VERSION ""

NS_ :

BS_:

BU_: TelemetryNode Master SENSOR PDU CLU BRAKE MLU_1 MLU_2 MLU_3 MLU_4 MLU_5 MLU_6

BO_ 3 SENSOR_IMU_ACCEL_Y: 4 SENSOR
 SG_ SENSOR_IMU_ACCEL_Y_SIGNAL : 0|32@1- (1,0) [-2147483648|2147483647] "" Vector__XXX

BO_ 1 SENSOR_Ready: 0 Vector__XXX

BO_ 0 SENSOR_HELLO_WORLD: 1 Vector__XXX

BO_ 2 CANzero_NMT: 4 Master
 SG_ CANzero_NMT_Node : 16|16@1+ (1,0) [0|63] ""  SENSOR,PDU,CLU,BRAKE,MLU_1,MLU_2,MLU_3,MLU_4,MLU_5,MLU_6
 SG_ CANzero_NMT_State : 0|16@1+ (1,0) [0|0] ""  SENSOR,PDU,CLU,BRAKE,MLU_1,MLU_2,MLU_3,MLU_4,MLU_5,MLU_6

BO_ 122 CANzero_Sync: 0 Master

BO_ 123 CANzero_Timestamp: 0 Master

BO_ 129 SENSOR_EMCY: 4 SENSOR
 SG_ SENSOR_E11_ANY_MLU_Timeout : 23|1@1+ (1,0) [0|0] ""  Master,TelemetryNode
 SG_ SENSOR_E10_MLU6_Timeout : 22|1@1+ (1,0) [0|0] ""  Master,TelemetryNode
 SG_ SENSOR_E9_MLU5_Timeout : 21|1@1+ (1,0) [0|0] ""  Master,TelemetryNode
 SG_ SENSOR_E8_MLU4_Timeout : 20|1@1+ (1,0) [0|0] ""  Master,TelemetryNode
 SG_ SENSOR_E7_MLU3_Timeout : 19|1@1+ (1,0) [0|0] ""  Master,TelemetryNode
 SG_ SENSOR_E6_MLU2_Timeout : 18|1@1+ (1,0) [0|0] ""  Master,TelemetryNode
 SG_ SENSOR_E5_MLU1_Timeout : 17|1@1+ (1,0) [0|0] ""  Master,TelemetryNode
 SG_ SENSOR_E4_CLU_Timeout : 16|1@1+ (1,0) [0|0] ""  Master,TelemetryNode
 SG_ SENSOR_E3_PDU_Timeout : 15|1@1+ (1,0) [0|0] ""  Master,TelemetryNode
 SG_ SENSOR_E2_BRAKE_Timeout : 14|1@1+ (1,0) [0|0] ""  Master,TelemetryNode
 SG_ SENSOR_E1_StateTransitionError : 13|1@1+ (1,0) [0|0] ""  Master,TelemetryNode
 SG_ SENSOR_E0_OtherError : 12|1@1+ (1,0) [0|0] ""  Master,TelemetryNode
 SG_ SENSOR_W4_PressureSensorPlausibi : 4|1@1+ (1,0) [0|0] ""  Master,TelemetryNode
 SG_ SENSOR_W3_TemperaturSensorPlausi : 3|1@1+ (1,0) [0|0] ""  Master,TelemetryNode
 SG_ SENSOR_W2_OnBoardOvervoltage : 2|1@1+ (1,0) [0|0] ""  Master,TelemetryNode
 SG_ SENSOR_W1_OnBoardOverheat : 1|1@1+ (1,0) [0|0] ""  Master,TelemetryNode
 SG_ SENSOR_W0_OtherWarning : 0|1@1+ (1,0) [0|0] ""  Master,TelemetryNode

BO_ 385 SENSOR_TX_PDO1: 0 SENSOR

BO_ 449 SENSOR_RX_PDO1: 0 Vector__XXX

BO_ 513 SENSOR_TX_PDO2: 0 SENSOR

BO_ 577 SENSOR_RX_PDO2: 0 Vector__XXX

BO_ 641 SENSOR_TX_PDO3: 0 SENSOR

BO_ 705 SENSOR_RX_PDO3: 0 Vector__XXX

BO_ 769 SENSOR_TX_PDO4: 0 SENSOR

BO_ 833 SENSOR_RX_PDO4: 0 Vector__XXX

BO_ 897 SENSOR_TX_PDO5: 0 SENSOR

BO_ 961 SENSOR_TX_PDO6: 0 SENSOR

BO_ 1025 SENSOR_TX_PDO7: 0 SENSOR

BO_ 1089 SENSOR_TX_PDO8: 0 SENSOR

BO_ 1153 SENSOR_TX_PDO9: 0 SENSOR

BO_ 1217 SENSOR_TX_PDO10: 0 SENSOR

BO_ 1281 SENSOR_TX_PDO11: 0 SENSOR

BO_ 1345 SENSOR_TX_PDO12: 0 SENSOR

BO_ 1409 SENSOR_SDO_Resp: 8 SENSOR
 SG_ SENSOR_OD_IMU3_Temperature m2599 : 16|16@1+ (0.01,-100) [-100|555.35] ""  TelemetryNode
 SG_ SENSOR_OD_IMU2_Temperature m2598 : 16|16@1+ (0.01,-100) [-100|555.35] ""  TelemetryNode
 SG_ SENSOR_OD_IMU1_Temperature m2597 : 16|16@1+ (0.01,-100) [-100|555.35] ""  TelemetryNode
 SG_ SENSOR_OD_IMU_number m2592 : 16|8@1+ (1,0) [0|255] ""  TelemetryNode
 SG_ SENSOR_OD_CAN2_DelayedTxMessages m1129 : 16|24@1+ (1,0) [0|16777215] ""  TelemetryNode
 SG_ SENSOR_OD_CAN2_ErrorStatus m1128 : 16|8@1+ (1,0) [0|255] ""  TelemetryNode
 SG_ SENSOR_OD_CAN2_DiscardedTxMessag m1127 : 16|24@1+ (1,0) [0|16777215] ""  TelemetryNode
 SG_ SENSOR_OD_CAN2_Status m1126 : 16|8@1+ (1,0) [0|255] ""  TelemetryNode
 SG_ SENSOR_OD_CAN2_Baudrate m1124 : 16|16@1+ (1,0) [125|1000] "kbps"  TelemetryNode
 SG_ SENSOR_OD_CAN2_autoErrorReset m1123 : 16|8@1+ (1,0) [0|255] ""  TelemetryNode
 SG_ SENSOR_OD_CAN2_lastErrorCode m1122 : 16|32@1+ (1,0) [0|4294967295] ""  TelemetryNode
 SG_ SENSOR_OD_CAN2_RxErrCnt m1121 : 16|8@1+ (1,0) [0|255] ""  TelemetryNode
 SG_ SENSOR_OD_CAN2_TxErrCnt m1120 : 16|8@1+ (1,0) [0|255] ""  TelemetryNode
 SG_ SENSOR_OD_CAN1_DelayedTxMessages m1113 : 16|24@1+ (1,0) [0|16777215] ""  TelemetryNode
 SG_ SENSOR_OD_CAN1_ErrorStatus m1112 : 16|8@1+ (1,0) [0|255] ""  TelemetryNode
 SG_ SENSOR_OD_CAN1_DiscardedTxMessag m1111 : 16|24@1+ (1,0) [0|16777215] ""  TelemetryNode
 SG_ SENSOR_OD_CAN1_Status m1110 : 16|8@1+ (1,0) [0|255] ""  TelemetryNode
 SG_ SENSOR_OD_CAN1_Baudrate m1108 : 16|16@1+ (1,0) [125|1000] "kbps"  TelemetryNode
 SG_ SENSOR_OD_CAN1_autoErrorReset m1107 : 16|8@1+ (1,0) [0|255] ""  TelemetryNode
 SG_ SENSOR_OD_CAN1_lastErrorCode m1106 : 16|32@1+ (1,0) [0|4294967295] ""  TelemetryNode
 SG_ SENSOR_OD_CAN1_RxErrCnt m1105 : 16|8@1+ (1,0) [0|255] ""  TelemetryNode
 SG_ SENSOR_OD_CAN1_TxErrCnt m1104 : 16|8@1+ (1,0) [0|255] ""  TelemetryNode
 SG_ SENSOR_OD_BuildTime m1073 : 16|24@1+ (1,0) [0|16777215] ""  TelemetryNode
 SG_ SENSOR_OD_BuildDate m1072 : 16|32@1+ (1,0) [0|4294967295] ""  TelemetryNode
 SG_ SENSOR_OD_ChipUID2 m1057 : 16|48@1+ (1,0) [0|281474976710655] ""  TelemetryNode
 SG_ SENSOR_OD_ChipUID1 m1056 : 16|48@1+ (1,0) [0|281474976710655] ""  TelemetryNode
 SG_ SENSOR_OD_SdcOut m1046 : 16|8@1+ (1,0) [0|255] ""  TelemetryNode
 SG_ SENSOR_OD_SdcIn m1045 : 16|8@1+ (1,0) [0|255] ""  TelemetryNode
 SG_ SENSOR_OD_runtime m1044 : 16|24@1+ (1,0) [0|16777215] "ms"  TelemetryNode
 SG_ SENSOR_OD_InputVoltage m1043 : 16|16@1+ (0.001,0) [0|65.535] "V"  TelemetryNode
 SG_ SENSOR_OD_BoardTemp m1042 : 16|16@1+ (0.01,-30) [-30|625.35] "°C"  TelemetryNode
 SG_ SENSOR_OD_MemFree m1041 : 16|16@1+ (4,0) [0|262140] "bytes"  TelemetryNode
 SG_ SENSOR_OD_CpuUsage m1040 : 16|8@1+ (0.5,0) [0|100] "%"  TelemetryNode
 SG_ SENSOR_OD_OdEntrySendInterval m33 : 16|16@1+ (1,0) [0|65535] "ms"  TelemetryNode
 SG_ SENSOR_OD_SendOdOnBootup m32 : 16|8@1+ (1,0) [0|255] ""  TelemetryNode
 SG_ SENSOR_OD_HeartbeatInterval m16 : 16|16@1+ (1,0) [0|65535] "ms"  TelemetryNode
 SG_ SENSOR_OD_DbcVersion m5 : 16|16@1+ (1,0) [0|65535] ""  TelemetryNode
 SG_ SENSOR_OD_StackVersion m4 : 16|16@1+ (1,0) [0|65535] ""  TelemetryNode
 SG_ SENSOR_OD_ProtocolVersion m3 : 16|16@1+ (1,0) [0|65535] ""  TelemetryNode
 SG_ SENSOR_OD_NodeStatus m2 : 16|8@1+ (1,0) [0|255] ""  TelemetryNode
 SG_ SENSOR_OD_NodeID m1 : 16|8@1+ (1,0) [0|255] ""  TelemetryNode
 SG_ SENSOR_SDO_RespCode : 12|4@1+ (1,0) [0|0] ""  TelemetryNode
 SG_ SENSOR_SDO_ID M : 0|12@1+ (1,0) [0|4095] ""  TelemetryNode

BO_ 1473 SENSOR_SDO_Req_Up: 8 TelemetryNode
 SG_ SENSOR_OD_IMU3_Temperature m2599 : 16|16@1+ (0.01,-100) [-100|555.35] ""  SENSOR
 SG_ SENSOR_OD_IMU2_Temperature m2598 : 16|16@1+ (0.01,-100) [-100|555.35] ""  SENSOR
 SG_ SENSOR_OD_IMU1_Temperature m2597 : 16|16@1+ (0.01,-100) [-100|555.35] ""  SENSOR
 SG_ SENSOR_OD_IMU_number m2592 : 16|8@1+ (1,0) [0|255] ""  SENSOR
 SG_ SENSOR_OD_CAN2_DelayedTxMessages m1129 : 16|24@1+ (1,0) [0|16777215] ""  SENSOR
 SG_ SENSOR_OD_CAN2_ErrorStatus m1128 : 16|8@1+ (1,0) [0|255] ""  SENSOR
 SG_ SENSOR_OD_CAN2_DiscardedTxM_0000 m1127 : 16|24@1+ (1,0) [0|16777215] ""  SENSOR
 SG_ SENSOR_OD_CAN2_Status m1126 : 16|8@1+ (1,0) [0|255] ""  SENSOR
 SG_ SENSOR_OD_CAN2_Baudrate m1124 : 16|16@1+ (1,0) [125|1000] "kbps"  SENSOR
 SG_ SENSOR_OD_CAN2_autoErrorReset m1123 : 16|8@1+ (1,0) [0|255] ""  SENSOR
 SG_ SENSOR_OD_CAN2_lastErrorCode m1122 : 16|32@1+ (1,0) [0|4294967295] ""  SENSOR
 SG_ SENSOR_OD_CAN2_RxErrCnt m1121 : 16|8@1+ (1,0) [0|255] ""  SENSOR
 SG_ SENSOR_OD_CAN2_TxErrCnt m1120 : 16|8@1+ (1,0) [0|255] ""  SENSOR
 SG_ SENSOR_OD_CAN1_DelayedTxMessages m1113 : 16|24@1+ (1,0) [0|16777215] ""  SENSOR
 SG_ SENSOR_OD_CAN1_ErrorStatus m1112 : 16|8@1+ (1,0) [0|255] ""  SENSOR
 SG_ SENSOR_OD_CAN1_DiscardedTxM_0000 m1111 : 16|24@1+ (1,0) [0|16777215] ""  SENSOR
 SG_ SENSOR_OD_CAN1_Status m1110 : 16|8@1+ (1,0) [0|255] ""  SENSOR
 SG_ SENSOR_OD_CAN1_Baudrate m1108 : 16|16@1+ (1,0) [125|1000] "kbps"  SENSOR
 SG_ SENSOR_OD_CAN1_autoErrorReset m1107 : 16|8@1+ (1,0) [0|255] ""  SENSOR
 SG_ SENSOR_OD_CAN1_lastErrorCode m1106 : 16|32@1+ (1,0) [0|4294967295] ""  SENSOR
 SG_ SENSOR_OD_CAN1_RxErrCnt m1105 : 16|8@1+ (1,0) [0|255] ""  SENSOR
 SG_ SENSOR_OD_CAN1_TxErrCnt m1104 : 16|8@1+ (1,0) [0|255] ""  SENSOR
 SG_ SENSOR_OD_BuildTime m1073 : 16|24@1+ (1,0) [0|16777215] ""  SENSOR
 SG_ SENSOR_OD_BuildDate m1072 : 16|32@1+ (1,0) [0|4294967295] ""  SENSOR
 SG_ SENSOR_OD_ChipUID2 m1057 : 16|48@1+ (1,0) [0|281474976710655] ""  SENSOR
 SG_ SENSOR_OD_ChipUID1 m1056 : 16|48@1+ (1,0) [0|281474976710655] ""  SENSOR
 SG_ SENSOR_OD_SdcOut m1046 : 16|8@1+ (1,0) [0|255] ""  SENSOR
 SG_ SENSOR_OD_SdcIn m1045 : 16|8@1+ (1,0) [0|255] ""  SENSOR
 SG_ SENSOR_OD_runtime m1044 : 16|24@1+ (1,0) [0|16777215] "ms"  SENSOR
 SG_ SENSOR_OD_InputVoltage m1043 : 16|16@1+ (0.001,0) [0|65.535] "V"  SENSOR
 SG_ SENSOR_OD_BoardTemp m1042 : 16|16@1+ (0.01,-30) [-30|625.35] "°C"  SENSOR
 SG_ SENSOR_OD_MemFree m1041 : 16|16@1+ (4,0) [0|262140] "bytes"  SENSOR
 SG_ SENSOR_OD_CpuUsage m1040 : 16|8@1+ (0.5,0) [0|100] "%"  SENSOR
 SG_ SENSOR_OD_OdEntrySendInterval m33 : 16|16@1+ (1,0) [0|65535] "ms"  SENSOR
 SG_ SENSOR_OD_SendOdOnBootup m32 : 16|8@1+ (1,0) [0|255] ""  SENSOR
 SG_ SENSOR_OD_HeartbeatInterval m16 : 16|16@1+ (1,0) [0|65535] "ms"  SENSOR
 SG_ SENSOR_OD_DbcVersion m5 : 16|16@1+ (1,0) [0|65535] ""  SENSOR
 SG_ SENSOR_OD_StackVersion m4 : 16|16@1+ (1,0) [0|65535] ""  SENSOR
 SG_ SENSOR_OD_ProtocolVersion m3 : 16|16@1+ (1,0) [0|65535] ""  SENSOR
 SG_ SENSOR_OD_NodeStatus m2 : 16|8@1+ (1,0) [0|255] ""  SENSOR
 SG_ SENSOR_OD_NodeID m1 : 16|8@1+ (1,0) [0|255] ""  SENSOR
 SG_ SENSOR_SDO_ID M : 0|12@1+ (1,0) [0|4095] ""  SENSOR

BO_ 1537 SENSOR_SDO_Req_Down: 2 TelemetryNode
 SG_ SENSOR_SDO_ID M : 0|12@1+ (1,0) [0|4095] ""  SENSOR

BO_ 1793 SENSOR_Heartbeat: 1 SENSOR
 SG_ SENSOR_NodeState : 0|8@1+ (1,0) [0|0] ""  Master,TelemetryNode

BO_ 1857 SENSOR_BTL_TX: 8 SENSOR

BO_ 1921 SENSOR_BTL_RX: 8 TelemetryNode

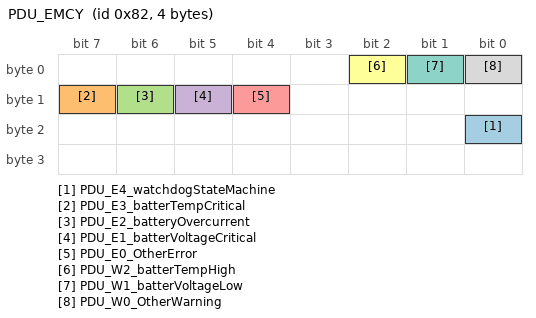
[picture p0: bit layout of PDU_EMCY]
BO_ 130 PDU_EMCY: 4 PDU
 SG_ PDU_E4_watchdogStateMachine : 16|1@1+ (1,0) [0|0] ""  Master,TelemetryNode
 SG_ PDU_E3_batterTempCritical : 15|1@1+ (1,0) [0|0] ""  Master,TelemetryNode
 SG_ PDU_E2_batteryOvercurrent : 14|1@1+ (1,0) [0|0] ""  Master,TelemetryNode
 SG_ PDU_E1_batterVoltageCritical : 13|1@1+ (1,0) [0|0] ""  Master,TelemetryNode
 SG_ PDU_E0_OtherError : 12|1@1+ (1,0) [0|0] ""  Master,TelemetryNode
 SG_ PDU_W2_batterTempHigh : 2|1@1+ (1,0) [0|0] ""  Master,TelemetryNode
 SG_ PDU_W1_batterVoltageLow : 1|1@1+ (1,0) [0|0] ""  Master,TelemetryNode
 SG_ PDU_W0_OtherWarning : 0|1@1+ (1,0) [0|0] ""  Master,TelemetryNode

BO_ 386 PDU_TX_PDO1: 0 PDU

BO_ 450 PDU_RX_PDO1: 0 Vector__XXX

BO_ 514 PDU_TX_PDO2: 0 PDU

BO_ 578 PDU_RX_PDO2: 0 Vector__XXX

BO_ 642 PDU_TX_PDO3: 0 PDU

BO_ 706 PDU_RX_PDO3: 0 Vector__XXX

BO_ 770 PDU_TX_PDO4: 0 PDU

BO_ 834 PDU_RX_PDO4: 0 Vector__XXX

BO_ 898 PDU_TX_PDO5: 0 PDU

BO_ 962 PDU_TX_PDO6: 0 PDU

BO_ 1026 PDU_TX_PDO7: 0 PDU

BO_ 1090 PDU_TX_PDO8: 0 PDU

BO_ 1154 PDU_TX_PDO9: 0 PDU

BO_ 1218 PDU_TX_PDO10: 0 PDU

BO_ 1282 PDU_TX_PDO11: 0 PDU

BO_ 1346 PDU_TX_PDO12: 0 PDU

BO_ 1410 PDU_SDO_Resp: 8 PDU
 SG_ PDU_OD_CoolingPumpEnabled m2816 : 16|8@1+ (1,0) [0|255] ""  TelemetryNode
 SG_ PDU_OD_LedCommands m2562 : 16|16@1+ (1,0) [0|65535] ""  TelemetryNode
 SG_ PDU_OD_projectXXEnabled m2560 : 16|8@1+ (1,0) [0|255] ""  TelemetryNode
 SG_ PDU_OD_watchdogTimeout m2306 : 16|16@1+ (1,0) [0|65535] "ms"  TelemetryNode
 SG_ PDU_OD_statusSendInterval m2305 : 16|16@1+ (1,0) [0|65535] "ms"  TelemetryNode
 SG_ PDU_OD_currentReadInterval m2304 : 16|16@1+ (1,0) [0|65535] "ms"  TelemetryNode
 SG_ PDU_OD_batteryOvercurrent m2128 : 16|16@1+ (0.01,0) [0|655.35] "A"  TelemetryNode
 SG_ PDU_OD_overTempCritical m2051 : 16|16@1+ (0.1,0) [0|6553.5] "degrees"  TelemetryNode
 SG_ PDU_OD_overTempWarn m2050 : 16|16@1+ (0.1,0) [0|6553.5] "degrees"  TelemetryNode
 SG_ PDU_OD_batterVoltageCritical m2049 : 16|16@1+ (0.01,0) [0|655.35] "V"  TelemetryNode
 SG_ PDU_OD_batterVoltageLow m2048 : 16|16@1+ (0.01,0) [0|655.35] "V"  TelemetryNode
 SG_ PDU_OD_CAN2_DelayedTxMessages m1129 : 16|24@1+ (1,0) [0|16777215] ""  TelemetryNode
 SG_ PDU_OD_CAN2_ErrorStatus m1128 : 16|8@1+ (1,0) [0|255] ""  TelemetryNode
 SG_ PDU_OD_CAN2_DiscardedTxMessages m1127 : 16|24@1+ (1,0) [0|16777215] ""  TelemetryNode
 SG_ PDU_OD_CAN2_Status m1126 : 16|8@1+ (1,0) [0|255] ""  TelemetryNode
 SG_ PDU_OD_CAN2_Baudrate m1124 : 16|16@1+ (1,0) [125|1000] "kbps"  TelemetryNode
 SG_ PDU_OD_CAN2_autoErrorReset m1123 : 16|8@1+ (1,0) [0|255] ""  TelemetryNode
 SG_ PDU_OD_CAN2_lastErrorCode m1122 : 16|32@1+ (1,0) [0|4294967295] ""  TelemetryNode
 SG_ PDU_OD_CAN2_RxErrCnt m1121 : 16|8@1+ (1,0) [0|255] ""  TelemetryNode
 SG_ PDU_OD_CAN2_TxErrCnt m1120 : 16|8@1+ (1,0) [0|255] ""  TelemetryNode
 SG_ PDU_OD_CAN1_DelayedTxMessages m1113 : 16|24@1+ (1,0) [0|16777215] ""  TelemetryNode
 SG_ PDU_OD_CAN1_ErrorStatus m1112 : 16|8@1+ (1,0) [0|255] ""  TelemetryNode
 SG_ PDU_OD_CAN1_DiscardedTxMessages m1111 : 16|24@1+ (1,0) [0|16777215] ""  TelemetryNode
 SG_ PDU_OD_CAN1_Status m1110 : 16|8@1+ (1,0) [0|255] ""  TelemetryNode
 SG_ PDU_OD_CAN1_Baudrate m1108 : 16|16@1+ (1,0) [125|1000] "kbps"  TelemetryNode
 SG_ PDU_OD_CAN1_autoErrorReset m1107 : 16|8@1+ (1,0) [0|255] ""  TelemetryNode
 SG_ PDU_OD_CAN1_lastErrorCode m1106 : 16|32@1+ (1,0) [0|4294967295] ""  TelemetryNode
 SG_ PDU_OD_CAN1_RxErrCnt m1105 : 16|8@1+ (1,0) [0|255] ""  TelemetryNode
 SG_ PDU_OD_CAN1_TxErrCnt m1104 : 16|8@1+ (1,0) [0|255] ""  TelemetryNode
 SG_ PDU_OD_BuildTime m1073 : 16|24@1+ (1,0) [0|16777215] ""  TelemetryNode
 SG_ PDU_OD_BuildDate m1072 : 16|32@1+ (1,0) [0|4294967295] ""  TelemetryNode
 SG_ PDU_OD_ChipUID2 m1057 : 16|48@1+ (1,0) [0|281474976710655] ""  TelemetryNode
 SG_ PDU_OD_ChipUID1 m1056 : 16|48@1+ (1,0) [0|281474976710655] ""  TelemetryNode
 SG_ PDU_OD_SdcOut m1046 : 16|8@1+ (1,0) [0|255] ""  TelemetryNode
 SG_ PDU_OD_SdcIn m1045 : 16|8@1+ (1,0) [0|255] ""  TelemetryNode
 SG_ PDU_OD_runtime m1044 : 16|24@1+ (1,0) [0|16777215] "ms"  TelemetryNode
 SG_ PDU_OD_InputVoltage m1043 : 16|16@1+ (0.001,0) [0|65.535] "V"  TelemetryNode
 SG_ PDU_OD_BoardTemp m1042 : 16|16@1+ (0.01,-30) [-30|625.35] "°C"  TelemetryNode
 SG_ PDU_OD_MemFree m1041 : 16|16@1+ (4,0) [0|262140] "bytes"  TelemetryNode
 SG_ PDU_OD_CpuUsage m1040 : 16|8@1+ (0.5,0) [0|100] "%"  TelemetryNode
 SG_ PDU_OD_OdEntrySendInterval m33 : 16|16@1+ (1,0) [0|65535] "ms"  TelemetryNode
 SG_ PDU_OD_SendOdOnBootup m32 : 16|8@1+ (1,0) [0|255] ""  TelemetryNode
 SG_ PDU_OD_HeartbeatInterval m16 : 16|16@1+ (1,0) [0|65535] "ms"  TelemetryNode
 SG_ PDU_OD_DbcVersion m5 : 16|16@1+ (1,0) [0|65535] ""  TelemetryNode
 SG_ PDU_OD_StackVersion m4 : 16|16@1+ (1,0) [0|65535] ""  TelemetryNode
 SG_ PDU_OD_ProtocolVersion m3 : 16|16@1+ (1,0) [0|65535] ""  TelemetryNode
 SG_ PDU_OD_NodeStatus m2 : 16|8@1+ (1,0) [0|255] ""  TelemetryNode
 SG_ PDU_OD_NodeID m1 : 16|8@1+ (1,0) [0|255] ""  TelemetryNode
 SG_ PDU_SDO_RespCode : 12|4@1+ (1,0) [0|0] ""  TelemetryNode
 SG_ PDU_SDO_ID M : 0|12@1+ (1,0) [0|4095] ""  TelemetryNode

BO_ 1474 PDU_SDO_Req_Up: 8 TelemetryNode
 SG_ PDU_OD_CoolingPumpEnabled m2816 : 16|8@1+ (1,0) [0|255] ""  PDU
 SG_ PDU_OD_LedCommands m2562 : 16|16@1+ (1,0) [0|65535] ""  PDU
 SG_ PDU_OD_projectXXEnabled m2560 : 16|8@1+ (1,0) [0|255] ""  PDU
 SG_ PDU_OD_watchdogTimeout m2306 : 16|16@1+ (1,0) [0|65535] "ms"  PDU
 SG_ PDU_OD_statusSendInterval m2305 : 16|16@1+ (1,0) [0|65535] "ms"  PDU
 SG_ PDU_OD_currentReadInterval m2304 : 16|16@1+ (1,0) [0|65535] "ms"  PDU
 SG_ PDU_OD_batteryOvercurrent m2128 : 16|16@1+ (0.01,0) [0|655.35] "A"  PDU
 SG_ PDU_OD_overTempCritical m2051 : 16|16@1+ (0.1,0) [0|6553.5] "degrees"  PDU
 SG_ PDU_OD_overTempWarn m2050 : 16|16@1+ (0.1,0) [0|6553.5] "degrees"  PDU
 SG_ PDU_OD_batterVoltageCritical m2049 : 16|16@1+ (0.01,0) [0|655.35] "V"  PDU
 SG_ PDU_OD_batterVoltageLow m2048 : 16|16@1+ (0.01,0) [0|655.35] "V"  PDU
 SG_ PDU_OD_CAN2_DelayedTxMessages m1129 : 16|24@1+ (1,0) [0|16777215] ""  PDU
 SG_ PDU_OD_CAN2_ErrorStatus m1128 : 16|8@1+ (1,0) [0|255] ""  PDU
 SG_ PDU_OD_CAN2_DiscardedTxMessages m1127 : 16|24@1+ (1,0) [0|16777215] ""  PDU
 SG_ PDU_OD_CAN2_Status m1126 : 16|8@1+ (1,0) [0|255] ""  PDU
 SG_ PDU_OD_CAN2_Baudrate m1124 : 16|16@1+ (1,0) [125|1000] "kbps"  PDU
 SG_ PDU_OD_CAN2_autoErrorReset m1123 : 16|8@1+ (1,0) [0|255] ""  PDU
 SG_ PDU_OD_CAN2_lastErrorCode m1122 : 16|32@1+ (1,0) [0|4294967295] ""  PDU
 SG_ PDU_OD_CAN2_RxErrCnt m1121 : 16|8@1+ (1,0) [0|255] ""  PDU
 SG_ PDU_OD_CAN2_TxErrCnt m1120 : 16|8@1+ (1,0) [0|255] ""  PDU
 SG_ PDU_OD_CAN1_DelayedTxMessages m1113 : 16|24@1+ (1,0) [0|16777215] ""  PDU
 SG_ PDU_OD_CAN1_ErrorStatus m1112 : 16|8@1+ (1,0) [0|255] ""  PDU
 SG_ PDU_OD_CAN1_DiscardedTxMessages m1111 : 16|24@1+ (1,0) [0|16777215] ""  PDU
 SG_ PDU_OD_CAN1_Status m1110 : 16|8@1+ (1,0) [0|255] ""  PDU
 SG_ PDU_OD_CAN1_Baudrate m1108 : 16|16@1+ (1,0) [125|1000] "kbps"  PDU
 SG_ PDU_OD_CAN1_autoErrorReset m1107 : 16|8@1+ (1,0) [0|255] ""  PDU
 SG_ PDU_OD_CAN1_lastErrorCode m1106 : 16|32@1+ (1,0) [0|4294967295] ""  PDU
 SG_ PDU_OD_CAN1_RxErrCnt m1105 : 16|8@1+ (1,0) [0|255] ""  PDU
 SG_ PDU_OD_CAN1_TxErrCnt m1104 : 16|8@1+ (1,0) [0|255] ""  PDU
 SG_ PDU_OD_BuildTime m1073 : 16|24@1+ (1,0) [0|16777215] ""  PDU
 SG_ PDU_OD_BuildDate m1072 : 16|32@1+ (1,0) [0|4294967295] ""  PDU
 SG_ PDU_OD_ChipUID2 m1057 : 16|48@1+ (1,0) [0|281474976710655] ""  PDU
 SG_ PDU_OD_ChipUID1 m1056 : 16|48@1+ (1,0) [0|281474976710655] ""  PDU
 SG_ PDU_OD_SdcOut m1046 : 16|8@1+ (1,0) [0|255] ""  PDU
 SG_ PDU_OD_SdcIn m1045 : 16|8@1+ (1,0) [0|255] ""  PDU
 SG_ PDU_OD_runtime m1044 : 16|24@1+ (1,0) [0|16777215] "ms"  PDU
 SG_ PDU_OD_InputVoltage m1043 : 16|16@1+ (0.001,0) [0|65.535] "V"  PDU
 SG_ PDU_OD_BoardTemp m1042 : 16|16@1+ (0.01,-30) [-30|625.35] "°C"  PDU
 SG_ PDU_OD_MemFree m1041 : 16|16@1+ (4,0) [0|262140] "bytes"  PDU
 SG_ PDU_OD_CpuUsage m1040 : 16|8@1+ (0.5,0) [0|100] "%"  PDU
 SG_ PDU_OD_OdEntrySendInterval m33 : 16|16@1+ (1,0) [0|65535] "ms"  PDU
 SG_ PDU_OD_SendOdOnBootup m32 : 16|8@1+ (1,0) [0|255] ""  PDU
 SG_ PDU_OD_HeartbeatInterval m16 : 16|16@1+ (1,0) [0|65535] "ms"  PDU
 SG_ PDU_OD_DbcVersion m5 : 16|16@1+ (1,0) [0|65535] ""  PDU
 SG_ PDU_OD_StackVersion m4 : 16|16@1+ (1,0) [0|65535] ""  PDU
 SG_ PDU_OD_ProtocolVersion m3 : 16|16@1+ (1,0) [0|65535] ""  PDU
 SG_ PDU_OD_NodeStatus m2 : 16|8@1+ (1,0) [0|255] ""  PDU
 SG_ PDU_OD_NodeID m1 : 16|8@1+ (1,0) [0|255] ""  PDU
 SG_ PDU_SDO_ID M : 0|12@1+ (1,0) [0|4095] ""  PDU

BO_ 1538 PDU_SDO_Req_Down: 2 TelemetryNode
 SG_ PDU_SDO_ID M : 0|12@1+ (1,0) [0|4095] ""  PDU

BO_ 1794 PDU_Heartbeat: 1 PDU
 SG_ PDU_NodeState : 0|8@1+ (1,0) [0|0] ""  Master,TelemetryNode

BO_ 1858 PDU_BTL_TX: 8 PDU

BO_ 1922 PDU_BTL_RX: 8 TelemetryNode

BO_ 131 CLU_EMCY: 4 CLU
 SG_ CLU_E0_OtherError : 12|1@1+ (1,0) [0|0] ""  Master,TelemetryNode
 SG_ CLU_W0_OtherWarning : 0|1@1+ (1,0) [0|0] ""  Master,TelemetryNode

BO_ 387 CLU_TX_PDO1: 0 CLU

BO_ 451 CLU_RX_PDO1: 0 Vector__XXX

BO_ 515 CLU_TX_PDO2: 0 CLU

BO_ 579 CLU_RX_PDO2: 0 Vector__XXX

BO_ 643 CLU_TX_PDO3: 0 CLU

BO_ 707 CLU_RX_PDO3: 0 Vector__XXX

BO_ 771 CLU_TX_PDO4: 0 CLU

BO_ 835 CLU_RX_PDO4: 0 Vector__XXX

BO_ 899 CLU_TX_PDO5: 0 CLU

BO_ 963 CLU_TX_PDO6: 0 CLU

BO_ 1027 CLU_TX_PDO7: 0 CLU

BO_ 1091 CLU_TX_PDO8: 0 CLU

BO_ 1155 CLU_TX_PDO9: 0 CLU

BO_ 1219 CLU_TX_PDO10: 0 CLU

BO_ 1283 CLU_TX_PDO11: 0 CLU

BO_ 1347 CLU_TX_PDO12: 0 CLU

BO_ 1411 CLU_SDO_Resp: 8 CLU
 SG_ CLU_OD_CAN2_DelayedTxMessages m1129 : 16|24@1+ (1,0) [0|16777215] ""  TelemetryNode
 SG_ CLU_OD_CAN2_ErrorStatus m1128 : 16|8@1+ (1,0) [0|255] ""  TelemetryNode
 SG_ CLU_OD_CAN2_DiscardedTxMessages m1127 : 16|24@1+ (1,0) [0|16777215] ""  TelemetryNode
 SG_ CLU_OD_CAN2_Status m1126 : 16|8@1+ (1,0) [0|255] ""  TelemetryNode
 SG_ CLU_OD_CAN2_Baudrate m1124 : 16|16@1+ (1,0) [125|1000] "kbps"  TelemetryNode
 SG_ CLU_OD_CAN2_autoErrorReset m1123 : 16|8@1+ (1,0) [0|255] ""  TelemetryNode
 SG_ CLU_OD_CAN2_lastErrorCode m1122 : 16|32@1+ (1,0) [0|4294967295] ""  TelemetryNode
 SG_ CLU_OD_CAN2_RxErrCnt m1121 : 16|8@1+ (1,0) [0|255] ""  TelemetryNode
 SG_ CLU_OD_CAN2_TxErrCnt m1120 : 16|8@1+ (1,0) [0|255] ""  TelemetryNode
 SG_ CLU_OD_CAN1_DelayedTxMessages m1113 : 16|24@1+ (1,0) [0|16777215] ""  TelemetryNode
 SG_ CLU_OD_CAN1_ErrorStatus m1112 : 16|8@1+ (1,0) [0|255] ""  TelemetryNode
 SG_ CLU_OD_CAN1_DiscardedTxMessages m1111 : 16|24@1+ (1,0) [0|16777215] ""  TelemetryNode
 SG_ CLU_OD_CAN1_Status m1110 : 16|8@1+ (1,0) [0|255] ""  TelemetryNode
 SG_ CLU_OD_CAN1_Baudrate m1108 : 16|16@1+ (1,0) [125|1000] "kbps"  TelemetryNode
 SG_ CLU_OD_CAN1_autoErrorReset m1107 : 16|8@1+ (1,0) [0|255] ""  TelemetryNode
 SG_ CLU_OD_CAN1_lastErrorCode m1106 : 16|32@1+ (1,0) [0|4294967295] ""  TelemetryNode
 SG_ CLU_OD_CAN1_RxErrCnt m1105 : 16|8@1+ (1,0) [0|255] ""  TelemetryNode
 SG_ CLU_OD_CAN1_TxErrCnt m1104 : 16|8@1+ (1,0) [0|255] ""  TelemetryNode
 SG_ CLU_OD_BuildTime m1073 : 16|24@1+ (1,0) [0|16777215] ""  TelemetryNode
 SG_ CLU_OD_BuildDate m1072 : 16|32@1+ (1,0) [0|4294967295] ""  TelemetryNode
 SG_ CLU_OD_ChipUID2 m1057 : 16|48@1+ (1,0) [0|281474976710655] ""  TelemetryNode
 SG_ CLU_OD_ChipUID1 m1056 : 16|48@1+ (1,0) [0|281474976710655] ""  TelemetryNode
 SG_ CLU_OD_SdcOut m1046 : 16|8@1+ (1,0) [0|255] ""  TelemetryNode
 SG_ CLU_OD_SdcIn m1045 : 16|8@1+ (1,0) [0|255] ""  TelemetryNode
 SG_ CLU_OD_runtime m1044 : 16|24@1+ (1,0) [0|16777215] "ms"  TelemetryNode
 SG_ CLU_OD_InputVoltage m1043 : 16|16@1+ (0.001,0) [0|65.535] "V"  TelemetryNode
 SG_ CLU_OD_BoardTemp m1042 : 16|16@1+ (0.01,-30) [-30|625.35] "°C"  TelemetryNode
 SG_ CLU_OD_MemFree m1041 : 16|16@1+ (4,0) [0|262140] "bytes"  TelemetryNode
 SG_ CLU_OD_CpuUsage m1040 : 16|8@1+ (0.5,0) [0|100] "%"  TelemetryNode
 SG_ CLU_OD_OdEntrySendInterval m33 : 16|16@1+ (1,0) [0|65535] "ms"  TelemetryNode
 SG_ CLU_OD_SendOdOnBootup m32 : 16|8@1+ (1,0) [0|255] ""  TelemetryNode
 SG_ CLU_OD_HeartbeatInterval m16 : 16|16@1+ (1,0) [0|65535] "ms"  TelemetryNode
 SG_ CLU_OD_DbcVersion m5 : 16|16@1+ (1,0) [0|65535] ""  TelemetryNode
 SG_ CLU_OD_StackVersion m4 : 16|16@1+ (1,0) [0|65535] ""  TelemetryNode
 SG_ CLU_OD_ProtocolVersion m3 : 16|16@1+ (1,0) [0|65535] ""  TelemetryNode
 SG_ CLU_OD_NodeStatus m2 : 16|8@1+ (1,0) [0|255] ""  TelemetryNode
 SG_ CLU_OD_NodeID m1 : 16|8@1+ (1,0) [0|255] ""  TelemetryNode
 SG_ CLU_SDO_RespCode : 12|4@1+ (1,0) [0|0] ""  TelemetryNode
 SG_ CLU_SDO_ID M : 0|12@1+ (1,0) [0|4095] ""  TelemetryNode

BO_ 1475 CLU_SDO_Req_Up: 8 TelemetryNode
 SG_ CLU_OD_CAN2_DelayedTxMessages m1129 : 16|24@1+ (1,0) [0|16777215] ""  CLU
 SG_ CLU_OD_CAN2_ErrorStatus m1128 : 16|8@1+ (1,0) [0|255] ""  CLU
 SG_ CLU_OD_CAN2_DiscardedTxMessages m1127 : 16|24@1+ (1,0) [0|16777215] ""  CLU
 SG_ CLU_OD_CAN2_Status m1126 : 16|8@1+ (1,0) [0|255] ""  CLU
 SG_ CLU_OD_CAN2_Baudrate m1124 : 16|16@1+ (1,0) [125|1000] "kbps"  CLU
 SG_ CLU_OD_CAN2_autoErrorReset m1123 : 16|8@1+ (1,0) [0|255] ""  CLU
 SG_ CLU_OD_CAN2_lastErrorCode m1122 : 16|32@1+ (1,0) [0|4294967295] ""  CLU
 SG_ CLU_OD_CAN2_RxErrCnt m1121 : 16|8@1+ (1,0) [0|255] ""  CLU
 SG_ CLU_OD_CAN2_TxErrCnt m1120 : 16|8@1+ (1,0) [0|255] ""  CLU
 SG_ CLU_OD_CAN1_DelayedTxMessages m1113 : 16|24@1+ (1,0) [0|16777215] ""  CLU
 SG_ CLU_OD_CAN1_ErrorStatus m1112 : 16|8@1+ (1,0) [0|255] ""  CLU
 SG_ CLU_OD_CAN1_DiscardedTxMessages m1111 : 16|24@1+ (1,0) [0|16777215] ""  CLU
 SG_ CLU_OD_CAN1_Status m1110 : 16|8@1+ (1,0) [0|255] ""  CLU
 SG_ CLU_OD_CAN1_Baudrate m1108 : 16|16@1+ (1,0) [125|1000] "kbps"  CLU
 SG_ CLU_OD_CAN1_autoErrorReset m1107 : 16|8@1+ (1,0) [0|255] ""  CLU
 SG_ CLU_OD_CAN1_lastErrorCode m1106 : 16|32@1+ (1,0) [0|4294967295] ""  CLU
 SG_ CLU_OD_CAN1_RxErrCnt m1105 : 16|8@1+ (1,0) [0|255] ""  CLU
 SG_ CLU_OD_CAN1_TxErrCnt m1104 : 16|8@1+ (1,0) [0|255] ""  CLU
 SG_ CLU_OD_BuildTime m1073 : 16|24@1+ (1,0) [0|16777215] ""  CLU
 SG_ CLU_OD_BuildDate m1072 : 16|32@1+ (1,0) [0|4294967295] ""  CLU
 SG_ CLU_OD_ChipUID2 m1057 : 16|48@1+ (1,0) [0|281474976710655] ""  CLU
 SG_ CLU_OD_ChipUID1 m1056 : 16|48@1+ (1,0) [0|281474976710655] ""  CLU
 SG_ CLU_OD_SdcOut m1046 : 16|8@1+ (1,0) [0|255] ""  CLU
 SG_ CLU_OD_SdcIn m1045 : 16|8@1+ (1,0) [0|255] ""  CLU
 SG_ CLU_OD_runtime m1044 : 16|24@1+ (1,0) [0|16777215] "ms"  CLU
 SG_ CLU_OD_InputVoltage m1043 : 16|16@1+ (0.001,0) [0|65.535] "V"  CLU
 SG_ CLU_OD_BoardTemp m1042 : 16|16@1+ (0.01,-30) [-30|625.35] "°C"  CLU
 SG_ CLU_OD_MemFree m1041 : 16|16@1+ (4,0) [0|262140] "bytes"  CLU
 SG_ CLU_OD_CpuUsage m1040 : 16|8@1+ (0.5,0) [0|100] "%"  CLU
 SG_ CLU_OD_OdEntrySendInterval m33 : 16|16@1+ (1,0) [0|65535] "ms"  CLU
 SG_ CLU_OD_SendOdOnBootup m32 : 16|8@1+ (1,0) [0|255] ""  CLU
 SG_ CLU_OD_HeartbeatInterval m16 : 16|16@1+ (1,0) [0|65535] "ms"  CLU
 SG_ CLU_OD_DbcVersion m5 : 16|16@1+ (1,0) [0|65535] ""  CLU
 SG_ CLU_OD_StackVersion m4 : 16|16@1+ (1,0) [0|65535] ""  CLU
 SG_ CLU_OD_ProtocolVersion m3 : 16|16@1+ (1,0) [0|65535] ""  CLU
 SG_ CLU_OD_NodeStatus m2 : 16|8@1+ (1,0) [0|255] ""  CLU
 SG_ CLU_OD_NodeID m1 : 16|8@1+ (1,0) [0|255] ""  CLU
 SG_ CLU_SDO_ID M : 0|12@1+ (1,0) [0|4095] ""  CLU

BO_ 1539 CLU_SDO_Req_Down: 2 TelemetryNode
 SG_ CLU_SDO_ID M : 0|12@1+ (1,0) [0|4095] ""  CLU

BO_ 1795 CLU_Heartbeat: 1 CLU
 SG_ CLU_NodeState : 0|8@1+ (1,0) [0|0] ""  Master,TelemetryNode

BO_ 1859 CLU_BTL_TX: 8 CLU

BO_ 1923 CLU_BTL_RX: 8 TelemetryNode

BO_ 132 BRAKE_EMCY: 4 BRAKE
 SG_ BRAKE_E0_OtherError : 12|1@1+ (1,0) [0|0] ""  Master,TelemetryNode
 SG_ BRAKE_W0_OtherWarning : 0|1@1+ (1,0) [0|0] ""  Master,TelemetryNode

BO_ 388 BRAKE_TX_PDO1: 0 BRAKE

BO_ 452 BRAKE_RX_PDO1: 0 Vector__XXX

BO_ 516 BRAKE_TX_PDO2: 0 BRAKE

BO_ 580 BRAKE_RX_PDO2: 0 Vector__XXX

BO_ 644 BRAKE_TX_PDO3: 0 BRAKE

BO_ 708 BRAKE_RX_PDO3: 0 Vector__XXX

BO_ 772 BRAKE_TX_PDO4: 0 BRAKE

BO_ 836 BRAKE_RX_PDO4: 0 Vector__XXX

BO_ 900 BRAKE_TX_PDO5: 0 BRAKE

BO_ 964 BRAKE_TX_PDO6: 0 BRAKE

BO_ 1028 BRAKE_TX_PDO7: 0 BRAKE

BO_ 1092 BRAKE_TX_PDO8: 0 BRAKE

BO_ 1156 BRAKE_TX_PDO9: 0 BRAKE

BO_ 1220 BRAKE_TX_PDO10: 0 BRAKE

BO_ 1284 BRAKE_TX_PDO11: 0 BRAKE

BO_ 1348 BRAKE_TX_PDO12: 0 BRAKE

BO_ 1412 BRAKE_SDO_Resp: 8 BRAKE
 SG_ BRAKE_OD_CAN2_DelayedTxMessages m1129 : 16|24@1+ (1,0) [0|16777215] ""  TelemetryNode
 SG_ BRAKE_OD_CAN2_ErrorStatus m1128 : 16|8@1+ (1,0) [0|255] ""  TelemetryNode
 SG_ BRAKE_OD_CAN2_DiscardedTxMessage m1127 : 16|24@1+ (1,0) [0|16777215] ""  TelemetryNode
 SG_ BRAKE_OD_CAN2_Status m1126 : 16|8@1+ (1,0) [0|255] ""  TelemetryNode
 SG_ BRAKE_OD_CAN2_Baudrate m1124 : 16|16@1+ (1,0) [125|1000] "kbps"  TelemetryNode
 SG_ BRAKE_OD_CAN2_autoErrorReset m1123 : 16|8@1+ (1,0) [0|255] ""  TelemetryNode
 SG_ BRAKE_OD_CAN2_lastErrorCode m1122 : 16|32@1+ (1,0) [0|4294967295] ""  TelemetryNode
 SG_ BRAKE_OD_CAN2_RxErrCnt m1121 : 16|8@1+ (1,0) [0|255] ""  TelemetryNode
 SG_ BRAKE_OD_CAN2_TxErrCnt m1120 : 16|8@1+ (1,0) [0|255] ""  TelemetryNode
 SG_ BRAKE_OD_CAN1_DelayedTxMessages m1113 : 16|24@1+ (1,0) [0|16777215] ""  TelemetryNode
 SG_ BRAKE_OD_CAN1_ErrorStatus m1112 : 16|8@1+ (1,0) [0|255] ""  TelemetryNode
 SG_ BRAKE_OD_CAN1_DiscardedTxMessage m1111 : 16|24@1+ (1,0) [0|16777215] ""  TelemetryNode
 SG_ BRAKE_OD_CAN1_Status m1110 : 16|8@1+ (1,0) [0|255] ""  TelemetryNode
 SG_ BRAKE_OD_CAN1_Baudrate m1108 : 16|16@1+ (1,0) [125|1000] "kbps"  TelemetryNode
 SG_ BRAKE_OD_CAN1_autoErrorReset m1107 : 16|8@1+ (1,0) [0|255] ""  TelemetryNode
 SG_ BRAKE_OD_CAN1_lastErrorCode m1106 : 16|32@1+ (1,0) [0|4294967295] ""  TelemetryNode
 SG_ BRAKE_OD_CAN1_RxErrCnt m1105 : 16|8@1+ (1,0) [0|255] ""  TelemetryNode
 SG_ BRAKE_OD_CAN1_TxErrCnt m1104 : 16|8@1+ (1,0) [0|255] ""  TelemetryNode
 SG_ BRAKE_OD_BuildTime m1073 : 16|24@1+ (1,0) [0|16777215] ""  TelemetryNode
 SG_ BRAKE_OD_BuildDate m1072 : 16|32@1+ (1,0) [0|4294967295] ""  TelemetryNode
 SG_ BRAKE_OD_ChipUID2 m1057 : 16|48@1+ (1,0) [0|281474976710655] ""  TelemetryNode
 SG_ BRAKE_OD_ChipUID1 m1056 : 16|48@1+ (1,0) [0|281474976710655] ""  TelemetryNode
 SG_ BRAKE_OD_SdcOut m1046 : 16|8@1+ (1,0) [0|255] ""  TelemetryNode
 SG_ BRAKE_OD_SdcIn m1045 : 16|8@1+ (1,0) [0|255] ""  TelemetryNode
 SG_ BRAKE_OD_runtime m1044 : 16|24@1+ (1,0) [0|16777215] "ms"  TelemetryNode
 SG_ BRAKE_OD_InputVoltage m1043 : 16|16@1+ (0.001,0) [0|65.535] "V"  TelemetryNode
 SG_ BRAKE_OD_BoardTemp m1042 : 16|16@1+ (0.01,-30) [-30|625.35] "°C"  TelemetryNode
 SG_ BRAKE_OD_MemFree m1041 : 16|16@1+ (4,0) [0|262140] "bytes"  TelemetryNode
 SG_ BRAKE_OD_CpuUsage m1040 : 16|8@1+ (0.5,0) [0|100] "%"  TelemetryNode
 SG_ BRAKE_OD_OdEntrySendInterval m33 : 16|16@1+ (1,0) [0|65535] "ms"  TelemetryNode
 SG_ BRAKE_OD_SendOdOnBootup m32 : 16|8@1+ (1,0) [0|255] ""  TelemetryNode
 SG_ BRAKE_OD_HeartbeatInterval m16 : 16|16@1+ (1,0) [0|65535] "ms"  TelemetryNode
 SG_ BRAKE_OD_DbcVersion m5 : 16|16@1+ (1,0) [0|65535] ""  TelemetryNode
 SG_ BRAKE_OD_StackVersion m4 : 16|16@1+ (1,0) [0|65535] ""  TelemetryNode
 SG_ BRAKE_OD_ProtocolVersion m3 : 16|16@1+ (1,0) [0|65535] ""  TelemetryNode
 SG_ BRAKE_OD_NodeStatus m2 : 16|8@1+ (1,0) [0|255] ""  TelemetryNode
 SG_ BRAKE_OD_NodeID m1 : 16|8@1+ (1,0) [0|255] ""  TelemetryNode
 SG_ BRAKE_SDO_RespCode : 12|4@1+ (1,0) [0|0] ""  TelemetryNode
 SG_ BRAKE_SDO_ID M : 0|12@1+ (1,0) [0|4095] ""  TelemetryNode

BO_ 1476 BRAKE_SDO_Req_Up: 8 TelemetryNode
 SG_ BRAKE_OD_CAN2_DelayedTxMessages m1129 : 16|24@1+ (1,0) [0|16777215] ""  BRAKE
 SG_ BRAKE_OD_CAN2_ErrorStatus m1128 : 16|8@1+ (1,0) [0|255] ""  BRAKE
 SG_ BRAKE_OD_CAN2_DiscardedTxMe_0000 m1127 : 16|24@1+ (1,0) [0|16777215] ""  BRAKE
 SG_ BRAKE_OD_CAN2_Status m1126 : 16|8@1+ (1,0) [0|255] ""  BRAKE
 SG_ BRAKE_OD_CAN2_Baudrate m1124 : 16|16@1+ (1,0) [125|1000] "kbps"  BRAKE
 SG_ BRAKE_OD_CAN2_autoErrorReset m1123 : 16|8@1+ (1,0) [0|255] ""  BRAKE
 SG_ BRAKE_OD_CAN2_lastErrorCode m1122 : 16|32@1+ (1,0) [0|4294967295] ""  BRAKE
 SG_ BRAKE_OD_CAN2_RxErrCnt m1121 : 16|8@1+ (1,0) [0|255] ""  BRAKE
 SG_ BRAKE_OD_CAN2_TxErrCnt m1120 : 16|8@1+ (1,0) [0|255] ""  BRAKE
 SG_ BRAKE_OD_CAN1_DelayedTxMessages m1113 : 16|24@1+ (1,0) [0|16777215] ""  BRAKE
 SG_ BRAKE_OD_CAN1_ErrorStatus m1112 : 16|8@1+ (1,0) [0|255] ""  BRAKE
 SG_ BRAKE_OD_CAN1_DiscardedTxMe_0000 m1111 : 16|24@1+ (1,0) [0|16777215] ""  BRAKE
 SG_ BRAKE_OD_CAN1_Status m1110 : 16|8@1+ (1,0) [0|255] ""  BRAKE
 SG_ BRAKE_OD_CAN1_Baudrate m1108 : 16|16@1+ (1,0) [125|1000] "kbps"  BRAKE
 SG_ BRAKE_OD_CAN1_autoErrorReset m1107 : 16|8@1+ (1,0) [0|255] ""  BRAKE
 SG_ BRAKE_OD_CAN1_lastErrorCode m1106 : 16|32@1+ (1,0) [0|4294967295] ""  BRAKE
 SG_ BRAKE_OD_CAN1_RxErrCnt m1105 : 16|8@1+ (1,0) [0|255] ""  BRAKE
 SG_ BRAKE_OD_CAN1_TxErrCnt m1104 : 16|8@1+ (1,0) [0|255] ""  BRAKE
 SG_ BRAKE_OD_BuildTime m1073 : 16|24@1+ (1,0) [0|16777215] ""  BRAKE
 SG_ BRAKE_OD_BuildDate m1072 : 16|32@1+ (1,0) [0|4294967295] ""  BRAKE
 SG_ BRAKE_OD_ChipUID2 m1057 : 16|48@1+ (1,0) [0|281474976710655] ""  BRAKE
 SG_ BRAKE_OD_ChipUID1 m1056 : 16|48@1+ (1,0) [0|281474976710655] ""  BRAKE
 SG_ BRAKE_OD_SdcOut m1046 : 16|8@1+ (1,0) [0|255] ""  BRAKE
 SG_ BRAKE_OD_SdcIn m1045 : 16|8@1+ (1,0) [0|255] ""  BRAKE
 SG_ BRAKE_OD_runtime m1044 : 16|24@1+ (1,0) [0|16777215] "ms"  BRAKE
 SG_ BRAKE_OD_InputVoltage m1043 : 16|16@1+ (0.001,0) [0|65.535] "V"  BRAKE
 SG_ BRAKE_OD_BoardTemp m1042 : 16|16@1+ (0.01,-30) [-30|625.35] "°C"  BRAKE
 SG_ BRAKE_OD_MemFree m1041 : 16|16@1+ (4,0) [0|262140] "bytes"  BRAKE
 SG_ BRAKE_OD_CpuUsage m1040 : 16|8@1+ (0.5,0) [0|100] "%"  BRAKE
 SG_ BRAKE_OD_OdEntrySendInterval m33 : 16|16@1+ (1,0) [0|65535] "ms"  BRAKE
 SG_ BRAKE_OD_SendOdOnBootup m32 : 16|8@1+ (1,0) [0|255] ""  BRAKE
 SG_ BRAKE_OD_HeartbeatInterval m16 : 16|16@1+ (1,0) [0|65535] "ms"  BRAKE
 SG_ BRAKE_OD_DbcVersion m5 : 16|16@1+ (1,0) [0|65535] ""  BRAKE
 SG_ BRAKE_OD_StackVersion m4 : 16|16@1+ (1,0) [0|65535] ""  BRAKE
 SG_ BRAKE_OD_ProtocolVersion m3 : 16|16@1+ (1,0) [0|65535] ""  BRAKE
 SG_ BRAKE_OD_NodeStatus m2 : 16|8@1+ (1,0) [0|255] ""  BRAKE
 SG_ BRAKE_OD_NodeID m1 : 16|8@1+ (1,0) [0|255] ""  BRAKE
 SG_ BRAKE_SDO_ID M : 0|12@1+ (1,0) [0|4095] ""  BRAKE

BO_ 1540 BRAKE_SDO_Req_Down: 2 TelemetryNode
 SG_ BRAKE_SDO_ID M : 0|12@1+ (1,0) [0|4095] ""  BRAKE

BO_ 1796 BRAKE_Heartbeat: 1 BRAKE
 SG_ BRAKE_NodeState : 0|8@1+ (1,0) [0|0] ""  Master,TelemetryNode

BO_ 1860 BRAKE_BTL_TX: 8 BRAKE

BO_ 1924 BRAKE_BTL_RX: 8 TelemetryNode

BO_ 133 MLU_1_EMCY: 4 MLU_1
 SG_ MLU_1_E0_OtherError : 12|1@1+ (1,0) [0|0] ""  Master,TelemetryNode
 SG_ MLU_1_W0_OtherWarning : 0|1@1+ (1,0) [0|0] ""  Master,TelemetryNode

BO_ 389 MLU_1_TX_PDO1: 0 MLU_1

BO_ 453 MLU_1_RX_PDO1: 0 Vector__XXX

BO_ 517 MLU_1_TX_PDO2: 0 MLU_1

BO_ 581 MLU_1_RX_PDO2: 0 Vector__XXX

BO_ 645 MLU_1_TX_PDO3: 0 MLU_1

BO_ 709 MLU_1_RX_PDO3: 0 Vector__XXX

BO_ 773 MLU_1_TX_PDO4: 0 MLU_1

BO_ 837 MLU_1_RX_PDO4: 0 Vector__XXX

BO_ 901 MLU_1_TX_PDO5: 0 MLU_1

BO_ 965 MLU_1_TX_PDO6: 0 MLU_1

BO_ 1029 MLU_1_TX_PDO7: 0 MLU_1

BO_ 1093 MLU_1_TX_PDO8: 0 MLU_1

BO_ 1157 MLU_1_TX_PDO9: 0 MLU_1

BO_ 1221 MLU_1_TX_PDO10: 0 MLU_1

BO_ 1285 MLU_1_TX_PDO11: 0 MLU_1

BO_ 1349 MLU_1_TX_PDO12: 0 MLU_1

BO_ 1413 MLU_1_SDO_Resp: 8 MLU_1
 SG_ MLU_1_OD_CAN2_DelayedTxMessages m1129 : 16|24@1+ (1,0) [0|16777215] ""  TelemetryNode
 SG_ MLU_1_OD_CAN2_ErrorStatus m1128 : 16|8@1+ (1,0) [0|255] ""  TelemetryNode
 SG_ MLU_1_OD_CAN2_DiscardedTxMessage m1127 : 16|24@1+ (1,0) [0|16777215] ""  TelemetryNode
 SG_ MLU_1_OD_CAN2_Status m1126 : 16|8@1+ (1,0) [0|255] ""  TelemetryNode
 SG_ MLU_1_OD_CAN2_Baudrate m1124 : 16|16@1+ (1,0) [125|1000] "kbps"  TelemetryNode
 SG_ MLU_1_OD_CAN2_autoErrorReset m1123 : 16|8@1+ (1,0) [0|255] ""  TelemetryNode
 SG_ MLU_1_OD_CAN2_lastErrorCode m1122 : 16|32@1+ (1,0) [0|4294967295] ""  TelemetryNode
 SG_ MLU_1_OD_CAN2_RxErrCnt m1121 : 16|8@1+ (1,0) [0|255] ""  TelemetryNode
 SG_ MLU_1_OD_CAN2_TxErrCnt m1120 : 16|8@1+ (1,0) [0|255] ""  TelemetryNode
 SG_ MLU_1_OD_CAN1_DelayedTxMessages m1113 : 16|24@1+ (1,0) [0|16777215] ""  TelemetryNode
 SG_ MLU_1_OD_CAN1_ErrorStatus m1112 : 16|8@1+ (1,0) [0|255] ""  TelemetryNode
 SG_ MLU_1_OD_CAN1_DiscardedTxMessage m1111 : 16|24@1+ (1,0) [0|16777215] ""  TelemetryNode
 SG_ MLU_1_OD_CAN1_Status m1110 : 16|8@1+ (1,0) [0|255] ""  TelemetryNode
 SG_ MLU_1_OD_CAN1_Baudrate m1108 : 16|16@1+ (1,0) [125|1000] "kbps"  TelemetryNode
 SG_ MLU_1_OD_CAN1_autoErrorReset m1107 : 16|8@1+ (1,0) [0|255] ""  TelemetryNode
 SG_ MLU_1_OD_CAN1_lastErrorCode m1106 : 16|32@1+ (1,0) [0|4294967295] ""  TelemetryNode
 SG_ MLU_1_OD_CAN1_RxErrCnt m1105 : 16|8@1+ (1,0) [0|255] ""  TelemetryNode
 SG_ MLU_1_OD_CAN1_TxErrCnt m1104 : 16|8@1+ (1,0) [0|255] ""  TelemetryNode
 SG_ MLU_1_OD_BuildTime m1073 : 16|24@1+ (1,0) [0|16777215] ""  TelemetryNode
 SG_ MLU_1_OD_BuildDate m1072 : 16|32@1+ (1,0) [0|4294967295] ""  TelemetryNode
 SG_ MLU_1_OD_ChipUID2 m1057 : 16|48@1+ (1,0) [0|281474976710655] ""  TelemetryNode
 SG_ MLU_1_OD_ChipUID1 m1056 : 16|48@1+ (1,0) [0|281474976710655] ""  TelemetryNode
 SG_ MLU_1_OD_SdcOut m1046 : 16|8@1+ (1,0) [0|255] ""  TelemetryNode
 SG_ MLU_1_OD_SdcIn m1045 : 16|8@1+ (1,0) [0|255] ""  TelemetryNode
 SG_ MLU_1_OD_runtime m1044 : 16|24@1+ (1,0) [0|16777215] "ms"  TelemetryNode
 SG_ MLU_1_OD_InputVoltage m1043 : 16|16@1+ (0.001,0) [0|65.535] "V"  TelemetryNode
 SG_ MLU_1_OD_BoardTemp m1042 : 16|16@1+ (0.01,-30) [-30|625.35] "°C"  TelemetryNode
 SG_ MLU_1_OD_MemFree m1041 : 16|16@1+ (4,0) [0|262140] "bytes"  TelemetryNode
 SG_ MLU_1_OD_CpuUsage m1040 : 16|8@1+ (0.5,0) [0|100] "%"  TelemetryNode
 SG_ MLU_1_OD_OdEntrySendInterval m33 : 16|16@1+ (1,0) [0|65535] "ms"  TelemetryNode
 SG_ MLU_1_OD_SendOdOnBootup m32 : 16|8@1+ (1,0) [0|255] ""  TelemetryNode
 SG_ MLU_1_OD_HeartbeatInterval m16 : 16|16@1+ (1,0) [0|65535] "ms"  TelemetryNode
 SG_ MLU_1_OD_DbcVersion m5 : 16|16@1+ (1,0) [0|65535] ""  TelemetryNode
 SG_ MLU_1_OD_StackVersion m4 : 16|16@1+ (1,0) [0|65535] ""  TelemetryNode
 SG_ MLU_1_OD_ProtocolVersion m3 : 16|16@1+ (1,0) [0|65535] ""  TelemetryNode
 SG_ MLU_1_OD_NodeStatus m2 : 16|8@1+ (1,0) [0|255] ""  TelemetryNode
 SG_ MLU_1_OD_NodeID m1 : 16|8@1+ (1,0) [0|255] ""  TelemetryNode
 SG_ MLU_1_SDO_RespCode : 12|4@1+ (1,0) [0|0] ""  TelemetryNode
 SG_ MLU_1_SDO_ID M : 0|12@1+ (1,0) [0|4095] ""  TelemetryNode

BO_ 1477 MLU_1_SDO_Req_Up: 8 TelemetryNode
 SG_ MLU_1_OD_CAN2_DelayedTxMessages m1129 : 16|24@1+ (1,0) [0|16777215] ""  MLU_1
 SG_ MLU_1_OD_CAN2_ErrorStatus m1128 : 16|8@1+ (1,0) [0|255] ""  MLU_1
 SG_ MLU_1_OD_CAN2_DiscardedTxMe_0000 m1127 : 16|24@1+ (1,0) [0|16777215] ""  MLU_1
 SG_ MLU_1_OD_CAN2_Status m1126 : 16|8@1+ (1,0) [0|255] ""  MLU_1
 SG_ MLU_1_OD_CAN2_Baudrate m1124 : 16|16@1+ (1,0) [125|1000] "kbps"  MLU_1
 SG_ MLU_1_OD_CAN2_autoErrorReset m1123 : 16|8@1+ (1,0) [0|255] ""  MLU_1
 SG_ MLU_1_OD_CAN2_lastErrorCode m1122 : 16|32@1+ (1,0) [0|4294967295] ""  MLU_1
 SG_ MLU_1_OD_CAN2_RxErrCnt m1121 : 16|8@1+ (1,0) [0|255] ""  MLU_1
 SG_ MLU_1_OD_CAN2_TxErrCnt m1120 : 16|8@1+ (1,0) [0|255] ""  MLU_1
 SG_ MLU_1_OD_CAN1_DelayedTxMessages m1113 : 16|24@1+ (1,0) [0|16777215] ""  MLU_1
 SG_ MLU_1_OD_CAN1_ErrorStatus m1112 : 16|8@1+ (1,0) [0|255] ""  MLU_1
 SG_ MLU_1_OD_CAN1_DiscardedTxMe_0000 m1111 : 16|24@1+ (1,0) [0|16777215] ""  MLU_1
 SG_ MLU_1_OD_CAN1_Status m1110 : 16|8@1+ (1,0) [0|255] ""  MLU_1
 SG_ MLU_1_OD_CAN1_Baudrate m1108 : 16|16@1+ (1,0) [125|1000] "kbps"  MLU_1
 SG_ MLU_1_OD_CAN1_autoErrorReset m1107 : 16|8@1+ (1,0) [0|255] ""  MLU_1
 SG_ MLU_1_OD_CAN1_lastErrorCode m1106 : 16|32@1+ (1,0) [0|4294967295] ""  MLU_1
 SG_ MLU_1_OD_CAN1_RxErrCnt m1105 : 16|8@1+ (1,0) [0|255] ""  MLU_1
 SG_ MLU_1_OD_CAN1_TxErrCnt m1104 : 16|8@1+ (1,0) [0|255] ""  MLU_1
 SG_ MLU_1_OD_BuildTime m1073 : 16|24@1+ (1,0) [0|16777215] ""  MLU_1
 SG_ MLU_1_OD_BuildDate m1072 : 16|32@1+ (1,0) [0|4294967295] ""  MLU_1
 SG_ MLU_1_OD_ChipUID2 m1057 : 16|48@1+ (1,0) [0|281474976710655] ""  MLU_1
 SG_ MLU_1_OD_ChipUID1 m1056 : 16|48@1+ (1,0) [0|281474976710655] ""  MLU_1
 SG_ MLU_1_OD_SdcOut m1046 : 16|8@1+ (1,0) [0|255] ""  MLU_1
 SG_ MLU_1_OD_SdcIn m1045 : 16|8@1+ (1,0) [0|255] ""  MLU_1
 SG_ MLU_1_OD_runtime m1044 : 16|24@1+ (1,0) [0|16777215] "ms"  MLU_1
 SG_ MLU_1_OD_InputVoltage m1043 : 16|16@1+ (0.001,0) [0|65.535] "V"  MLU_1
 SG_ MLU_1_OD_BoardTemp m1042 : 16|16@1+ (0.01,-30) [-30|625.35] "°C"  MLU_1
 SG_ MLU_1_OD_MemFree m1041 : 16|16@1+ (4,0) [0|262140] "bytes"  MLU_1
 SG_ MLU_1_OD_CpuUsage m1040 : 16|8@1+ (0.5,0) [0|100] "%"  MLU_1
 SG_ MLU_1_OD_OdEntrySendInterval m33 : 16|16@1+ (1,0) [0|65535] "ms"  MLU_1
 SG_ MLU_1_OD_SendOdOnBootup m32 : 16|8@1+ (1,0) [0|255] ""  MLU_1
 SG_ MLU_1_OD_HeartbeatInterval m16 : 16|16@1+ (1,0) [0|65535] "ms"  MLU_1
 SG_ MLU_1_OD_DbcVersion m5 : 16|16@1+ (1,0) [0|65535] ""  MLU_1
 SG_ MLU_1_OD_StackVersion m4 : 16|16@1+ (1,0) [0|65535] ""  MLU_1
 SG_ MLU_1_OD_ProtocolVersion m3 : 16|16@1+ (1,0) [0|65535] ""  MLU_1
 SG_ MLU_1_OD_NodeStatus m2 : 16|8@1+ (1,0) [0|255] ""  MLU_1
 SG_ MLU_1_OD_NodeID m1 : 16|8@1+ (1,0) [0|255] ""  MLU_1
 SG_ MLU_1_SDO_ID M : 0|12@1+ (1,0) [0|4095] ""  MLU_1

BO_ 1541 MLU_1_SDO_Req_Down: 2 TelemetryNode
 SG_ MLU_1_SDO_ID M : 0|12@1+ (1,0) [0|4095] ""  MLU_1

BO_ 1797 MLU_1_Heartbeat: 1 MLU_1
 SG_ MLU_1_NodeState : 0|8@1+ (1,0) [0|0] ""  Master,TelemetryNode

BO_ 1861 MLU_1_BTL_TX: 8 MLU_1

CM_ BU_ TelemetryNode "CANzero SDO Client Node.";
CM_ BU_ Master "CANzero NMT Master Node.";
CM_ BU_ SENSOR "SENSOR:0x1
Node-ID 0x1";
CM_ BU_ PDU "PowerDistributionUnit
Node-ID 0x2";
CM_ BU_ CLU "CentralLevitationalUnit
Node-ID 0x3";
CM_ BU_ BRAKE "BrakeECU
Node-ID 0x4";
CM_ BU_ MLU_1 "ModularLevitationalUnit-1
Node-ID 0x5";
CM_ BU_ MLU_2 "ModularLevitationalUnit-2
Node-ID 0x6";
CM_ BU_ MLU_3 "ModularLevitationalUnit-3
Node-ID 0x7";
CM_ BU_ MLU_4 "ModularLevitationalUnit-4
Node-ID 0x8";
CM_ BU_ MLU_5 "ModularLevitationalUnit-5
Node-ID 0x9";
CM_ BU_ MLU_6 "ModularLevitationalUnit-6
Node-ID 0x10";
CM_ BO_ 2 "CANzero NMT message sent by NMT master.";
CM_ SG_ 2 CANzero_NMT_Node "CANzero NMT Node-ID of master request.";
CM_ SG_ 2 CANzero_NMT_State "CANzero NMT State Request by master.";
CM_ BO_ 122 "CANzero Sync message. Not used yet, just a placeholder for future versions.";
CM_ BO_ 123 "CANzero Timestamp message. Not used yet, just a placeholder for future versions.";
CM_ BO_ 129 "Emergency message of node SENSOR with Node-ID 0x1";
CM_ SG_ 129 SENSOR_E11_ANY_MLU_Timeout "a MLU didn't respond to request";
CM_ SG_ 129 SENSOR_E10_MLU6_Timeout "MLU6 didn't respond to request";
CM_ SG_ 129 SENSOR_E9_MLU5_Timeout "MLU5 didn't respond to request";
CM_ SG_ 129 SENSOR_E8_MLU4_Timeout "MLU4 didn't respond to request";
CM_ SG_ 129 SENSOR_E7_MLU3_Timeout "MLU3 didn't respond to request";
CM_ SG_ 129 SENSOR_E6_MLU2_Timeout "MLU2 didn't respond to request";
CM_ SG_ 129 SENSOR_E5_MLU1_Timeout "MLU1 didn't respond to request";
CM_ SG_ 129 SENSOR_E4_CLU_Timeout "CLU didn't respond to request";
CM_ SG_ 129 SENSOR_E3_PDU_Timeout "PDU didn't respond to request";
CM_ SG_ 129 SENSOR_E2_BRAKE_Timeout "BRAKE didn't respose to request";
CM_ SG_ 129 SENSOR_E1_StateTransitionError "Error while transitioning states";
CM_ SG_ 129 SENSOR_E0_OtherError "Other error.";
CM_ SG_ 129 SENSOR_W4_PressureSensorPlausibi "The Pressure sensor readings are not plausible";
CM_ SG_ 129 SENSOR_W3_TemperaturSensorPlausi "The Temperatur Sensor readings are not plausible";
CM_ SG_ 129 SENSOR_W2_OnBoardOvervoltage "The Microcontroller is getting suppiled with to much voltage";
CM_ SG_ 129 SENSOR_W1_OnBoardOverheat "The Microcontroller is overheating";
CM_ SG_ 129 SENSOR_W0_OtherWarning "Other warning.";
CM_ BO_ 385 "Transmit PDO 1 of node SENSOR with Node-ID 0x1";
CM_ BO_ 449 "Receive PDO 1 of node SENSOR with Node-ID 0x1";
CM_ BO_ 513 "Transmit PDO 2 of node SENSOR with Node-ID 0x1";
CM_ BO_ 577 "Receive PDO 2 of node SENSOR with Node-ID 0x1";
CM_ BO_ 641 "Transmit PDO 3 of node SENSOR with Node-ID 0x1";
CM_ BO_ 705 "Receive PDO 3 of node SENSOR with Node-ID 0x1";
CM_ BO_ 769 "Transmit PDO 4 of node SENSOR with Node-ID 0x1";
CM_ BO_ 833 "Receive PDO 4 of node SENSOR with Node-ID 0x1";
CM_ BO_ 897 "Transmit PDO 5 of node SENSOR with Node-ID 0x1";
CM_ BO_ 961 "Transmit PDO 6 of node SENSOR with Node-ID 0x1";
CM_ BO_ 1025 "Transmit PDO 7 of node SENSOR with Node-ID 0x1";
CM_ BO_ 1089 "Transmit PDO 8 of node SENSOR with Node-ID 0x1";
CM_ BO_ 1153 "Transmit PDO 9 of node SENSOR with Node-ID 0x1";
CM_ BO_ 1217 "Transmit PDO 10 of node SENSOR with Node-ID 0x1";
CM_ BO_ 1281 "Transmit PDO 11 of node SENSOR with Node-ID 0x1";
CM_ BO_ 1345 "Transmit PDO 12 of node SENSOR with Node-ID 0x1";
CM_ BO_ 1409 "DO NOT CHANGE ANYTHING HERE!
SDO Response of node SENSOR with Node-ID 0x1";
CM_ SG_ 1409 SENSOR_OD_IMU3_Temperature "Internal temperature of IMU3.";
CM_ SG_ 1409 SENSOR_OD_IMU2_Temperature "Internal temperature of IMU2.";
CM_ SG_ 1409 SENSOR_OD_IMU1_Temperature "Internal temperature of IMU1.";
CM_ SG_ 1409 SENSOR_OD_IMU_number "Number of IMUs that are online.";
CM_ SG_ 1409 SENSOR_OD_CAN2_DelayedTxMessages "Number of delayed TX messages on CAN2 because no messagebox was free.";
CM_ SG_ 1409 SENSOR_OD_CAN2_ErrorStatus "Internal error status (e.g. Error active, Error passive, Bus Off)";
CM_ SG_ 1409 SENSOR_OD_CAN2_DiscardedTxMessag "Number of discarded TX messages on CAN2 because all messageboxes were full";
CM_ SG_ 1409 SENSOR_OD_CAN2_Status "Status of CAN2.";
CM_ SG_ 1409 SENSOR_OD_CAN2_Baudrate "Baudrate of CAN.";
CM_ SG_ 1409 SENSOR_OD_CAN2_autoErrorReset "Automatic reset of errors.";
CM_ SG_ 1409 SENSOR_OD_CAN2_lastErrorCode "Last error code.";
CM_ SG_ 1409 SENSOR_OD_CAN2_RxErrCnt "Receive error count of CAN1.";
CM_ SG_ 1409 SENSOR_OD_CAN2_TxErrCnt "Transmit error count of CAN1.";
CM_ SG_ 1409 SENSOR_OD_CAN1_DelayedTxMessages "Number of delayed TX messages on CAN1 because no messagebox was free.";
CM_ SG_ 1409 SENSOR_OD_CAN1_ErrorStatus "Internal error status (e.g. Error active, Error passive, Bus Off)";
CM_ SG_ 1409 SENSOR_OD_CAN1_DiscardedTxMessag "Number of discarded TX messages on CAN1 because all messageboxes were full";
CM_ SG_ 1409 SENSOR_OD_CAN1_Status "Status of CAN1.";
CM_ SG_ 1409 SENSOR_OD_CAN1_Baudrate "Baudrate of CAN.";
CM_ SG_ 1409 SENSOR_OD_CAN1_autoErrorReset "Automatic reset of errors.";
CM_ SG_ 1409 SENSOR_OD_CAN1_lastErrorCode "Last error code.";
CM_ SG_ 1409 SENSOR_OD_CAN1_RxErrCnt "Receive error count of CAN1.";
CM_ SG_ 1409 SENSOR_OD_CAN1_TxErrCnt "Transmit error count of CAN1.";
CM_ SG_ 1409 SENSOR_OD_BuildTime "Software build time in the format HHMMSS.";
CM_ SG_ 1409 SENSOR_OD_BuildDate "Software build date in the format YYYYMMDD.";
CM_ SG_ 1409 SENSOR_OD_ChipUID2 "Seccond part of unique ID of microcontroller.";
CM_ SG_ 1409 SENSOR_OD_ChipUID1 "First part of unique ID of microcontroller.";
CM_ SG_ 1409 SENSOR_OD_SdcOut "Measurement of Shutdown Circuit Output";
CM_ SG_ 1409 SENSOR_OD_SdcIn "Measurement of Shutdown Circuit Input";
CM_ SG_ 1409 SENSOR_OD_runtime "Runtime of chip in milliseconds.";
CM_ SG_ 1409 SENSOR_OD_InputVoltage "Board supply voltage.";
CM_ SG_ 1409 SENSOR_OD_BoardTemp "Temperature of board";
CM_ SG_ 1409 SENSOR_OD_MemFree "Free memory in bytes.";
CM_ SG_ 1409 SENSOR_OD_CpuUsage "Current CPU usage in %.";
CM_ SG_ 1409 SENSOR_OD_OdEntrySendInterval "Interval for sending all readable OD entries. Sending is disabled if less than 5 ms.";
CM_ SG_ 1409 SENSOR_OD_SendOdOnBootup "Whether to send all OD entries on bootup.";
CM_ SG_ 1409 SENSOR_OD_HeartbeatInterval "Heartbeat Interval in milliseconds.";
CM_ SG_ 1409 SENSOR_OD_DbcVersion "CANzero DBC version.";
CM_ SG_ 1409 SENSOR_OD_StackVersion "CANzero stack version.";
CM_ SG_ 1409 SENSOR_OD_ProtocolVersion "CANzero Protocol Version.";
CM_ SG_ 1409 SENSOR_OD_NodeStatus "State of the node.";
CM_ SG_ 1409 SENSOR_OD_NodeID "CANzero Node-ID.";
CM_ SG_ 1409 SENSOR_SDO_RespCode "Response code of SDO access.";
CM_ SG_ 1409 SENSOR_SDO_ID "Specifies SDO-ID of SENSOR";
CM_ BO_ 1473 "DO NOT CHANGE ANYTHING HERE!
SDO Request Upload to node SENSOR with Node-ID 0x1";
CM_ SG_ 1473 SENSOR_OD_IMU3_Temperature "Internal temperature of IMU3.";
CM_ SG_ 1473 SENSOR_OD_IMU2_Temperature "Internal temperature of IMU2.";
CM_ SG_ 1473 SENSOR_OD_IMU1_Temperature "Internal temperature of IMU1.";
CM_ SG_ 1473 SENSOR_OD_IMU_number "Number of IMUs that are online.";
CM_ SG_ 1473 SENSOR_OD_CAN2_DelayedTxMessages "Number of delayed TX messages on CAN2 because no messagebox was free.";
CM_ SG_ 1473 SENSOR_OD_CAN2_ErrorStatus "Internal error status (e.g. Error active, Error passive, Bus Off)";
CM_ SG_ 1473 SENSOR_OD_CAN2_DiscardedTxM_0000 "Number of discarded TX messages on CAN2 because all messageboxes were full";
CM_ SG_ 1473 SENSOR_OD_CAN2_Status "Status of CAN2.";
CM_ SG_ 1473 SENSOR_OD_CAN2_Baudrate "Baudrate of CAN.";
CM_ SG_ 1473 SENSOR_OD_CAN2_autoErrorReset "Automatic reset of errors.";
CM_ SG_ 1473 SENSOR_OD_CAN2_lastErrorCode "Last error code.";
CM_ SG_ 1473 SENSOR_OD_CAN2_RxErrCnt "Receive error count of CAN1.";
CM_ SG_ 1473 SENSOR_OD_CAN2_TxErrCnt "Transmit error count of CAN1.";
CM_ SG_ 1473 SENSOR_OD_CAN1_DelayedTxMessages "Number of delayed TX messages on CAN1 because no messagebox was free.";
CM_ SG_ 1473 SENSOR_OD_CAN1_ErrorStatus "Internal error status (e.g. Error active, Error passive, Bus Off)";
CM_ SG_ 1473 SENSOR_OD_CAN1_DiscardedTxM_0000 "Number of discarded TX messages on CAN1 because all messageboxes were full";
CM_ SG_ 1473 SENSOR_OD_CAN1_Status "Status of CAN1.";
CM_ SG_ 1473 SENSOR_OD_CAN1_Baudrate "Baudrate of CAN.";
CM_ SG_ 1473 SENSOR_OD_CAN1_autoErrorReset "Automatic reset of errors.";
CM_ SG_ 1473 SENSOR_OD_CAN1_lastErrorCode "Last error code.";
CM_ SG_ 1473 SENSOR_OD_CAN1_RxErrCnt "Receive error count of CAN1.";
CM_ SG_ 1473 SENSOR_OD_CAN1_TxErrCnt "Transmit error count of CAN1.";
CM_ SG_ 1473 SENSOR_OD_BuildTime "Software build time in the format HHMMSS.";
CM_ SG_ 1473 SENSOR_OD_BuildDate "Software build date in the format YYYYMMDD.";
CM_ SG_ 1473 SENSOR_OD_ChipUID2 "Seccond part of unique ID of microcontroller.";
CM_ SG_ 1473 SENSOR_OD_ChipUID1 "First part of unique ID of microcontroller.";
CM_ SG_ 1473 SENSOR_OD_SdcOut "Measurement of Shutdown Circuit Output";
CM_ SG_ 1473 SENSOR_OD_SdcIn "Measurement of Shutdown Circuit Input";
CM_ SG_ 1473 SENSOR_OD_runtime "Runtime of chip in milliseconds.";
CM_ SG_ 1473 SENSOR_OD_InputVoltage "Board supply voltage.";
CM_ SG_ 1473 SENSOR_OD_BoardTemp "Temperature of board";
CM_ SG_ 1473 SENSOR_OD_MemFree "Free memory in bytes.";
CM_ SG_ 1473 SENSOR_OD_CpuUsage "Current CPU usage in %.";
CM_ SG_ 1473 SENSOR_OD_OdEntrySendInterval "Interval for sending all readable OD entries. Sending is disabled if less than 5 ms.";
CM_ SG_ 1473 SENSOR_OD_SendOdOnBootup "Whether to send all OD entries on bootup.";
CM_ SG_ 1473 SENSOR_OD_HeartbeatInterval "Heartbeat Interval in milliseconds.";
CM_ SG_ 1473 SENSOR_OD_DbcVersion "CANzero DBC version.";
CM_ SG_ 1473 SENSOR_OD_StackVersion "CANzero stack version.";
CM_ SG_ 1473 SENSOR_OD_ProtocolVersion "CANzero Protocol Version.";
CM_ SG_ 1473 SENSOR_OD_NodeStatus "State of the node.";
CM_ SG_ 1473 SENSOR_OD_NodeID "CANzero Node-ID.";
CM_ SG_ 1473 SENSOR_SDO_ID "Specifies SDO-ID of SENSOR";
CM_ BO_ 1537 "DO NOT CHANGE ANYTHING HERE!
SDO Request Download from node SENSOR with Node-ID 0x1";
CM_ SG_ 1537 SENSOR_SDO_ID "Specifies SDO-ID of SENSOR";
CM_ BO_ 1793 "Heartbeat of node SENSOR with Node-ID 0x1";
CM_ SG_ 1793 SENSOR_NodeState "Heartbeat status of node SENSOR";
CM_ BO_ 1857 "Bootloader transmit from node SENSOR with Node-ID 0x1";
CM_ BO_ 1921 "Bootloader receive by node SENSOR with Node-ID 0x1";
CM_ BO_ 130 "Emergency message of node PDU with Node-ID 0x2";
CM_ SG_ 130 PDU_E4_watchdogStateMachine "The watchdog for the state machine timed out.";
CM_ SG_ 130 PDU_E3_batterTempCritical "Temperature limit of the battery reached.";
CM_ SG_ 130 PDU_E2_batteryOvercurrent "Overcurrent limit of the battery reached.";
CM_ SG_ 130 PDU_E1_batterVoltageCritical "Error when battery voltage is getting critical low. Pod will be shut down";
CM_ SG_ 130 PDU_E0_OtherError "Other error.";
CM_ SG_ 130 PDU_W2_batterTempHigh "Warning when battery temperature is rising high";
CM_ SG_ 130 PDU_W1_batterVoltageLow "Warning when battery voltage is getting low";
CM_ SG_ 130 PDU_W0_OtherWarning "Other warning.";
CM_ BO_ 386 "Transmit PDO 1 of node PDU with Node-ID 0x2";
CM_ BO_ 450 "Receive PDO 1 of node PDU with Node-ID 0x2";
CM_ BO_ 514 "Transmit PDO 2 of node PDU with Node-ID 0x2";
CM_ BO_ 578 "Receive PDO 2 of node PDU with Node-ID 0x2";
CM_ BO_ 642 "Transmit PDO 3 of node PDU with Node-ID 0x2";
CM_ BO_ 706 "Receive PDO 3 of node PDU with Node-ID 0x2";
CM_ BO_ 770 "Transmit PDO 4 of node PDU with Node-ID 0x2";
CM_ BO_ 834 "Receive PDO 4 of node PDU with Node-ID 0x2";
CM_ BO_ 898 "Transmit PDO 5 of node PDU with Node-ID 0x2";
CM_ BO_ 962 "Transmit PDO 6 of node PDU with Node-ID 0x2";
CM_ BO_ 1026 "Transmit PDO 7 of node PDU with Node-ID 0x2";
CM_ BO_ 1090 "Transmit PDO 8 of node PDU with Node-ID 0x2";
CM_ BO_ 1154 "Transmit PDO 9 of node PDU with Node-ID 0x2";
CM_ BO_ 1218 "Transmit PDO 10 of node PDU with Node-ID 0x2";
CM_ BO_ 1282 "Transmit PDO 11 of node PDU with Node-ID 0x2";
CM_ BO_ 1346 "Transmit PDO 12 of node PDU with Node-ID 0x2";
CM_ BO_ 1410 "DO NOT CHANGE ANYTHING HERE!
SDO Response of node PDU with Node-ID 0x2";
CM_ SG_ 1410 PDU_OD_CoolingPumpEnabled "Enable the Cooling Pump.";
CM_ SG_ 1410 PDU_OD_LedCommands "Commands from Telemetry to leds";
CM_ SG_ 1410 PDU_OD_projectXXEnabled "Enable the Project XX leds.";
CM_ SG_ 1410 PDU_OD_watchdogTimeout "Timeout for the state machine watchdog in milliseconds.";
CM_ SG_ 1410 PDU_OD_statusSendInterval "Sending intervall for the status in milliseconds.";
CM_ SG_ 1410 PDU_OD_currentReadInterval "Sampling time in millisecconds for reading the currents.";
CM_ SG_ 1410 PDU_OD_batteryOvercurrent "Overcurrent limit in ampere of the low voltage battery.";
CM_ SG_ 1410 PDU_OD_overTempCritical "Error when battery temperature is getting critical high. Pod will be shut down";
CM_ SG_ 1410 PDU_OD_overTempWarn "Warning when battery temperature is getting high";
CM_ SG_ 1410 PDU_OD_batterVoltageCritical "Error when battery voltage is getting critical low. Pod will be shut down";
CM_ SG_ 1410 PDU_OD_batterVoltageLow "Warning when battery voltage is getting low";
CM_ SG_ 1410 PDU_OD_CAN2_DelayedTxMessages "Number of delayed TX messages on CAN2 because no messagebox was free.";
CM_ SG_ 1410 PDU_OD_CAN2_ErrorStatus "Internal error status (e.g. Error active, Error passive, Bus Off)";
CM_ SG_ 1410 PDU_OD_CAN2_DiscardedTxMessages "Number of discarded TX messages on CAN2 because all messageboxes were full";
CM_ SG_ 1410 PDU_OD_CAN2_Status "Status of CAN2.";
CM_ SG_ 1410 PDU_OD_CAN2_Baudrate "Baudrate of CAN.";
CM_ SG_ 1410 PDU_OD_CAN2_autoErrorReset "Automatic reset of errors.";
CM_ SG_ 1410 PDU_OD_CAN2_lastErrorCode "Last error code.";
CM_ SG_ 1410 PDU_OD_CAN2_RxErrCnt "Receive error count of CAN1.";
CM_ SG_ 1410 PDU_OD_CAN2_TxErrCnt "Transmit error count of CAN1.";
CM_ SG_ 1410 PDU_OD_CAN1_DelayedTxMessages "Number of delayed TX messages on CAN1 because no messagebox was free.";
CM_ SG_ 1410 PDU_OD_CAN1_ErrorStatus "Internal error status (e.g. Error active, Error passive, Bus Off)";
CM_ SG_ 1410 PDU_OD_CAN1_DiscardedTxMessages "Number of discarded TX messages on CAN1 because all messageboxes were full";
CM_ SG_ 1410 PDU_OD_CAN1_Status "Status of CAN1.";
CM_ SG_ 1410 PDU_OD_CAN1_Baudrate "Baudrate of CAN.";
CM_ SG_ 1410 PDU_OD_CAN1_autoErrorReset "Automatic reset of errors.";
CM_ SG_ 1410 PDU_OD_CAN1_lastErrorCode "Last error code.";
CM_ SG_ 1410 PDU_OD_CAN1_RxErrCnt "Receive error count of CAN1.";
CM_ SG_ 1410 PDU_OD_CAN1_TxErrCnt "Transmit error count of CAN1.";
CM_ SG_ 1410 PDU_OD_BuildTime "Software build time in the format HHMMSS.";
CM_ SG_ 1410 PDU_OD_BuildDate "Software build date in the format YYYYMMDD.";
CM_ SG_ 1410 PDU_OD_ChipUID2 "Seccond part of unique ID of microcontroller.";
CM_ SG_ 1410 PDU_OD_ChipUID1 "First part of unique ID of microcontroller.";
CM_ SG_ 1410 PDU_OD_SdcOut "Measurement of Shutdown Circuit Output";
CM_ SG_ 1410 PDU_OD_SdcIn "Measurement of Shutdown Circuit Input";
CM_ SG_ 1410 PDU_OD_runtime "Runtime of chip in milliseconds.";
CM_ SG_ 1410 PDU_OD_InputVoltage "Board supply voltage.";
CM_ SG_ 1410 PDU_OD_BoardTemp "Temperature of board";
CM_ SG_ 1410 PDU_OD_MemFree "Free memory in bytes.";
CM_ SG_ 1410 PDU_OD_CpuUsage "Current CPU usage in %.";
CM_ SG_ 1410 PDU_OD_OdEntrySendInterval "Interval for sending all readable OD entries. Sending is disabled if less than 5 ms.";
CM_ SG_ 1410 PDU_OD_SendOdOnBootup "Whether to send all OD entries on bootup.";
CM_ SG_ 1410 PDU_OD_HeartbeatInterval "Heartbeat Interval in milliseconds.";
CM_ SG_ 1410 PDU_OD_DbcVersion "CANzero DBC version.";
CM_ SG_ 1410 PDU_OD_StackVersion "CANzero stack version.";
CM_ SG_ 1410 PDU_OD_ProtocolVersion "CANzero Protocol Version.";
CM_ SG_ 1410 PDU_OD_NodeStatus "State of the node.";
CM_ SG_ 1410 PDU_OD_NodeID "CANzero Node-ID.";
CM_ SG_ 1410 PDU_SDO_RespCode "Response code of SDO access.";
CM_ SG_ 1410 PDU_SDO_ID "Specifies SDO-ID of PDU";
CM_ BO_ 1474 "DO NOT CHANGE ANYTHING HERE!
SDO Request Upload to node PDU with Node-ID 0x2";
CM_ SG_ 1474 PDU_OD_CoolingPumpEnabled "Enable the Cooling Pump.";
CM_ SG_ 1474 PDU_OD_LedCommands "Commands from Telemetry to leds";
CM_ SG_ 1474 PDU_OD_projectXXEnabled "Enable the Project XX leds.";
CM_ SG_ 1474 PDU_OD_watchdogTimeout "Timeout for the state machine watchdog in milliseconds.";
CM_ SG_ 1474 PDU_OD_statusSendInterval "Sending intervall for the status in milliseconds.";
CM_ SG_ 1474 PDU_OD_currentReadInterval "Sampling time in millisecconds for reading the currents.";
CM_ SG_ 1474 PDU_OD_batteryOvercurrent "Overcurrent limit in ampere of the low voltage battery.";
CM_ SG_ 1474 PDU_OD_overTempCritical "Error when battery temperature is getting critical high. Pod will be shut down";
CM_ SG_ 1474 PDU_OD_overTempWarn "Warning when battery temperature is getting high";
CM_ SG_ 1474 PDU_OD_batterVoltageCritical "Error when battery voltage is getting critical low. Pod will be shut down";
CM_ SG_ 1474 PDU_OD_batterVoltageLow "Warning when battery voltage is getting low";
CM_ SG_ 1474 PDU_OD_CAN2_DelayedTxMessages "Number of delayed TX messages on CAN2 because no messagebox was free.";
CM_ SG_ 1474 PDU_OD_CAN2_ErrorStatus "Internal error status (e.g. Error active, Error passive, Bus Off)";
CM_ SG_ 1474 PDU_OD_CAN2_DiscardedTxMessages "Number of discarded TX messages on CAN2 because all messageboxes were full";
CM_ SG_ 1474 PDU_OD_CAN2_Status "Status of CAN2.";
CM_ SG_ 1474 PDU_OD_CAN2_Baudrate "Baudrate of CAN.";
CM_ SG_ 1474 PDU_OD_CAN2_autoErrorReset "Automatic reset of errors.";
CM_ SG_ 1474 PDU_OD_CAN2_lastErrorCode "Last error code.";
CM_ SG_ 1474 PDU_OD_CAN2_RxErrCnt "Receive error count of CAN1.";
CM_ SG_ 1474 PDU_OD_CAN2_TxErrCnt "Transmit error count of CAN1.";
CM_ SG_ 1474 PDU_OD_CAN1_DelayedTxMessages "Number of delayed TX messages on CAN1 because no messagebox was free.";
CM_ SG_ 1474 PDU_OD_CAN1_ErrorStatus "Internal error status (e.g. Error active, Error passive, Bus Off)";
CM_ SG_ 1474 PDU_OD_CAN1_DiscardedTxMessages "Number of discarded TX messages on CAN1 because all messageboxes were full";
CM_ SG_ 1474 PDU_OD_CAN1_Status "Status of CAN1.";
CM_ SG_ 1474 PDU_OD_CAN1_Baudrate "Baudrate of CAN.";
CM_ SG_ 1474 PDU_OD_CAN1_autoErrorReset "Automatic reset of errors.";
CM_ SG_ 1474 PDU_OD_CAN1_lastErrorCode "Last error code.";
CM_ SG_ 1474 PDU_OD_CAN1_RxErrCnt "Receive error count of CAN1.";
CM_ SG_ 1474 PDU_OD_CAN1_TxErrCnt "Transmit error count of CAN1.";
CM_ SG_ 1474 PDU_OD_BuildTime "Software build time in the format HHMMSS.";
CM_ SG_ 1474 PDU_OD_BuildDate "Software build date in the format YYYYMMDD.";
CM_ SG_ 1474 PDU_OD_ChipUID2 "Seccond part of unique ID of microcontroller.";
CM_ SG_ 1474 PDU_OD_ChipUID1 "First part of unique ID of microcontroller.";
CM_ SG_ 1474 PDU_OD_SdcOut "Measurement of Shutdown Circuit Output";
CM_ SG_ 1474 PDU_OD_SdcIn "Measurement of Shutdown Circuit Input";
CM_ SG_ 1474 PDU_OD_runtime "Runtime of chip in milliseconds.";
CM_ SG_ 1474 PDU_OD_InputVoltage "Board supply voltage.";
CM_ SG_ 1474 PDU_OD_BoardTemp "Temperature of board";
CM_ SG_ 1474 PDU_OD_MemFree "Free memory in bytes.";
CM_ SG_ 1474 PDU_OD_CpuUsage "Current CPU usage in %.";
CM_ SG_ 1474 PDU_OD_OdEntrySendInterval "Interval for sending all readable OD entries. Sending is disabled if less than 5 ms.";
CM_ SG_ 1474 PDU_OD_SendOdOnBootup "Whether to send all OD entries on bootup.";
CM_ SG_ 1474 PDU_OD_HeartbeatInterval "Heartbeat Interval in milliseconds.";
CM_ SG_ 1474 PDU_OD_DbcVersion "CANzero DBC version.";
CM_ SG_ 1474 PDU_OD_StackVersion "CANzero stack version.";
CM_ SG_ 1474 PDU_OD_ProtocolVersion "CANzero Protocol Version.";
CM_ SG_ 1474 PDU_OD_NodeStatus "State of the node.";
CM_ SG_ 1474 PDU_OD_NodeID "CANzero Node-ID.";
CM_ SG_ 1474 PDU_SDO_ID "Specifies SDO-ID of PDU";
CM_ BO_ 1538 "DO NOT CHANGE ANYTHING HERE!
SDO Request Download from node PDU with Node-ID 0x2";
CM_ SG_ 1538 PDU_SDO_ID "Specifies SDO-ID of PDU";
CM_ BO_ 1794 "Heartbeat of node PDU with Node-ID 0x2";
CM_ SG_ 1794 PDU_NodeState "Heartbeat status of node PDU";
CM_ BO_ 1858 "Bootloader transmit from node PDU with Node-ID 0x2";
CM_ BO_ 1922 "Bootloader receive by node PDU with Node-ID 0x2";
CM_ BO_ 131 "Emergency message of node CLU with Node-ID 0x3";
CM_ SG_ 131 CLU_E0_OtherError "Other error.";
CM_ SG_ 131 CLU_W0_OtherWarning "Other warning.";
CM_ BO_ 387 "Transmit PDO 1 of node CLU with Node-ID 0x3";
CM_ BO_ 451 "Receive PDO 1 of node CLU with Node-ID 0x3";
CM_ BO_ 515 "Transmit PDO 2 of node CLU with Node-ID 0x3";
CM_ BO_ 579 "Receive PDO 2 of node CLU with Node-ID 0x3";
CM_ BO_ 643 "Transmit PDO 3 of node CLU with Node-ID 0x3";
CM_ BO_ 707 "Receive PDO 3 of node CLU with Node-ID 0x3";
CM_ BO_ 771 "Transmit PDO 4 of node CLU with Node-ID 0x3";
CM_ BO_ 835 "Receive PDO 4 of node CLU with Node-ID 0x3";
CM_ BO_ 899 "Transmit PDO 5 of node CLU with Node-ID 0x3";
CM_ BO_ 963 "Transmit PDO 6 of node CLU with Node-ID 0x3";
CM_ BO_ 1027 "Transmit PDO 7 of node CLU with Node-ID 0x3";
CM_ BO_ 1091 "Transmit PDO 8 of node CLU with Node-ID 0x3";
CM_ BO_ 1155 "Transmit PDO 9 of node CLU with Node-ID 0x3";
CM_ BO_ 1219 "Transmit PDO 10 of node CLU with Node-ID 0x3";
CM_ BO_ 1283 "Transmit PDO 11 of node CLU with Node-ID 0x3";
CM_ BO_ 1347 "Transmit PDO 12 of node CLU with Node-ID 0x3";
CM_ BO_ 1411 "DO NOT CHANGE ANYTHING HERE!
SDO Response of node CLU with Node-ID 0x3";
CM_ SG_ 1411 CLU_OD_CAN2_DelayedTxMessages "Number of delayed TX messages on CAN2 because no messagebox was free.";
CM_ SG_ 1411 CLU_OD_CAN2_ErrorStatus "Internal error status (e.g. Error active, Error passive, Bus Off)";
CM_ SG_ 1411 CLU_OD_CAN2_DiscardedTxMessages "Number of discarded TX messages on CAN2 because all messageboxes were full";
CM_ SG_ 1411 CLU_OD_CAN2_Status "Status of CAN2.";
CM_ SG_ 1411 CLU_OD_CAN2_Baudrate "Baudrate of CAN.";
CM_ SG_ 1411 CLU_OD_CAN2_autoErrorReset "Automatic reset of errors.";
CM_ SG_ 1411 CLU_OD_CAN2_lastErrorCode "Last error code.";
CM_ SG_ 1411 CLU_OD_CAN2_RxErrCnt "Receive error count of CAN1.";
CM_ SG_ 1411 CLU_OD_CAN2_TxErrCnt "Transmit error count of CAN1.";
CM_ SG_ 1411 CLU_OD_CAN1_DelayedTxMessages "Number of delayed TX messages on CAN1 because no messagebox was free.";
CM_ SG_ 1411 CLU_OD_CAN1_ErrorStatus "Internal error status (e.g. Error active, Error passive, Bus Off)";
CM_ SG_ 1411 CLU_OD_CAN1_DiscardedTxMessages "Number of discarded TX messages on CAN1 because all messageboxes were full";
CM_ SG_ 1411 CLU_OD_CAN1_Status "Status of CAN1.";
CM_ SG_ 1411 CLU_OD_CAN1_Baudrate "Baudrate of CAN.";
CM_ SG_ 1411 CLU_OD_CAN1_autoErrorReset "Automatic reset of errors.";
CM_ SG_ 1411 CLU_OD_CAN1_lastErrorCode "Last error code.";
CM_ SG_ 1411 CLU_OD_CAN1_RxErrCnt "Receive error count of CAN1.";
CM_ SG_ 1411 CLU_OD_CAN1_TxErrCnt "Transmit error count of CAN1.";
CM_ SG_ 1411 CLU_OD_BuildTime "Software build time in the format HHMMSS.";
CM_ SG_ 1411 CLU_OD_BuildDate "Software build date in the format YYYYMMDD.";
CM_ SG_ 1411 CLU_OD_ChipUID2 "Seccond part of unique ID of microcontroller.";
CM_ SG_ 1411 CLU_OD_ChipUID1 "First part of unique ID of microcontroller.";
CM_ SG_ 1411 CLU_OD_SdcOut "Measurement of Shutdown Circuit Output";
CM_ SG_ 1411 CLU_OD_SdcIn "Measurement of Shutdown Circuit Input";
CM_ SG_ 1411 CLU_OD_runtime "Runtime of chip in milliseconds.";
CM_ SG_ 1411 CLU_OD_InputVoltage "Board supply voltage.";
CM_ SG_ 1411 CLU_OD_BoardTemp "Temperature of board";
CM_ SG_ 1411 CLU_OD_MemFree "Free memory in bytes.";
CM_ SG_ 1411 CLU_OD_CpuUsage "Current CPU usage in %.";
CM_ SG_ 1411 CLU_OD_OdEntrySendInterval "Interval for sending all readable OD entries. Sending is disabled if less than 5 ms.";
CM_ SG_ 1411 CLU_OD_SendOdOnBootup "Whether to send all OD entries on bootup.";
CM_ SG_ 1411 CLU_OD_HeartbeatInterval "Heartbeat Interval in milliseconds.";
CM_ SG_ 1411 CLU_OD_DbcVersion "CANzero DBC version.";
CM_ SG_ 1411 CLU_OD_StackVersion "CANzero stack version.";
CM_ SG_ 1411 CLU_OD_ProtocolVersion "CANzero Protocol Version.";
CM_ SG_ 1411 CLU_OD_NodeStatus "State of the node.";
CM_ SG_ 1411 CLU_OD_NodeID "CANzero Node-ID.";
CM_ SG_ 1411 CLU_SDO_RespCode "Response code of SDO access.";
CM_ SG_ 1411 CLU_SDO_ID "Specifies SDO-ID of CLU";
CM_ BO_ 1475 "DO NOT CHANGE ANYTHING HERE!
SDO Request Upload to node CLU with Node-ID 0x3";
CM_ SG_ 1475 CLU_OD_CAN2_DelayedTxMessages "Number of delayed TX messages on CAN2 because no messagebox was free.";
CM_ SG_ 1475 CLU_OD_CAN2_ErrorStatus "Internal error status (e.g. Error active, Error passive, Bus Off)";
CM_ SG_ 1475 CLU_OD_CAN2_DiscardedTxMessages "Number of discarded TX messages on CAN2 because all messageboxes were full";
CM_ SG_ 1475 CLU_OD_CAN2_Status "Status of CAN2.";
CM_ SG_ 1475 CLU_OD_CAN2_Baudrate "Baudrate of CAN.";
CM_ SG_ 1475 CLU_OD_CAN2_autoErrorReset "Automatic reset of errors.";
CM_ SG_ 1475 CLU_OD_CAN2_lastErrorCode "Last error code.";
CM_ SG_ 1475 CLU_OD_CAN2_RxErrCnt "Receive error count of CAN1.";
CM_ SG_ 1475 CLU_OD_CAN2_TxErrCnt "Transmit error count of CAN1.";
CM_ SG_ 1475 CLU_OD_CAN1_DelayedTxMessages "Number of delayed TX messages on CAN1 because no messagebox was free.";
CM_ SG_ 1475 CLU_OD_CAN1_ErrorStatus "Internal error status (e.g. Error active, Error passive, Bus Off)";
CM_ SG_ 1475 CLU_OD_CAN1_DiscardedTxMessages "Number of discarded TX messages on CAN1 because all messageboxes were full";
CM_ SG_ 1475 CLU_OD_CAN1_Status "Status of CAN1.";
CM_ SG_ 1475 CLU_OD_CAN1_Baudrate "Baudrate of CAN.";
CM_ SG_ 1475 CLU_OD_CAN1_autoErrorReset "Automatic reset of errors.";
CM_ SG_ 1475 CLU_OD_CAN1_lastErrorCode "Last error code.";
CM_ SG_ 1475 CLU_OD_CAN1_RxErrCnt "Receive error count of CAN1.";
CM_ SG_ 1475 CLU_OD_CAN1_TxErrCnt "Transmit error count of CAN1.";
CM_ SG_ 1475 CLU_OD_BuildTime "Software build time in the format HHMMSS.";
CM_ SG_ 1475 CLU_OD_BuildDate "Software build date in the format YYYYMMDD.";
CM_ SG_ 1475 CLU_OD_ChipUID2 "Seccond part of unique ID of microcontroller.";
CM_ SG_ 1475 CLU_OD_ChipUID1 "First part of unique ID of microcontroller.";
CM_ SG_ 1475 CLU_OD_SdcOut "Measurement of Shutdown Circuit Output";
CM_ SG_ 1475 CLU_OD_SdcIn "Measurement of Shutdown Circuit Input";
CM_ SG_ 1475 CLU_OD_runtime "Runtime of chip in milliseconds.";
CM_ SG_ 1475 CLU_OD_InputVoltage "Board supply voltage.";
CM_ SG_ 1475 CLU_OD_BoardTemp "Temperature of board";
CM_ SG_ 1475 CLU_OD_MemFree "Free memory in bytes.";
CM_ SG_ 1475 CLU_OD_CpuUsage "Current CPU usage in %.";
CM_ SG_ 1475 CLU_OD_OdEntrySendInterval "Interval for sending all readable OD entries. Sending is disabled if less than 5 ms.";
CM_ SG_ 1475 CLU_OD_SendOdOnBootup "Whether to send all OD entries on bootup.";
CM_ SG_ 1475 CLU_OD_HeartbeatInterval "Heartbeat Interval in milliseconds.";
CM_ SG_ 1475 CLU_OD_DbcVersion "CANzero DBC version.";
CM_ SG_ 1475 CLU_OD_StackVersion "CANzero stack version.";
CM_ SG_ 1475 CLU_OD_ProtocolVersion "CANzero Protocol Version.";
CM_ SG_ 1475 CLU_OD_NodeStatus "State of the node.";
CM_ SG_ 1475 CLU_OD_NodeID "CANzero Node-ID.";
CM_ SG_ 1475 CLU_SDO_ID "Specifies SDO-ID of CLU";
CM_ BO_ 1539 "DO NOT CHANGE ANYTHING HERE!
SDO Request Download from node CLU with Node-ID 0x3";
CM_ SG_ 1539 CLU_SDO_ID "Specifies SDO-ID of CLU";
CM_ BO_ 1795 "Heartbeat of node CLU with Node-ID 0x3";
CM_ SG_ 1795 CLU_NodeState "Heartbeat status of node CLU";
CM_ BO_ 1859 "Bootloader transmit from node CLU with Node-ID 0x3";
CM_ BO_ 1923 "Bootloader receive by node CLU with Node-ID 0x3";
CM_ BO_ 132 "Emergency message of node BRAKE with Node-ID 0x4";
CM_ SG_ 132 BRAKE_E0_OtherError "Other error.";
CM_ SG_ 132 BRAKE_W0_OtherWarning "Other warning.";
CM_ BO_ 388 "Transmit PDO 1 of node BRAKE with Node-ID 0x4";
CM_ BO_ 452 "Receive PDO 1 of node BRAKE with Node-ID 0x4";
CM_ BO_ 516 "Transmit PDO 2 of node BRAKE with Node-ID 0x4";
CM_ BO_ 580 "Receive PDO 2 of node BRAKE with Node-ID 0x4";
CM_ BO_ 644 "Transmit PDO 3 of node BRAKE with Node-ID 0x4";
CM_ BO_ 708 "Receive PDO 3 of node BRAKE with Node-ID 0x4";
CM_ BO_ 772 "Transmit PDO 4 of node BRAKE with Node-ID 0x4";
CM_ BO_ 836 "Receive PDO 4 of node BRAKE with Node-ID 0x4";
CM_ BO_ 900 "Transmit PDO 5 of node BRAKE with Node-ID 0x4";
CM_ BO_ 964 "Transmit PDO 6 of node BRAKE with Node-ID 0x4";
CM_ BO_ 1028 "Transmit PDO 7 of node BRAKE with Node-ID 0x4";
CM_ BO_ 1092 "Transmit PDO 8 of node BRAKE with Node-ID 0x4";
CM_ BO_ 1156 "Transmit PDO 9 of node BRAKE with Node-ID 0x4";
CM_ BO_ 1220 "Transmit PDO 10 of node BRAKE with Node-ID 0x4";
CM_ BO_ 1284 "Transmit PDO 11 of node BRAKE with Node-ID 0x4";
CM_ BO_ 1348 "Transmit PDO 12 of node BRAKE with Node-ID 0x4";
CM_ BO_ 1412 "DO NOT CHANGE ANYTHING HERE!
SDO Response of node BRAKE with Node-ID 0x4";
CM_ SG_ 1412 BRAKE_OD_CAN2_DelayedTxMessages "Number of delayed TX messages on CAN2 because no messagebox was free.";
CM_ SG_ 1412 BRAKE_OD_CAN2_ErrorStatus "Internal error status (e.g. Error active, Error passive, Bus Off)";
CM_ SG_ 1412 BRAKE_OD_CAN2_DiscardedTxMessage "Number of discarded TX messages on CAN2 because all messageboxes were full";
CM_ SG_ 1412 BRAKE_OD_CAN2_Status "Status of CAN2.";
CM_ SG_ 1412 BRAKE_OD_CAN2_Baudrate "Baudrate of CAN.";
CM_ SG_ 1412 BRAKE_OD_CAN2_autoErrorReset "Automatic reset of errors.";
CM_ SG_ 1412 BRAKE_OD_CAN2_lastErrorCode "Last error code.";
CM_ SG_ 1412 BRAKE_OD_CAN2_RxErrCnt "Receive error count of CAN1.";
CM_ SG_ 1412 BRAKE_OD_CAN2_TxErrCnt "Transmit error count of CAN1.";
CM_ SG_ 1412 BRAKE_OD_CAN1_DelayedTxMessages "Number of delayed TX messages on CAN1 because no messagebox was free.";
CM_ SG_ 1412 BRAKE_OD_CAN1_ErrorStatus "Internal error status (e.g. Error active, Error passive, Bus Off)";
CM_ SG_ 1412 BRAKE_OD_CAN1_DiscardedTxMessage "Number of discarded TX messages on CAN1 because all messageboxes were full";
CM_ SG_ 1412 BRAKE_OD_CAN1_Status "Status of CAN1.";
CM_ SG_ 1412 BRAKE_OD_CAN1_Baudrate "Baudrate of CAN.";
CM_ SG_ 1412 BRAKE_OD_CAN1_autoErrorReset "Automatic reset of errors.";
CM_ SG_ 1412 BRAKE_OD_CAN1_lastErrorCode "Last error code.";
CM_ SG_ 1412 BRAKE_OD_CAN1_RxErrCnt "Receive error count of CAN1.";
CM_ SG_ 1412 BRAKE_OD_CAN1_TxErrCnt "Transmit error count of CAN1.";
CM_ SG_ 1412 BRAKE_OD_BuildTime "Software build time in the format HHMMSS.";
CM_ SG_ 1412 BRAKE_OD_BuildDate "Software build date in the format YYYYMMDD.";
CM_ SG_ 1412 BRAKE_OD_ChipUID2 "Seccond part of unique ID of microcontroller.";
CM_ SG_ 1412 BRAKE_OD_ChipUID1 "First part of unique ID of microcontroller.";
CM_ SG_ 1412 BRAKE_OD_SdcOut "Measurement of Shutdown Circuit Output";
CM_ SG_ 1412 BRAKE_OD_SdcIn "Measurement of Shutdown Circuit Input";
CM_ SG_ 1412 BRAKE_OD_runtime "Runtime of chip in milliseconds.";
CM_ SG_ 1412 BRAKE_OD_InputVoltage "Board supply voltage.";
CM_ SG_ 1412 BRAKE_OD_BoardTemp "Temperature of board";
CM_ SG_ 1412 BRAKE_OD_MemFree "Free memory in bytes.";
CM_ SG_ 1412 BRAKE_OD_CpuUsage "Current CPU usage in %.";
CM_ SG_ 1412 BRAKE_OD_OdEntrySendInterval "Interval for sending all readable OD entries. Sending is disabled if less than 5 ms.";
CM_ SG_ 1412 BRAKE_OD_SendOdOnBootup "Whether to send all OD entries on bootup.";
CM_ SG_ 1412 BRAKE_OD_HeartbeatInterval "Heartbeat Interval in milliseconds.";
CM_ SG_ 1412 BRAKE_OD_DbcVersion "CANzero DBC version.";
CM_ SG_ 1412 BRAKE_OD_StackVersion "CANzero stack version.";
CM_ SG_ 1412 BRAKE_OD_ProtocolVersion "CANzero Protocol Version.";
CM_ SG_ 1412 BRAKE_OD_NodeStatus "State of the node.";
CM_ SG_ 1412 BRAKE_OD_NodeID "CANzero Node-ID.";
CM_ SG_ 1412 BRAKE_SDO_RespCode "Response code of SDO access.";
CM_ SG_ 1412 BRAKE_SDO_ID "Specifies SDO-ID of BRAKE";
CM_ BO_ 1476 "DO NOT CHANGE ANYTHING HERE!
SDO Request Upload to node BRAKE with Node-ID 0x4";
CM_ SG_ 1476 BRAKE_OD_CAN2_DelayedTxMessages "Number of delayed TX messages on CAN2 because no messagebox was free.";
CM_ SG_ 1476 BRAKE_OD_CAN2_ErrorStatus "Internal error status (e.g. Error active, Error passive, Bus Off)";
CM_ SG_ 1476 BRAKE_OD_CAN2_DiscardedTxMe_0000 "Number of discarded TX messages on CAN2 because all messageboxes were full";
CM_ SG_ 1476 BRAKE_OD_CAN2_Status "Status of CAN2.";
CM_ SG_ 1476 BRAKE_OD_CAN2_Baudrate "Baudrate of CAN.";
CM_ SG_ 1476 BRAKE_OD_CAN2_autoErrorReset "Automatic reset of errors.";
CM_ SG_ 1476 BRAKE_OD_CAN2_lastErrorCode "Last error code.";
CM_ SG_ 1476 BRAKE_OD_CAN2_RxErrCnt "Receive error count of CAN1.";
CM_ SG_ 1476 BRAKE_OD_CAN2_TxErrCnt "Transmit error count of CAN1.";
CM_ SG_ 1476 BRAKE_OD_CAN1_DelayedTxMessages "Number of delayed TX messages on CAN1 because no messagebox was free.";
CM_ SG_ 1476 BRAKE_OD_CAN1_ErrorStatus "Internal error status (e.g. Error active, Error passive, Bus Off)";
CM_ SG_ 1476 BRAKE_OD_CAN1_DiscardedTxMe_0000 "Number of discarded TX messages on CAN1 because all messageboxes were full";
CM_ SG_ 1476 BRAKE_OD_CAN1_Status "Status of CAN1.";
CM_ SG_ 1476 BRAKE_OD_CAN1_Baudrate "Baudrate of CAN.";
CM_ SG_ 1476 BRAKE_OD_CAN1_autoErrorReset "Automatic reset of errors.";
CM_ SG_ 1476 BRAKE_OD_CAN1_lastErrorCode "Last error code.";
CM_ SG_ 1476 BRAKE_OD_CAN1_RxErrCnt "Receive error count of CAN1.";
CM_ SG_ 1476 BRAKE_OD_CAN1_TxErrCnt "Transmit error count of CAN1.";
CM_ SG_ 1476 BRAKE_OD_BuildTime "Software build time in the format HHMMSS.";
CM_ SG_ 1476 BRAKE_OD_BuildDate "Software build date in the format YYYYMMDD.";
CM_ SG_ 1476 BRAKE_OD_ChipUID2 "Seccond part of unique ID of microcontroller.";
CM_ SG_ 1476 BRAKE_OD_ChipUID1 "First part of unique ID of microcontroller.";
CM_ SG_ 1476 BRAKE_OD_SdcOut "Measurement of Shutdown Circuit Output";
CM_ SG_ 1476 BRAKE_OD_SdcIn "Measurement of Shutdown Circuit Input";
CM_ SG_ 1476 BRAKE_OD_runtime "Runtime of chip in milliseconds.";
CM_ SG_ 1476 BRAKE_OD_InputVoltage "Board supply voltage.";
CM_ SG_ 1476 BRAKE_OD_BoardTemp "Temperature of board";
CM_ SG_ 1476 BRAKE_OD_MemFree "Free memory in bytes.";
CM_ SG_ 1476 BRAKE_OD_CpuUsage "Current CPU usage in %.";
CM_ SG_ 1476 BRAKE_OD_OdEntrySendInterval "Interval for sending all readable OD entries. Sending is disabled if less than 5 ms.";
CM_ SG_ 1476 BRAKE_OD_SendOdOnBootup "Whether to send all OD entries on bootup.";
CM_ SG_ 1476 BRAKE_OD_HeartbeatInterval "Heartbeat Interval in milliseconds.";
CM_ SG_ 1476 BRAKE_OD_DbcVersion "CANzero DBC version.";
CM_ SG_ 1476 BRAKE_OD_StackVersion "CANzero stack version.";
CM_ SG_ 1476 BRAKE_OD_ProtocolVersion "CANzero Protocol Version.";
CM_ SG_ 1476 BRAKE_OD_NodeStatus "State of the node.";
CM_ SG_ 1476 BRAKE_OD_NodeID "CANzero Node-ID.";
CM_ SG_ 1476 BRAKE_SDO_ID "Specifies SDO-ID of BRAKE";
CM_ BO_ 1540 "DO NOT CHANGE ANYTHING HERE!
SDO Request Download from node BRAKE with Node-ID 0x4";
CM_ SG_ 1540 BRAKE_SDO_ID "Specifies SDO-ID of BRAKE";
CM_ BO_ 1796 "Heartbeat of node BRAKE with Node-ID 0x4";
CM_ SG_ 1796 BRAKE_NodeState "Heartbeat status of node BRAKE";
CM_ BO_ 1860 "Bootloader transmit from node BRAKE with Node-ID 0x4";
CM_ BO_ 1924 "Bootloader receive by node BRAKE with Node-ID 0x4";
CM_ BO_ 133 "Emergency message of node MLU_1 with Node-ID 0x5";
CM_ SG_ 133 MLU_1_E0_OtherError "Other error.";
CM_ SG_ 133 MLU_1_W0_OtherWarning "Other warning.";
CM_ BO_ 389 "Transmit PDO 1 of node MLU_1 with Node-ID 0x5";
CM_ BO_ 453 "Receive PDO 1 of node MLU_1 with Node-ID 0x5";
CM_ BO_ 517 "Transmit PDO 2 of node MLU_1 with Node-ID 0x5";
CM_ BO_ 581 "Receive PDO 2 of node MLU_1 with Node-ID 0x5";
CM_ BO_ 645 "Transmit PDO 3 of node MLU_1 with Node-ID 0x5";
CM_ BO_ 709 "Receive PDO 3 of node MLU_1 with Node-ID 0x5";
CM_ BO_ 773 "Transmit PDO 4 of node MLU_1 with Node-ID 0x5";
CM_ BO_ 837 "Receive PDO 4 of node MLU_1 with Node-ID 0x5";
CM_ BO_ 901 "Transmit PDO 5 of node MLU_1 with Node-ID 0x5";
CM_ BO_ 965 "Transmit PDO 6 of node MLU_1 with Node-ID 0x5";
CM_ BO_ 1029 "Transmit PDO 7 of node MLU_1 with Node-ID 0x5";
CM_ BO_ 1093 "Transmit PDO 8 of node MLU_1 with Node-ID 0x5";
CM_ BO_ 1157 "Transmit PDO 9 of node MLU_1 with Node-ID 0x5";
CM_ BO_ 1221 "Transmit PDO 10 of node MLU_1 with Node-ID 0x5";
CM_ BO_ 1285 "Transmit PDO 11 of node MLU_1 with Node-ID 0x5";
CM_ BO_ 1349 "Transmit PDO 12 of node MLU_1 with Node-ID 0x5";
CM_ BO_ 1413 "DO NOT CHANGE ANYTHING HERE!
SDO Response of node MLU_1 with Node-ID 0x5";
CM_ SG_ 1413 MLU_1_OD_CAN2_DelayedTxMessages "Number of delayed TX messages on CAN2 because no messagebox was free.";
CM_ SG_ 1413 MLU_1_OD_CAN2_ErrorStatus "Internal error status (e.g. Error active, Error passive, Bus Off)";
CM_ SG_ 1413 MLU_1_OD_CAN2_DiscardedTxMessage "Number of discarded TX messages on CAN2 because all messageboxes were full";
CM_ SG_ 1413 MLU_1_OD_CAN2_Status "Status of CAN2.";
CM_ SG_ 1413 MLU_1_OD_CAN2_Baudrate "Baudrate of CAN.";
CM_ SG_ 1413 MLU_1_OD_CAN2_autoErrorReset "Automatic reset of errors.";
CM_ SG_ 1413 MLU_1_OD_CAN2_lastErrorCode "Last error code.";
CM_ SG_ 1413 MLU_1_OD_CAN2_RxErrCnt "Receive error count of CAN1.";
CM_ SG_ 1413 MLU_1_OD_CAN2_TxErrCnt "Transmit error count of CAN1.";
CM_ SG_ 1413 MLU_1_OD_CAN1_DelayedTxMessages "Number of delayed TX messages on CAN1 because no messagebox was free.";
CM_ SG_ 1413 MLU_1_OD_CAN1_ErrorStatus "Internal error status (e.g. Error active, Error passive, Bus Off)";
CM_ SG_ 1413 MLU_1_OD_CAN1_DiscardedTxMessage "Number of discarded TX messages on CAN1 because all messageboxes were full";
CM_ SG_ 1413 MLU_1_OD_CAN1_Status "Status of CAN1.";
CM_ SG_ 1413 MLU_1_OD_CAN1_Baudrate "Baudrate of CAN.";
CM_ SG_ 1413 MLU_1_OD_CAN1_autoErrorReset "Automatic reset of errors.";
CM_ SG_ 1413 MLU_1_OD_CAN1_lastErrorCode "Last error code.";
CM_ SG_ 1413 MLU_1_OD_CAN1_RxErrCnt "Receive error count of CAN1.";
CM_ SG_ 1413 MLU_1_OD_CAN1_TxErrCnt "Transmit error count of CAN1.";
CM_ SG_ 1413 MLU_1_OD_BuildTime "Software build time in the format HHMMSS.";
CM_ SG_ 1413 MLU_1_OD_BuildDate "Software build date in the format YYYYMMDD.";
CM_ SG_ 1413 MLU_1_OD_ChipUID2 "Seccond part of unique ID of microcontroller.";
CM_ SG_ 1413 MLU_1_OD_ChipUID1 "First part of unique ID of microcontroller.";
CM_ SG_ 1413 MLU_1_OD_SdcOut "Measurement of Shutdown Circuit Output";
CM_ SG_ 1413 MLU_1_OD_SdcIn "Measurement of Shutdown Circuit Input";
CM_ SG_ 1413 MLU_1_OD_runtime "Runtime of chip in milliseconds.";
CM_ SG_ 1413 MLU_1_OD_InputVoltage "Board supply voltage.";
CM_ SG_ 1413 MLU_1_OD_BoardTemp "Temperature of board";
CM_ SG_ 1413 MLU_1_OD_MemFree "Free memory in bytes.";
CM_ SG_ 1413 MLU_1_OD_CpuUsage "Current CPU usage in %.";
CM_ SG_ 1413 MLU_1_OD_OdEntrySendInterval "Interval for sending all readable OD entries. Sending is disabled if less than 5 ms.";
CM_ SG_ 1413 MLU_1_OD_SendOdOnBootup "Whether to send all OD entries on bootup.";
CM_ SG_ 1413 MLU_1_OD_HeartbeatInterval "Heartbeat Interval in milliseconds.";
CM_ SG_ 1413 MLU_1_OD_DbcVersion "CANzero DBC version.";
CM_ SG_ 1413 MLU_1_OD_StackVersion "CANzero stack version.";
CM_ SG_ 1413 MLU_1_OD_ProtocolVersion "CANzero Protocol Version.";
CM_ SG_ 1413 MLU_1_OD_NodeStatus "State of the node.";
CM_ SG_ 1413 MLU_1_OD_NodeID "CANzero Node-ID.";
CM_ SG_ 1413 MLU_1_SDO_RespCode "Response code of SDO access.";
CM_ SG_ 1413 MLU_1_SDO_ID "Specifies SDO-ID of MLU_1";
CM_ BO_ 1477 "DO NOT CHANGE ANYTHING HERE!
SDO Request Upload to node MLU_1 with Node-ID 0x5";
CM_ SG_ 1477 MLU_1_OD_CAN2_DelayedTxMessages "Number of delayed TX messages on CAN2 because no messagebox was free.";
CM_ SG_ 1477 MLU_1_OD_CAN2_ErrorStatus "Internal error status (e.g. Error active, Error passive, Bus Off)";
CM_ SG_ 1477 MLU_1_OD_CAN2_DiscardedTxMe_0000 "Number of discarded TX messages on CAN2 because all messageboxes were full";
CM_ SG_ 1477 MLU_1_OD_CAN2_Status "Status of CAN2.";
CM_ SG_ 1477 MLU_1_OD_CAN2_Baudrate "Baudrate of CAN.";
CM_ SG_ 1477 MLU_1_OD_CAN2_autoErrorReset "Automatic reset of errors.";
CM_ SG_ 1477 MLU_1_OD_CAN2_lastErrorCode "Last error code.";
CM_ SG_ 1477 MLU_1_OD_CAN2_RxErrCnt "Receive error count of CAN1.";
CM_ SG_ 1477 MLU_1_OD_CAN2_TxErrCnt "Transmit error count of CAN1.";
CM_ SG_ 1477 MLU_1_OD_CAN1_DelayedTxMessages "Number of delayed TX messages on CAN1 because no messagebox was free.";
CM_ SG_ 1477 MLU_1_OD_CAN1_ErrorStatus "Internal error status (e.g. Error active, Error passive, Bus Off)";
CM_ SG_ 1477 MLU_1_OD_CAN1_DiscardedTxMe_0000 "Number of discarded TX messages on CAN1 because all messageboxes were full";
CM_ SG_ 1477 MLU_1_OD_CAN1_Status "Status of CAN1.";
CM_ SG_ 1477 MLU_1_OD_CAN1_Baudrate "Baudrate of CAN.";
CM_ SG_ 1477 MLU_1_OD_CAN1_autoErrorReset "Automatic reset of errors.";
CM_ SG_ 1477 MLU_1_OD_CAN1_lastErrorCode "Last error code.";
CM_ SG_ 1477 MLU_1_OD_CAN1_RxErrCnt "Receive error count of CAN1.";
CM_ SG_ 1477 MLU_1_OD_CAN1_TxErrCnt "Transmit error count of CAN1.";
CM_ SG_ 1477 MLU_1_OD_BuildTime "Software build time in the format HHMMSS.";
CM_ SG_ 1477 MLU_1_OD_BuildDate "Software build date in the format YYYYMMDD.";
CM_ SG_ 1477 MLU_1_OD_ChipUID2 "Seccond part of unique ID of microcontroller.";
CM_ SG_ 1477 MLU_1_OD_ChipUID1 "First part of unique ID of microcontroller.";
CM_ SG_ 1477 MLU_1_OD_SdcOut "Measurement of Shutdown Circuit Output";
CM_ SG_ 1477 MLU_1_OD_SdcIn "Measurement of Shutdown Circuit Input";
CM_ SG_ 1477 MLU_1_OD_runtime "Runtime of chip in milliseconds.";
CM_ SG_ 1477 MLU_1_OD_InputVoltage "Board supply voltage.";
CM_ SG_ 1477 MLU_1_OD_BoardTemp "Temperature of board";
CM_ SG_ 1477 MLU_1_OD_MemFree "Free memory in bytes.";
CM_ SG_ 1477 MLU_1_OD_CpuUsage "Current CPU usage in %.";
CM_ SG_ 1477 MLU_1_OD_OdEntrySendInterval "Interval for sending all readable OD entries. Sending is disabled if less than 5 ms.";
CM_ SG_ 1477 MLU_1_OD_SendOdOnBootup "Whether to send all OD entries on bootup.";
CM_ SG_ 1477 MLU_1_OD_HeartbeatInterval "Heartbeat Interval in milliseconds.";
CM_ SG_ 1477 MLU_1_OD_DbcVersion "CANzero DBC version.";
CM_ SG_ 1477 MLU_1_OD_StackVersion "CANzero stack version.";
CM_ SG_ 1477 MLU_1_OD_ProtocolVersion "CANzero Protocol Version.";
CM_ SG_ 1477 MLU_1_OD_NodeStatus "State of the node.";
CM_ SG_ 1477 MLU_1_OD_NodeID "CANzero Node-ID.";
CM_ SG_ 1477 MLU_1_SDO_ID "Specifies SDO-ID of MLU_1";
CM_ BO_ 1541 "DO NOT CHANGE ANYTHING HERE!
SDO Request Download from node MLU_1 with Node-ID 0x5";
CM_ SG_ 1541 MLU_1_SDO_ID "Specifies SDO-ID of MLU_1";
CM_ BO_ 1797 "Heartbeat of node MLU_1 with Node-ID 0x5";
CM_ SG_ 1797 MLU_1_NodeState "Heartbeat status of node MLU_1";
CM_ BO_ 1861 "Bootloader transmit from node MLU_1 with Node-ID 0x5";
BA_DEF_ SG_  "GenSigSendType" ENUM  "Cyclic","OnWrite","OnWriteWithRepetition","OnChange","OnChangeWithRepetition","IfActive","IfActiveWithRepetition","NoSigSendType";
BA_DEF_ BO_  "GenMsgSendType" ENUM  "Cyclic","not_used","not_used","not_used","not_used","Cyclic","not_used","IfActive","NoMsgSendType";
BA_DEF_  "BusType" STRING ;
BA_DEF_  "DBName" STRING ;
BA_DEF_ BO_  "GenMsgCycleTime" INT 2 50000;
BA_DEF_ BO_  "GenMsgDelayTime" INT 1 1000;
BA_DEF_ BO_  "GenMsgNrOfRepetitions" INT 1 999999;
BA_DEF_ SG_  "GenSigStartValue" FLOAT 0 100000000000;
BA_DEF_  "CANzero_ProtocolVersion" STRING ;
BA_DEF_  "CANzero_DBCVersion" INT 0 16777215;
BA_DEF_  "CANzero_SDOClientName" STRING ;
BA_DEF_  "CANzero_NMTMasterName" STRING ;
BA_DEF_ BU_  "CANzero_NodeID" HEX 0 63;
BA_DEF_ SG_  "CANzero_SDO_Group" STRING ;
BA_DEF_ SG_  "CANzero_SDO_AccessIfOperational" ENUM  "No","Yes";
BA_DEF_ SG_  "CANzero_SDO_AccessType" ENUM  "Read Write","Read Only","Write Only";
BA_DEF_ SG_  "CANzero_SDO_Default" FLOAT 0 0;
BA_DEF_ SG_  "SystemSignalLongSymbol" STRING ;
BA_DEF_DEF_  "GenSigSendType" "Cyclic";
BA_DEF_DEF_  "GenMsgSendType" "NoMsgSendType";
BA_DEF_DEF_  "BusType" "";
BA_DEF_DEF_  "DBName" "";
BA_DEF_DEF_  "GenMsgCycleTime" 100;
BA_DEF_DEF_  "GenMsgDelayTime" 1;
BA_DEF_DEF_  "GenMsgNrOfRepetitions" 1;
BA_DEF_DEF_  "GenSigStartValue" 0;
BA_DEF_DEF_  "CANzero_ProtocolVersion" "";
BA_DEF_DEF_  "CANzero_DBCVersion" 0;
BA_DEF_DEF_  "CANzero_SDOClientName" "Master";
BA_DEF_DEF_  "CANzero_NMTMasterName" "Master";
BA_DEF_DEF_  "CANzero_NodeID" 0;
BA_DEF_DEF_  "CANzero_SDO_Group" "";
BA_DEF_DEF_  "CANzero_SDO_AccessIfOperational" "No";
BA_DEF_DEF_  "CANzero_SDO_AccessType" "Read Write";
BA_DEF_DEF_  "CANzero_SDO_Default" 0;
BA_DEF_DEF_  "SystemSignalLongSymbol" "";
BA_ "CANzero_SDOClientName" "TelemetryNode";
BA_ "CANzero_DBCVersion" 27;
BA_ "CANzero_ProtocolVersion" "V1.0";
BA_ "BusType" "CAN";
BA_ "DBName" "database";
BA_ "CANzero_NodeID" BU_ SENSOR 1;
BA_ "CANzero_NodeID" BU_ PDU 2;
BA_ "CANzero_NodeID" BU_ CLU 3;
BA_ "CANzero_NodeID" BU_ BRAKE 4;
BA_ "CANzero_NodeID" BU_ MLU_1 5;
BA_ "CANzero_NodeID" BU_ MLU_2 6;
BA_ "CANzero_NodeID" BU_ MLU_3 7;
BA_ "CANzero_NodeID" BU_ MLU_4 8;
BA_ "CANzero_NodeID" BU_ MLU_5 9;
BA_ "CANzero_NodeID" BU_ MLU_6 16;
BA_ "SystemSignalLongSymbol" SG_ 129 SENSOR_W4_PressureSensorPlausibi "SENSOR_W4_PressureSensorPlausibilityCheckFailed";
BA_ "SystemSignalLongSymbol" SG_ 129 SENSOR_W3_TemperaturSensorPlausi "SENSOR_W3_TemperaturSensorPlausibilityCheckFailed";
BA_ "CANzero_SDO_AccessType" SG_ 1409 SENSOR_OD_IMU3_Temperature 1;
BA_ "CANzero_SDO_AccessIfOperational" SG_ 1409 SENSOR_OD_IMU3_Temperature 1;
BA_ "GenSigStartValue" SG_ 1409 SENSOR_OD_IMU3_Temperature 10000.0;
BA_ "CANzero_SDO_AccessType" SG_ 1409 SENSOR_OD_IMU2_Temperature 1;
BA_ "CANzero_SDO_AccessIfOperational" SG_ 1409 SENSOR_OD_IMU2_Temperature 1;
BA_ "GenSigStartValue" SG_ 1409 SENSOR_OD_IMU2_Temperature 10000.0;
BA_ "CANzero_SDO_AccessType" SG_ 1409 SENSOR_OD_IMU1_Temperature 1;
BA_ "CANzero_SDO_AccessIfOperational" SG_ 1409 SENSOR_OD_IMU1_Temperature 1;
BA_ "GenSigStartValue" SG_ 1409 SENSOR_OD_IMU1_Temperature 10000.0;
BA_ "CANzero_SDO_AccessType" SG_ 1409 SENSOR_OD_IMU_number 1;
BA_ "CANzero_SDO_AccessIfOperational" SG_ 1409 SENSOR_OD_IMU_number 1;
BA_ "CANzero_SDO_Group" SG_ 1409 SENSOR_OD_CAN2_DelayedTxMessages "CAN";
BA_ "CANzero_SDO_AccessType" SG_ 1409 SENSOR_OD_CAN2_DelayedTxMessages 1;
BA_ "CANzero_SDO_AccessIfOperational" SG_ 1409 SENSOR_OD_CAN2_DelayedTxMessages 1;
BA_ "CANzero_SDO_Group" SG_ 1409 SENSOR_OD_CAN2_ErrorStatus "CAN";
BA_ "CANzero_SDO_AccessType" SG_ 1409 SENSOR_OD_CAN2_ErrorStatus 1;
BA_ "CANzero_SDO_AccessIfOperational" SG_ 1409 SENSOR_OD_CAN2_ErrorStatus 1;
BA_ "CANzero_SDO_Group" SG_ 1409 SENSOR_OD_CAN2_DiscardedTxMessag "CAN";
BA_ "CANzero_SDO_AccessType" SG_ 1409 SENSOR_OD_CAN2_DiscardedTxMessag 1;
BA_ "CANzero_SDO_AccessIfOperational" SG_ 1409 SENSOR_OD_CAN2_DiscardedTxMessag 1;
BA_ "SystemSignalLongSymbol" SG_ 1409 SENSOR_OD_CAN2_DiscardedTxMessag "SENSOR_OD_CAN2_DiscardedTxMessages";
BA_ "CANzero_SDO_Group" SG_ 1409 SENSOR_OD_CAN2_Status "CAN";
BA_ "CANzero_SDO_AccessType" SG_ 1409 SENSOR_OD_CAN2_Status 1;
BA_ "CANzero_SDO_AccessIfOperational" SG_ 1409 SENSOR_OD_CAN2_Status 1;
BA_ "CANzero_SDO_Group" SG_ 1409 SENSOR_OD_CAN2_Baudrate "CAN";
BA_ "CANzero_SDO_AccessIfOperational" SG_ 1409 SENSOR_OD_CAN2_Baudrate 1;
BA_ "GenSigStartValue" SG_ 1409 SENSOR_OD_CAN2_Baudrate 1000.0;
BA_ "CANzero_SDO_Default" SG_ 1409 SENSOR_OD_CAN2_Baudrate 1000;
BA_ "CANzero_SDO_Group" SG_ 1409 SENSOR_OD_CAN2_autoErrorReset "CAN";
BA_ "CANzero_SDO_AccessIfOperational" SG_ 1409 SENSOR_OD_CAN2_autoErrorReset 1;
BA_ "GenSigStartValue" SG_ 1409 SENSOR_OD_CAN2_autoErrorReset 1.0;
BA_ "CANzero_SDO_Default" SG_ 1409 SENSOR_OD_CAN2_autoErrorReset 1;
BA_ "CANzero_SDO_Group" SG_ 1409 SENSOR_OD_CAN2_lastErrorCode "CAN";
BA_ "CANzero_SDO_AccessType" SG_ 1409 SENSOR_OD_CAN2_lastErrorCode 1;
BA_ "CANzero_SDO_AccessIfOperational" SG_ 1409 SENSOR_OD_CAN2_lastErrorCode 1;
BA_ "CANzero_SDO_Group" SG_ 1409 SENSOR_OD_CAN2_RxErrCnt "CAN";
BA_ "CANzero_SDO_AccessType" SG_ 1409 SENSOR_OD_CAN2_RxErrCnt 1;
BA_ "CANzero_SDO_AccessIfOperational" SG_ 1409 SENSOR_OD_CAN2_RxErrCnt 1;
BA_ "CANzero_SDO_Group" SG_ 1409 SENSOR_OD_CAN2_TxErrCnt "CAN";
BA_ "CANzero_SDO_AccessType" SG_ 1409 SENSOR_OD_CAN2_TxErrCnt 1;
BA_ "CANzero_SDO_AccessIfOperational" SG_ 1409 SENSOR_OD_CAN2_TxErrCnt 1;
BA_ "CANzero_SDO_Group" SG_ 1409 SENSOR_OD_CAN1_DelayedTxMessages "CAN";
BA_ "CANzero_SDO_AccessType" SG_ 1409 SENSOR_OD_CAN1_DelayedTxMessages 1;
BA_ "CANzero_SDO_AccessIfOperational" SG_ 1409 SENSOR_OD_CAN1_DelayedTxMessages 1;
BA_ "CANzero_SDO_Group" SG_ 1409 SENSOR_OD_CAN1_ErrorStatus "CAN";
BA_ "CANzero_SDO_AccessType" SG_ 1409 SENSOR_OD_CAN1_ErrorStatus 1;
BA_ "CANzero_SDO_AccessIfOperational" SG_ 1409 SENSOR_OD_CAN1_ErrorStatus 1;
BA_ "CANzero_SDO_Group" SG_ 1409 SENSOR_OD_CAN1_DiscardedTxMessag "CAN";
BA_ "CANzero_SDO_AccessType" SG_ 1409 SENSOR_OD_CAN1_DiscardedTxMessag 1;
BA_ "CANzero_SDO_AccessIfOperational" SG_ 1409 SENSOR_OD_CAN1_DiscardedTxMessag 1;
BA_ "SystemSignalLongSymbol" SG_ 1409 SENSOR_OD_CAN1_DiscardedTxMessag "SENSOR_OD_CAN1_DiscardedTxMessages";
BA_ "CANzero_SDO_Group" SG_ 1409 SENSOR_OD_CAN1_Status "CAN";
BA_ "CANzero_SDO_AccessType" SG_ 1409 SENSOR_OD_CAN1_Status 1;
BA_ "CANzero_SDO_AccessIfOperational" SG_ 1409 SENSOR_OD_CAN1_Status 1;
BA_ "CANzero_SDO_Group" SG_ 1409 SENSOR_OD_CAN1_Baudrate "CAN";
BA_ "CANzero_SDO_AccessIfOperational" SG_ 1409 SENSOR_OD_CAN1_Baudrate 1;
BA_ "GenSigStartValue" SG_ 1409 SENSOR_OD_CAN1_Baudrate 1000.0;
BA_ "CANzero_SDO_Default" SG_ 1409 SENSOR_OD_CAN1_Baudrate 1000;
BA_ "CANzero_SDO_Group" SG_ 1409 SENSOR_OD_CAN1_autoErrorReset "CAN";
BA_ "CANzero_SDO_AccessIfOperational" SG_ 1409 SENSOR_OD_CAN1_autoErrorReset 1;
BA_ "GenSigStartValue" SG_ 1409 SENSOR_OD_CAN1_autoErrorReset 1.0;
BA_ "CANzero_SDO_Default" SG_ 1409 SENSOR_OD_CAN1_autoErrorReset 1;
BA_ "CANzero_SDO_Group" SG_ 1409 SENSOR_OD_CAN1_lastErrorCode "CAN";
BA_ "CANzero_SDO_AccessType" SG_ 1409 SENSOR_OD_CAN1_lastErrorCode 1;
BA_ "CANzero_SDO_AccessIfOperational" SG_ 1409 SENSOR_OD_CAN1_lastErrorCode 1;
BA_ "CANzero_SDO_Group" SG_ 1409 SENSOR_OD_CAN1_RxErrCnt "CAN";
BA_ "CANzero_SDO_AccessType" SG_ 1409 SENSOR_OD_CAN1_RxErrCnt 1;
BA_ "CANzero_SDO_AccessIfOperational" SG_ 1409 SENSOR_OD_CAN1_RxErrCnt 1;
BA_ "CANzero_SDO_Group" SG_ 1409 SENSOR_OD_CAN1_TxErrCnt "CAN";
BA_ "CANzero_SDO_AccessType" SG_ 1409 SENSOR_OD_CAN1_TxErrCnt 1;
BA_ "CANzero_SDO_AccessIfOperational" SG_ 1409 SENSOR_OD_CAN1_TxErrCnt 1;
BA_ "CANzero_SDO_AccessType" SG_ 1409 SENSOR_OD_BuildTime 1;
BA_ "CANzero_SDO_AccessIfOperational" SG_ 1409 SENSOR_OD_BuildTime 1;
BA_ "CANzero_SDO_AccessType" SG_ 1409 SENSOR_OD_BuildDate 1;
BA_ "CANzero_SDO_AccessIfOperational" SG_ 1409 SENSOR_OD_BuildDate 1;
BA_ "CANzero_SDO_AccessType" SG_ 1409 SENSOR_OD_ChipUID2 1;
BA_ "CANzero_SDO_AccessIfOperational" SG_ 1409 SENSOR_OD_ChipUID2 1;
BA_ "CANzero_SDO_AccessType" SG_ 1409 SENSOR_OD_ChipUID1 1;
BA_ "CANzero_SDO_AccessIfOperational" SG_ 1409 SENSOR_OD_ChipUID1 1;
BA_ "CANzero_SDO_AccessType" SG_ 1409 SENSOR_OD_SdcOut 1;
BA_ "CANzero_SDO_AccessIfOperational" SG_ 1409 SENSOR_OD_SdcOut 1;
BA_ "CANzero_SDO_AccessType" SG_ 1409 SENSOR_OD_SdcIn 1;
BA_ "CANzero_SDO_AccessIfOperational" SG_ 1409 SENSOR_OD_SdcIn 1;
BA_ "CANzero_SDO_AccessType" SG_ 1409 SENSOR_OD_runtime 1;
BA_ "CANzero_SDO_AccessIfOperational" SG_ 1409 SENSOR_OD_runtime 1;
BA_ "CANzero_SDO_AccessType" SG_ 1409 SENSOR_OD_InputVoltage 1;
BA_ "CANzero_SDO_AccessIfOperational" SG_ 1409 SENSOR_OD_InputVoltage 1;
BA_ "CANzero_SDO_AccessType" SG_ 1409 SENSOR_OD_BoardTemp 1;
BA_ "CANzero_SDO_AccessIfOperational" SG_ 1409 SENSOR_OD_BoardTemp 1;
BA_ "GenSigStartValue" SG_ 1409 SENSOR_OD_BoardTemp 3000.0;
BA_ "CANzero_SDO_AccessType" SG_ 1409 SENSOR_OD_MemFree 1;
BA_ "CANzero_SDO_AccessIfOperational" SG_ 1409 SENSOR_OD_MemFree 1;
BA_ "CANzero_SDO_AccessType" SG_ 1409 SENSOR_OD_CpuUsage 1;
BA_ "CANzero_SDO_AccessIfOperational" SG_ 1409 SENSOR_OD_CpuUsage 1;
BA_ "CANzero_SDO_AccessIfOperational" SG_ 1409 SENSOR_OD_OdEntrySendInterval 1;
BA_ "GenSigStartValue" SG_ 1409 SENSOR_OD_OdEntrySendInterval 50.0;
BA_ "CANzero_SDO_Default" SG_ 1409 SENSOR_OD_OdEntrySendInterval 50;
BA_ "CANzero_SDO_AccessIfOperational" SG_ 1409 SENSOR_OD_SendOdOnBootup 1;
BA_ "CANzero_SDO_AccessIfOperational" SG_ 1409 SENSOR_OD_HeartbeatInterval 1;
BA_ "GenSigStartValue" SG_ 1409 SENSOR_OD_HeartbeatInterval 250.0;
BA_ "CANzero_SDO_Default" SG_ 1409 SENSOR_OD_HeartbeatInterval 250;
BA_ "CANzero_SDO_AccessType" SG_ 1409 SENSOR_OD_DbcVersion 1;
BA_ "CANzero_SDO_AccessIfOperational" SG_ 1409 SENSOR_OD_DbcVersion 1;
BA_ "CANzero_SDO_AccessType" SG_ 1409 SENSOR_OD_StackVersion 1;
BA_ "CANzero_SDO_AccessIfOperational" SG_ 1409 SENSOR_OD_StackVersion 1;
BA_ "CANzero_SDO_AccessType" SG_ 1409 SENSOR_OD_ProtocolVersion 1;
BA_ "CANzero_SDO_AccessIfOperational" SG_ 1409 SENSOR_OD_ProtocolVersion 1;
BA_ "GenSigStartValue" SG_ 1409 SENSOR_OD_ProtocolVersion 1.0;
BA_ "CANzero_SDO_Default" SG_ 1409 SENSOR_OD_ProtocolVersion 1;
BA_ "CANzero_SDO_AccessType" SG_ 1409 SENSOR_OD_NodeStatus 1;
BA_ "CANzero_SDO_AccessIfOperational" SG_ 1409 SENSOR_OD_NodeStatus 1;
BA_ "CANzero_SDO_AccessType" SG_ 1409 SENSOR_OD_NodeID 1;
BA_ "CANzero_SDO_AccessIfOperational" SG_ 1409 SENSOR_OD_NodeID 1;
BA_ "CANzero_SDO_AccessType" SG_ 1473 SENSOR_OD_IMU3_Temperature 1;
BA_ "CANzero_SDO_AccessIfOperational" SG_ 1473 SENSOR_OD_IMU3_Temperature 1;
BA_ "GenSigStartValue" SG_ 1473 SENSOR_OD_IMU3_Temperature 10000.0;
BA_ "CANzero_SDO_AccessType" SG_ 1473 SENSOR_OD_IMU2_Temperature 1;
BA_ "CANzero_SDO_AccessIfOperational" SG_ 1473 SENSOR_OD_IMU2_Temperature 1;
BA_ "GenSigStartValue" SG_ 1473 SENSOR_OD_IMU2_Temperature 10000.0;
BA_ "CANzero_SDO_AccessType" SG_ 1473 SENSOR_OD_IMU1_Temperature 1;
BA_ "CANzero_SDO_AccessIfOperational" SG_ 1473 SENSOR_OD_IMU1_Temperature 1;
BA_ "GenSigStartValue" SG_ 1473 SENSOR_OD_IMU1_Temperature 10000.0;
BA_ "CANzero_SDO_AccessType" SG_ 1473 SENSOR_OD_IMU_number 1;
BA_ "CANzero_SDO_AccessIfOperational" SG_ 1473 SENSOR_OD_IMU_number 1;
BA_ "CANzero_SDO_Group" SG_ 1473 SENSOR_OD_CAN2_DelayedTxMessages "CAN";
BA_ "CANzero_SDO_AccessType" SG_ 1473 SENSOR_OD_CAN2_DelayedTxMessages 1;
BA_ "CANzero_SDO_AccessIfOperational" SG_ 1473 SENSOR_OD_CAN2_DelayedTxMessages 1;
BA_ "CANzero_SDO_Group" SG_ 1473 SENSOR_OD_CAN2_ErrorStatus "CAN";
BA_ "CANzero_SDO_AccessType" SG_ 1473 SENSOR_OD_CAN2_ErrorStatus 1;
BA_ "CANzero_SDO_AccessIfOperational" SG_ 1473 SENSOR_OD_CAN2_ErrorStatus 1;
BA_ "CANzero_SDO_Group" SG_ 1473 SENSOR_OD_CAN2_DiscardedTxM_0000 "CAN";
BA_ "CANzero_SDO_AccessType" SG_ 1473 SENSOR_OD_CAN2_DiscardedTxM_0000 1;
BA_ "CANzero_SDO_AccessIfOperational" SG_ 1473 SENSOR_OD_CAN2_DiscardedTxM_0000 1;
BA_ "SystemSignalLongSymbol" SG_ 1473 SENSOR_OD_CAN2_DiscardedTxM_0000 "SENSOR_OD_CAN2_DiscardedTxMessages";
BA_ "CANzero_SDO_Group" SG_ 1473 SENSOR_OD_CAN2_Status "CAN";
BA_ "CANzero_SDO_AccessType" SG_ 1473 SENSOR_OD_CAN2_Status 1;
BA_ "CANzero_SDO_AccessIfOperational" SG_ 1473 SENSOR_OD_CAN2_Status 1;
BA_ "CANzero_SDO_Group" SG_ 1473 SENSOR_OD_CAN2_Baudrate "CAN";
BA_ "CANzero_SDO_AccessIfOperational" SG_ 1473 SENSOR_OD_CAN2_Baudrate 1;
BA_ "GenSigStartValue" SG_ 1473 SENSOR_OD_CAN2_Baudrate 1000.0;
BA_ "CANzero_SDO_Default" SG_ 1473 SENSOR_OD_CAN2_Baudrate 1000;
BA_ "CANzero_SDO_Group" SG_ 1473 SENSOR_OD_CAN2_autoErrorReset "CAN";
BA_ "CANzero_SDO_AccessIfOperational" SG_ 1473 SENSOR_OD_CAN2_autoErrorReset 1;
BA_ "GenSigStartValue" SG_ 1473 SENSOR_OD_CAN2_autoErrorReset 1.0;
BA_ "CANzero_SDO_Default" SG_ 1473 SENSOR_OD_CAN2_autoErrorReset 1;
BA_ "CANzero_SDO_Group" SG_ 1473 SENSOR_OD_CAN2_lastErrorCode "CAN";
BA_ "CANzero_SDO_AccessType" SG_ 1473 SENSOR_OD_CAN2_lastErrorCode 1;
BA_ "CANzero_SDO_AccessIfOperational" SG_ 1473 SENSOR_OD_CAN2_lastErrorCode 1;
BA_ "CANzero_SDO_Group" SG_ 1473 SENSOR_OD_CAN2_RxErrCnt "CAN";
BA_ "CANzero_SDO_AccessType" SG_ 1473 SENSOR_OD_CAN2_RxErrCnt 1;
BA_ "CANzero_SDO_AccessIfOperational" SG_ 1473 SENSOR_OD_CAN2_RxErrCnt 1;
BA_ "CANzero_SDO_Group" SG_ 1473 SENSOR_OD_CAN2_TxErrCnt "CAN";
BA_ "CANzero_SDO_AccessType" SG_ 1473 SENSOR_OD_CAN2_TxErrCnt 1;
BA_ "CANzero_SDO_AccessIfOperational" SG_ 1473 SENSOR_OD_CAN2_TxErrCnt 1;
BA_ "CANzero_SDO_Group" SG_ 1473 SENSOR_OD_CAN1_DelayedTxMessages "CAN";
BA_ "CANzero_SDO_AccessType" SG_ 1473 SENSOR_OD_CAN1_DelayedTxMessages 1;
BA_ "CANzero_SDO_AccessIfOperational" SG_ 1473 SENSOR_OD_CAN1_DelayedTxMessages 1;
BA_ "CANzero_SDO_Group" SG_ 1473 SENSOR_OD_CAN1_ErrorStatus "CAN";
BA_ "CANzero_SDO_AccessType" SG_ 1473 SENSOR_OD_CAN1_ErrorStatus 1;
BA_ "CANzero_SDO_AccessIfOperational" SG_ 1473 SENSOR_OD_CAN1_ErrorStatus 1;
BA_ "CANzero_SDO_Group" SG_ 1473 SENSOR_OD_CAN1_DiscardedTxM_0000 "CAN";
BA_ "CANzero_SDO_AccessType" SG_ 1473 SENSOR_OD_CAN1_DiscardedTxM_0000 1;
BA_ "CANzero_SDO_AccessIfOperational" SG_ 1473 SENSOR_OD_CAN1_DiscardedTxM_0000 1;
BA_ "SystemSignalLongSymbol" SG_ 1473 SENSOR_OD_CAN1_DiscardedTxM_0000 "SENSOR_OD_CAN1_DiscardedTxMessages";
BA_ "CANzero_SDO_Group" SG_ 1473 SENSOR_OD_CAN1_Status "CAN";
BA_ "CANzero_SDO_AccessType" SG_ 1473 SENSOR_OD_CAN1_Status 1;
BA_ "CANzero_SDO_AccessIfOperational" SG_ 1473 SENSOR_OD_CAN1_Status 1;
BA_ "CANzero_SDO_Group" SG_ 1473 SENSOR_OD_CAN1_Baudrate "CAN";
BA_ "CANzero_SDO_AccessIfOperational" SG_ 1473 SENSOR_OD_CAN1_Baudrate 1;
BA_ "GenSigStartValue" SG_ 1473 SENSOR_OD_CAN1_Baudrate 1000.0;
BA_ "CANzero_SDO_Default" SG_ 1473 SENSOR_OD_CAN1_Baudrate 1000;
BA_ "CANzero_SDO_Group" SG_ 1473 SENSOR_OD_CAN1_autoErrorReset "CAN";
BA_ "CANzero_SDO_AccessIfOperational" SG_ 1473 SENSOR_OD_CAN1_autoErrorReset 1;
BA_ "GenSigStartValue" SG_ 1473 SENSOR_OD_CAN1_autoErrorReset 1.0;
BA_ "CANzero_SDO_Default" SG_ 1473 SENSOR_OD_CAN1_autoErrorReset 1;
BA_ "CANzero_SDO_Group" SG_ 1473 SENSOR_OD_CAN1_lastErrorCode "CAN";
BA_ "CANzero_SDO_AccessType" SG_ 1473 SENSOR_OD_CAN1_lastErrorCode 1;
BA_ "CANzero_SDO_AccessIfOperational" SG_ 1473 SENSOR_OD_CAN1_lastErrorCode 1;
BA_ "CANzero_SDO_Group" SG_ 1473 SENSOR_OD_CAN1_RxErrCnt "CAN";
BA_ "CANzero_SDO_AccessType" SG_ 1473 SENSOR_OD_CAN1_RxErrCnt 1;
BA_ "CANzero_SDO_AccessIfOperational" SG_ 1473 SENSOR_OD_CAN1_RxErrCnt 1;
BA_ "CANzero_SDO_Group" SG_ 1473 SENSOR_OD_CAN1_TxErrCnt "CAN";
BA_ "CANzero_SDO_AccessType" SG_ 1473 SENSOR_OD_CAN1_TxErrCnt 1;
BA_ "CANzero_SDO_AccessIfOperational" SG_ 1473 SENSOR_OD_CAN1_TxErrCnt 1;
BA_ "CANzero_SDO_AccessType" SG_ 1473 SENSOR_OD_BuildTime 1;
BA_ "CANzero_SDO_AccessIfOperational" SG_ 1473 SENSOR_OD_BuildTime 1;
BA_ "CANzero_SDO_AccessType" SG_ 1473 SENSOR_OD_BuildDate 1;
BA_ "CANzero_SDO_AccessIfOperational" SG_ 1473 SENSOR_OD_BuildDate 1;
BA_ "CANzero_SDO_AccessType" SG_ 1473 SENSOR_OD_ChipUID2 1;
BA_ "CANzero_SDO_AccessIfOperational" SG_ 1473 SENSOR_OD_ChipUID2 1;
BA_ "CANzero_SDO_AccessType" SG_ 1473 SENSOR_OD_ChipUID1 1;
BA_ "CANzero_SDO_AccessIfOperational" SG_ 1473 SENSOR_OD_ChipUID1 1;
BA_ "CANzero_SDO_AccessType" SG_ 1473 SENSOR_OD_SdcOut 1;
BA_ "CANzero_SDO_AccessIfOperational" SG_ 1473 SENSOR_OD_SdcOut 1;
BA_ "CANzero_SDO_AccessType" SG_ 1473 SENSOR_OD_SdcIn 1;
BA_ "CANzero_SDO_AccessIfOperational" SG_ 1473 SENSOR_OD_SdcIn 1;
BA_ "CANzero_SDO_AccessType" SG_ 1473 SENSOR_OD_runtime 1;
BA_ "CANzero_SDO_AccessIfOperational" SG_ 1473 SENSOR_OD_runtime 1;
BA_ "CANzero_SDO_AccessType" SG_ 1473 SENSOR_OD_InputVoltage 1;
BA_ "CANzero_SDO_AccessIfOperational" SG_ 1473 SENSOR_OD_InputVoltage 1;
BA_ "CANzero_SDO_AccessType" SG_ 1473 SENSOR_OD_BoardTemp 1;
BA_ "CANzero_SDO_AccessIfOperational" SG_ 1473 SENSOR_OD_BoardTemp 1;
BA_ "GenSigStartValue" SG_ 1473 SENSOR_OD_BoardTemp 3000.0;
BA_ "CANzero_SDO_AccessType" SG_ 1473 SENSOR_OD_MemFree 1;
BA_ "CANzero_SDO_AccessIfOperational" SG_ 1473 SENSOR_OD_MemFree 1;
BA_ "CANzero_SDO_AccessType" SG_ 1473 SENSOR_OD_CpuUsage 1;
BA_ "CANzero_SDO_AccessIfOperational" SG_ 1473 SENSOR_OD_CpuUsage 1;
BA_ "CANzero_SDO_AccessIfOperational" SG_ 1473 SENSOR_OD_OdEntrySendInterval 1;
BA_ "GenSigStartValue" SG_ 1473 SENSOR_OD_OdEntrySendInterval 50.0;
BA_ "CANzero_SDO_Default" SG_ 1473 SENSOR_OD_OdEntrySendInterval 50;
BA_ "CANzero_SDO_AccessIfOperational" SG_ 1473 SENSOR_OD_SendOdOnBootup 1;
BA_ "CANzero_SDO_AccessIfOperational" SG_ 1473 SENSOR_OD_HeartbeatInterval 1;
BA_ "GenSigStartValue" SG_ 1473 SENSOR_OD_HeartbeatInterval 250.0;
BA_ "CANzero_SDO_Default" SG_ 1473 SENSOR_OD_HeartbeatInterval 250;
BA_ "CANzero_SDO_AccessType" SG_ 1473 SENSOR_OD_DbcVersion 1;
BA_ "CANzero_SDO_AccessIfOperational" SG_ 1473 SENSOR_OD_DbcVersion 1;
BA_ "CANzero_SDO_AccessType" SG_ 1473 SENSOR_OD_StackVersion 1;
BA_ "CANzero_SDO_AccessIfOperational" SG_ 1473 SENSOR_OD_StackVersion 1;
BA_ "CANzero_SDO_AccessType" SG_ 1473 SENSOR_OD_ProtocolVersion 1;
BA_ "CANzero_SDO_AccessIfOperational" SG_ 1473 SENSOR_OD_ProtocolVersion 1;
BA_ "GenSigStartValue" SG_ 1473 SENSOR_OD_ProtocolVersion 1.0;
BA_ "CANzero_SDO_Default" SG_ 1473 SENSOR_OD_ProtocolVersion 1;
BA_ "CANzero_SDO_AccessType" SG_ 1473 SENSOR_OD_NodeStatus 1;
BA_ "CANzero_SDO_AccessIfOperational" SG_ 1473 SENSOR_OD_NodeStatus 1;
BA_ "CANzero_SDO_AccessType" SG_ 1473 SENSOR_OD_NodeID 1;
BA_ "CANzero_SDO_AccessIfOperational" SG_ 1473 SENSOR_OD_NodeID 1;
BA_ "CANzero_SDO_AccessIfOperational" SG_ 1410 PDU_OD_CoolingPumpEnabled 1;
BA_ "GenSigStartValue" SG_ 1410 PDU_OD_CoolingPumpEnabled 1.0;
BA_ "CANzero_SDO_Default" SG_ 1410 PDU_OD_CoolingPumpEnabled 1;
BA_ "CANzero_SDO_AccessIfOperational" SG_ 1410 PDU_OD_LedCommands 1;
BA_ "GenSigStartValue" SG_ 1410 PDU_OD_LedCommands 1.0;
BA_ "CANzero_SDO_Default" SG_ 1410 PDU_OD_LedCommands 1;
BA_ "CANzero_SDO_AccessIfOperational" SG_ 1410 PDU_OD_projectXXEnabled 1;
BA_ "GenSigStartValue" SG_ 1410 PDU_OD_projectXXEnabled 1.0;
BA_ "CANzero_SDO_Default" SG_ 1410 PDU_OD_projectXXEnabled 1;
BA_ "CANzero_SDO_AccessIfOperational" SG_ 1410 PDU_OD_watchdogTimeout 1;
BA_ "GenSigStartValue" SG_ 1410 PDU_OD_watchdogTimeout 25.0;
BA_ "CANzero_SDO_Default" SG_ 1410 PDU_OD_watchdogTimeout 25;
BA_ "CANzero_SDO_AccessIfOperational" SG_ 1410 PDU_OD_statusSendInterval 1;
BA_ "GenSigStartValue" SG_ 1410 PDU_OD_statusSendInterval 20.0;
BA_ "CANzero_SDO_Default" SG_ 1410 PDU_OD_statusSendInterval 20;
BA_ "CANzero_SDO_AccessIfOperational" SG_ 1410 PDU_OD_currentReadInterval 1;
BA_ "GenSigStartValue" SG_ 1410 PDU_OD_currentReadInterval 100.0;
BA_ "CANzero_SDO_Default" SG_ 1410 PDU_OD_currentReadInterval 100;
BA_ "CANzero_SDO_AccessIfOperational" SG_ 1410 PDU_OD_batteryOvercurrent 1;
BA_ "GenSigStartValue" SG_ 1410 PDU_OD_batteryOvercurrent 1500.0;
BA_ "CANzero_SDO_Default" SG_ 1410 PDU_OD_batteryOvercurrent 15;
BA_ "CANzero_SDO_AccessIfOperational" SG_ 1410 PDU_OD_overTempCritical 1;
BA_ "GenSigStartValue" SG_ 1410 PDU_OD_overTempCritical 700.0;
BA_ "CANzero_SDO_Default" SG_ 1410 PDU_OD_overTempCritical 70;
BA_ "CANzero_SDO_AccessIfOperational" SG_ 1410 PDU_OD_overTempWarn 1;
BA_ "GenSigStartValue" SG_ 1410 PDU_OD_overTempWarn 400.0;
BA_ "CANzero_SDO_Default" SG_ 1410 PDU_OD_overTempWarn 40;
BA_ "CANzero_SDO_AccessIfOperational" SG_ 1410 PDU_OD_batterVoltageCritical 1;
BA_ "GenSigStartValue" SG_ 1410 PDU_OD_batterVoltageCritical 2100.0;
BA_ "CANzero_SDO_Default" SG_ 1410 PDU_OD_batterVoltageCritical 21.0;
BA_ "CANzero_SDO_AccessIfOperational" SG_ 1410 PDU_OD_batterVoltageLow 1;
BA_ "GenSigStartValue" SG_ 1410 PDU_OD_batterVoltageLow 2220.0;
BA_ "CANzero_SDO_Default" SG_ 1410 PDU_OD_batterVoltageLow 22.2;
BA_ "CANzero_SDO_Group" SG_ 1410 PDU_OD_CAN2_DelayedTxMessages "CAN";
BA_ "CANzero_SDO_AccessType" SG_ 1410 PDU_OD_CAN2_DelayedTxMessages 1;
BA_ "CANzero_SDO_AccessIfOperational" SG_ 1410 PDU_OD_CAN2_DelayedTxMessages 1;
BA_ "CANzero_SDO_Group" SG_ 1410 PDU_OD_CAN2_ErrorStatus "CAN";
BA_ "CANzero_SDO_AccessType" SG_ 1410 PDU_OD_CAN2_ErrorStatus 1;
BA_ "CANzero_SDO_AccessIfOperational" SG_ 1410 PDU_OD_CAN2_ErrorStatus 1;
BA_ "CANzero_SDO_Group" SG_ 1410 PDU_OD_CAN2_DiscardedTxMessages "CAN";
BA_ "CANzero_SDO_AccessType" SG_ 1410 PDU_OD_CAN2_DiscardedTxMessages 1;
BA_ "CANzero_SDO_AccessIfOperational" SG_ 1410 PDU_OD_CAN2_DiscardedTxMessages 1;
BA_ "CANzero_SDO_Group" SG_ 1410 PDU_OD_CAN2_Status "CAN";
BA_ "CANzero_SDO_AccessType" SG_ 1410 PDU_OD_CAN2_Status 1;
BA_ "CANzero_SDO_AccessIfOperational" SG_ 1410 PDU_OD_CAN2_Status 1;
BA_ "CANzero_SDO_Group" SG_ 1410 PDU_OD_CAN2_Baudrate "CAN";
BA_ "CANzero_SDO_AccessIfOperational" SG_ 1410 PDU_OD_CAN2_Baudrate 1;
BA_ "GenSigStartValue" SG_ 1410 PDU_OD_CAN2_Baudrate 1000.0;
BA_ "CANzero_SDO_Default" SG_ 1410 PDU_OD_CAN2_Baudrate 1000;
BA_ "CANzero_SDO_Group" SG_ 1410 PDU_OD_CAN2_autoErrorReset "CAN";
BA_ "CANzero_SDO_AccessIfOperational" SG_ 1410 PDU_OD_CAN2_autoErrorReset 1;
BA_ "GenSigStartValue" SG_ 1410 PDU_OD_CAN2_autoErrorReset 1.0;
BA_ "CANzero_SDO_Default" SG_ 1410 PDU_OD_CAN2_autoErrorReset 1;
BA_ "CANzero_SDO_Group" SG_ 1410 PDU_OD_CAN2_lastErrorCode "CAN";
BA_ "CANzero_SDO_AccessType" SG_ 1410 PDU_OD_CAN2_lastErrorCode 1;
BA_ "CANzero_SDO_AccessIfOperational" SG_ 1410 PDU_OD_CAN2_lastErrorCode 1;
BA_ "CANzero_SDO_Group" SG_ 1410 PDU_OD_CAN2_RxErrCnt "CAN";
BA_ "CANzero_SDO_AccessType" SG_ 1410 PDU_OD_CAN2_RxErrCnt 1;
BA_ "CANzero_SDO_AccessIfOperational" SG_ 1410 PDU_OD_CAN2_RxErrCnt 1;
BA_ "CANzero_SDO_Group" SG_ 1410 PDU_OD_CAN2_TxErrCnt "CAN";
BA_ "CANzero_SDO_AccessType" SG_ 1410 PDU_OD_CAN2_TxErrCnt 1;
BA_ "CANzero_SDO_AccessIfOperational" SG_ 1410 PDU_OD_CAN2_TxErrCnt 1;
BA_ "CANzero_SDO_Group" SG_ 1410 PDU_OD_CAN1_DelayedTxMessages "CAN";
BA_ "CANzero_SDO_AccessType" SG_ 1410 PDU_OD_CAN1_DelayedTxMessages 1;
BA_ "CANzero_SDO_AccessIfOperational" SG_ 1410 PDU_OD_CAN1_DelayedTxMessages 1;
BA_ "CANzero_SDO_Group" SG_ 1410 PDU_OD_CAN1_ErrorStatus "CAN";
BA_ "CANzero_SDO_AccessType" SG_ 1410 PDU_OD_CAN1_ErrorStatus 1;
BA_ "CANzero_SDO_AccessIfOperational" SG_ 1410 PDU_OD_CAN1_ErrorStatus 1;
BA_ "CANzero_SDO_Group" SG_ 1410 PDU_OD_CAN1_DiscardedTxMessages "CAN";
BA_ "CANzero_SDO_AccessType" SG_ 1410 PDU_OD_CAN1_DiscardedTxMessages 1;
BA_ "CANzero_SDO_AccessIfOperational" SG_ 1410 PDU_OD_CAN1_DiscardedTxMessages 1;
BA_ "CANzero_SDO_Group" SG_ 1410 PDU_OD_CAN1_Status "CAN";
BA_ "CANzero_SDO_AccessType" SG_ 1410 PDU_OD_CAN1_Status 1;
BA_ "CANzero_SDO_AccessIfOperational" SG_ 1410 PDU_OD_CAN1_Status 1;
BA_ "CANzero_SDO_Group" SG_ 1410 PDU_OD_CAN1_Baudrate "CAN";
BA_ "CANzero_SDO_AccessIfOperational" SG_ 1410 PDU_OD_CAN1_Baudrate 1;
BA_ "GenSigStartValue" SG_ 1410 PDU_OD_CAN1_Baudrate 1000.0;
BA_ "CANzero_SDO_Default" SG_ 1410 PDU_OD_CAN1_Baudrate 1000;
BA_ "CANzero_SDO_Group" SG_ 1410 PDU_OD_CAN1_autoErrorReset "CAN";
BA_ "CANzero_SDO_AccessIfOperational" SG_ 1410 PDU_OD_CAN1_autoErrorReset 1;
BA_ "GenSigStartValue" SG_ 1410 PDU_OD_CAN1_autoErrorReset 1.0;
BA_ "CANzero_SDO_Default" SG_ 1410 PDU_OD_CAN1_autoErrorReset 1;
BA_ "CANzero_SDO_Group" SG_ 1410 PDU_OD_CAN1_lastErrorCode "CAN";
BA_ "CANzero_SDO_AccessType" SG_ 1410 PDU_OD_CAN1_lastErrorCode 1;
BA_ "CANzero_SDO_AccessIfOperational" SG_ 1410 PDU_OD_CAN1_lastErrorCode 1;
BA_ "CANzero_SDO_Group" SG_ 1410 PDU_OD_CAN1_RxErrCnt "CAN";
BA_ "CANzero_SDO_AccessType" SG_ 1410 PDU_OD_CAN1_RxErrCnt 1;
BA_ "CANzero_SDO_AccessIfOperational" SG_ 1410 PDU_OD_CAN1_RxErrCnt 1;
BA_ "CANzero_SDO_Group" SG_ 1410 PDU_OD_CAN1_TxErrCnt "CAN";
BA_ "CANzero_SDO_AccessType" SG_ 1410 PDU_OD_CAN1_TxErrCnt 1;
BA_ "CANzero_SDO_AccessIfOperational" SG_ 1410 PDU_OD_CAN1_TxErrCnt 1;
BA_ "CANzero_SDO_AccessType" SG_ 1410 PDU_OD_BuildTime 1;
BA_ "CANzero_SDO_AccessIfOperational" SG_ 1410 PDU_OD_BuildTime 1;
BA_ "CANzero_SDO_AccessType" SG_ 1410 PDU_OD_BuildDate 1;
BA_ "CANzero_SDO_AccessIfOperational" SG_ 1410 PDU_OD_BuildDate 1;
BA_ "CANzero_SDO_AccessType" SG_ 1410 PDU_OD_ChipUID2 1;
BA_ "CANzero_SDO_AccessIfOperational" SG_ 1410 PDU_OD_ChipUID2 1;
BA_ "CANzero_SDO_AccessType" SG_ 1410 PDU_OD_ChipUID1 1;
BA_ "CANzero_SDO_AccessIfOperational" SG_ 1410 PDU_OD_ChipUID1 1;
BA_ "CANzero_SDO_AccessType" SG_ 1410 PDU_OD_SdcOut 1;
BA_ "CANzero_SDO_AccessIfOperational" SG_ 1410 PDU_OD_SdcOut 1;
BA_ "CANzero_SDO_AccessType" SG_ 1410 PDU_OD_SdcIn 1;
BA_ "CANzero_SDO_AccessIfOperational" SG_ 1410 PDU_OD_SdcIn 1;
BA_ "CANzero_SDO_AccessType" SG_ 1410 PDU_OD_runtime 1;
BA_ "CANzero_SDO_AccessIfOperational" SG_ 1410 PDU_OD_runtime 1;
BA_ "CANzero_SDO_AccessType" SG_ 1410 PDU_OD_InputVoltage 1;
BA_ "CANzero_SDO_AccessIfOperational" SG_ 1410 PDU_OD_InputVoltage 1;
BA_ "CANzero_SDO_AccessType" SG_ 1410 PDU_OD_BoardTemp 1;
BA_ "CANzero_SDO_AccessIfOperational" SG_ 1410 PDU_OD_BoardTemp 1;
BA_ "GenSigStartValue" SG_ 1410 PDU_OD_BoardTemp 3000.0;
BA_ "CANzero_SDO_AccessType" SG_ 1410 PDU_OD_MemFree 1;
BA_ "CANzero_SDO_AccessIfOperational" SG_ 1410 PDU_OD_MemFree 1;
BA_ "CANzero_SDO_AccessType" SG_ 1410 PDU_OD_CpuUsage 1;
BA_ "CANzero_SDO_AccessIfOperational" SG_ 1410 PDU_OD_CpuUsage 1;
BA_ "CANzero_SDO_AccessIfOperational" SG_ 1410 PDU_OD_OdEntrySendInterval 1;
BA_ "GenSigStartValue" SG_ 1410 PDU_OD_OdEntrySendInterval 50.0;
BA_ "CANzero_SDO_Default" SG_ 1410 PDU_OD_OdEntrySendInterval 50;
BA_ "CANzero_SDO_AccessIfOperational" SG_ 1410 PDU_OD_SendOdOnBootup 1;
BA_ "CANzero_SDO_AccessIfOperational" SG_ 1410 PDU_OD_HeartbeatInterval 1;
BA_ "GenSigStartValue" SG_ 1410 PDU_OD_HeartbeatInterval 250.0;
BA_ "CANzero_SDO_Default" SG_ 1410 PDU_OD_HeartbeatInterval 250;
BA_ "CANzero_SDO_AccessType" SG_ 1410 PDU_OD_DbcVersion 1;
BA_ "CANzero_SDO_AccessIfOperational" SG_ 1410 PDU_OD_DbcVersion 1;
BA_ "CANzero_SDO_AccessType" SG_ 1410 PDU_OD_StackVersion 1;
BA_ "CANzero_SDO_AccessIfOperational" SG_ 1410 PDU_OD_StackVersion 1;
BA_ "CANzero_SDO_AccessType" SG_ 1410 PDU_OD_ProtocolVersion 1;
BA_ "CANzero_SDO_AccessIfOperational" SG_ 1410 PDU_OD_ProtocolVersion 1;
BA_ "GenSigStartValue" SG_ 1410 PDU_OD_ProtocolVersion 1.0;
BA_ "CANzero_SDO_Default" SG_ 1410 PDU_OD_ProtocolVersion 1;
BA_ "CANzero_SDO_AccessType" SG_ 1410 PDU_OD_NodeStatus 1;
BA_ "CANzero_SDO_AccessIfOperational" SG_ 1410 PDU_OD_NodeStatus 1;
BA_ "CANzero_SDO_AccessType" SG_ 1410 PDU_OD_NodeID 1;
BA_ "CANzero_SDO_AccessIfOperational" SG_ 1410 PDU_OD_NodeID 1;
BA_ "CANzero_SDO_AccessIfOperational" SG_ 1474 PDU_OD_CoolingPumpEnabled 1;
BA_ "GenSigStartValue" SG_ 1474 PDU_OD_CoolingPumpEnabled 1.0;
BA_ "CANzero_SDO_Default" SG_ 1474 PDU_OD_CoolingPumpEnabled 1;
BA_ "CANzero_SDO_AccessIfOperational" SG_ 1474 PDU_OD_LedCommands 1;
BA_ "GenSigStartValue" SG_ 1474 PDU_OD_LedCommands 1.0;
BA_ "CANzero_SDO_Default" SG_ 1474 PDU_OD_LedCommands 1;
BA_ "CANzero_SDO_AccessIfOperational" SG_ 1474 PDU_OD_projectXXEnabled 1;
BA_ "GenSigStartValue" SG_ 1474 PDU_OD_projectXXEnabled 1.0;
BA_ "CANzero_SDO_Default" SG_ 1474 PDU_OD_projectXXEnabled 1;
BA_ "CANzero_SDO_AccessIfOperational" SG_ 1474 PDU_OD_watchdogTimeout 1;
BA_ "GenSigStartValue" SG_ 1474 PDU_OD_watchdogTimeout 25.0;
BA_ "CANzero_SDO_Default" SG_ 1474 PDU_OD_watchdogTimeout 25;
BA_ "CANzero_SDO_AccessIfOperational" SG_ 1474 PDU_OD_statusSendInterval 1;
BA_ "GenSigStartValue" SG_ 1474 PDU_OD_statusSendInterval 20.0;
BA_ "CANzero_SDO_Default" SG_ 1474 PDU_OD_statusSendInterval 20;
BA_ "CANzero_SDO_AccessIfOperational" SG_ 1474 PDU_OD_currentReadInterval 1;
BA_ "GenSigStartValue" SG_ 1474 PDU_OD_currentReadInterval 100.0;
BA_ "CANzero_SDO_Default" SG_ 1474 PDU_OD_currentReadInterval 100;
BA_ "CANzero_SDO_AccessIfOperational" SG_ 1474 PDU_OD_batteryOvercurrent 1;
BA_ "GenSigStartValue" SG_ 1474 PDU_OD_batteryOvercurrent 1500.0;
BA_ "CANzero_SDO_Default" SG_ 1474 PDU_OD_batteryOvercurrent 15;
BA_ "CANzero_SDO_AccessIfOperational" SG_ 1474 PDU_OD_overTempCritical 1;
BA_ "GenSigStartValue" SG_ 1474 PDU_OD_overTempCritical 700.0;
BA_ "CANzero_SDO_Default" SG_ 1474 PDU_OD_overTempCritical 70;
BA_ "CANzero_SDO_AccessIfOperational" SG_ 1474 PDU_OD_overTempWarn 1;
BA_ "GenSigStartValue" SG_ 1474 PDU_OD_overTempWarn 400.0;
BA_ "CANzero_SDO_Default" SG_ 1474 PDU_OD_overTempWarn 40;
BA_ "CANzero_SDO_AccessIfOperational" SG_ 1474 PDU_OD_batterVoltageCritical 1;
BA_ "GenSigStartValue" SG_ 1474 PDU_OD_batterVoltageCritical 2100.0;
BA_ "CANzero_SDO_Default" SG_ 1474 PDU_OD_batterVoltageCritical 21.0;
BA_ "CANzero_SDO_AccessIfOperational" SG_ 1474 PDU_OD_batterVoltageLow 1;
BA_ "GenSigStartValue" SG_ 1474 PDU_OD_batterVoltageLow 2220.0;
BA_ "CANzero_SDO_Default" SG_ 1474 PDU_OD_batterVoltageLow 22.2;
BA_ "CANzero_SDO_Group" SG_ 1474 PDU_OD_CAN2_DelayedTxMessages "CAN";
BA_ "CANzero_SDO_AccessType" SG_ 1474 PDU_OD_CAN2_DelayedTxMessages 1;
BA_ "CANzero_SDO_AccessIfOperational" SG_ 1474 PDU_OD_CAN2_DelayedTxMessages 1;
BA_ "CANzero_SDO_Group" SG_ 1474 PDU_OD_CAN2_ErrorStatus "CAN";
BA_ "CANzero_SDO_AccessType" SG_ 1474 PDU_OD_CAN2_ErrorStatus 1;
BA_ "CANzero_SDO_AccessIfOperational" SG_ 1474 PDU_OD_CAN2_ErrorStatus 1;
BA_ "CANzero_SDO_Group" SG_ 1474 PDU_OD_CAN2_DiscardedTxMessages "CAN";
BA_ "CANzero_SDO_AccessType" SG_ 1474 PDU_OD_CAN2_DiscardedTxMessages 1;
BA_ "CANzero_SDO_AccessIfOperational" SG_ 1474 PDU_OD_CAN2_DiscardedTxMessages 1;
BA_ "CANzero_SDO_Group" SG_ 1474 PDU_OD_CAN2_Status "CAN";
BA_ "CANzero_SDO_AccessType" SG_ 1474 PDU_OD_CAN2_Status 1;
BA_ "CANzero_SDO_AccessIfOperational" SG_ 1474 PDU_OD_CAN2_Status 1;
BA_ "CANzero_SDO_Group" SG_ 1474 PDU_OD_CAN2_Baudrate "CAN";
BA_ "CANzero_SDO_AccessIfOperational" SG_ 1474 PDU_OD_CAN2_Baudrate 1;
BA_ "GenSigStartValue" SG_ 1474 PDU_OD_CAN2_Baudrate 1000.0;
BA_ "CANzero_SDO_Default" SG_ 1474 PDU_OD_CAN2_Baudrate 1000;
BA_ "CANzero_SDO_Group" SG_ 1474 PDU_OD_CAN2_autoErrorReset "CAN";
BA_ "CANzero_SDO_AccessIfOperational" SG_ 1474 PDU_OD_CAN2_autoErrorReset 1;
BA_ "GenSigStartValue" SG_ 1474 PDU_OD_CAN2_autoErrorReset 1.0;
BA_ "CANzero_SDO_Default" SG_ 1474 PDU_OD_CAN2_autoErrorReset 1;
BA_ "CANzero_SDO_Group" SG_ 1474 PDU_OD_CAN2_lastErrorCode "CAN";
BA_ "CANzero_SDO_AccessType" SG_ 1474 PDU_OD_CAN2_lastErrorCode 1;
BA_ "CANzero_SDO_AccessIfOperational" SG_ 1474 PDU_OD_CAN2_lastErrorCode 1;
BA_ "CANzero_SDO_Group" SG_ 1474 PDU_OD_CAN2_RxErrCnt "CAN";
BA_ "CANzero_SDO_AccessType" SG_ 1474 PDU_OD_CAN2_RxErrCnt 1;
BA_ "CANzero_SDO_AccessIfOperational" SG_ 1474 PDU_OD_CAN2_RxErrCnt 1;
BA_ "CANzero_SDO_Group" SG_ 1474 PDU_OD_CAN2_TxErrCnt "CAN";
BA_ "CANzero_SDO_AccessType" SG_ 1474 PDU_OD_CAN2_TxErrCnt 1;
BA_ "CANzero_SDO_AccessIfOperational" SG_ 1474 PDU_OD_CAN2_TxErrCnt 1;
BA_ "CANzero_SDO_Group" SG_ 1474 PDU_OD_CAN1_DelayedTxMessages "CAN";
BA_ "CANzero_SDO_AccessType" SG_ 1474 PDU_OD_CAN1_DelayedTxMessages 1;
BA_ "CANzero_SDO_AccessIfOperational" SG_ 1474 PDU_OD_CAN1_DelayedTxMessages 1;
BA_ "CANzero_SDO_Group" SG_ 1474 PDU_OD_CAN1_ErrorStatus "CAN";
BA_ "CANzero_SDO_AccessType" SG_ 1474 PDU_OD_CAN1_ErrorStatus 1;
BA_ "CANzero_SDO_AccessIfOperational" SG_ 1474 PDU_OD_CAN1_ErrorStatus 1;
BA_ "CANzero_SDO_Group" SG_ 1474 PDU_OD_CAN1_DiscardedTxMessages "CAN";
BA_ "CANzero_SDO_AccessType" SG_ 1474 PDU_OD_CAN1_DiscardedTxMessages 1;
BA_ "CANzero_SDO_AccessIfOperational" SG_ 1474 PDU_OD_CAN1_DiscardedTxMessages 1;
BA_ "CANzero_SDO_Group" SG_ 1474 PDU_OD_CAN1_Status "CAN";
BA_ "CANzero_SDO_AccessType" SG_ 1474 PDU_OD_CAN1_Status 1;
BA_ "CANzero_SDO_AccessIfOperational" SG_ 1474 PDU_OD_CAN1_Status 1;
BA_ "CANzero_SDO_Group" SG_ 1474 PDU_OD_CAN1_Baudrate "CAN";
BA_ "CANzero_SDO_AccessIfOperational" SG_ 1474 PDU_OD_CAN1_Baudrate 1;
BA_ "GenSigStartValue" SG_ 1474 PDU_OD_CAN1_Baudrate 1000.0;
BA_ "CANzero_SDO_Default" SG_ 1474 PDU_OD_CAN1_Baudrate 1000;
BA_ "CANzero_SDO_Group" SG_ 1474 PDU_OD_CAN1_autoErrorReset "CAN";
BA_ "CANzero_SDO_AccessIfOperational" SG_ 1474 PDU_OD_CAN1_autoErrorReset 1;
BA_ "GenSigStartValue" SG_ 1474 PDU_OD_CAN1_autoErrorReset 1.0;
BA_ "CANzero_SDO_Default" SG_ 1474 PDU_OD_CAN1_autoErrorReset 1;
BA_ "CANzero_SDO_Group" SG_ 1474 PDU_OD_CAN1_lastErrorCode "CAN";
BA_ "CANzero_SDO_AccessType" SG_ 1474 PDU_OD_CAN1_lastErrorCode 1;
BA_ "CANzero_SDO_AccessIfOperational" SG_ 1474 PDU_OD_CAN1_lastErrorCode 1;
BA_ "CANzero_SDO_Group" SG_ 1474 PDU_OD_CAN1_RxErrCnt "CAN";
BA_ "CANzero_SDO_AccessType" SG_ 1474 PDU_OD_CAN1_RxErrCnt 1;
BA_ "CANzero_SDO_AccessIfOperational" SG_ 1474 PDU_OD_CAN1_RxErrCnt 1;
BA_ "CANzero_SDO_Group" SG_ 1474 PDU_OD_CAN1_TxErrCnt "CAN";
BA_ "CANzero_SDO_AccessType" SG_ 1474 PDU_OD_CAN1_TxErrCnt 1;
BA_ "CANzero_SDO_AccessIfOperational" SG_ 1474 PDU_OD_CAN1_TxErrCnt 1;
BA_ "CANzero_SDO_AccessType" SG_ 1474 PDU_OD_BuildTime 1;
BA_ "CANzero_SDO_AccessIfOperational" SG_ 1474 PDU_OD_BuildTime 1;
BA_ "CANzero_SDO_AccessType" SG_ 1474 PDU_OD_BuildDate 1;
BA_ "CANzero_SDO_AccessIfOperational" SG_ 1474 PDU_OD_BuildDate 1;
BA_ "CANzero_SDO_AccessType" SG_ 1474 PDU_OD_ChipUID2 1;
BA_ "CANzero_SDO_AccessIfOperational" SG_ 1474 PDU_OD_ChipUID2 1;
BA_ "CANzero_SDO_AccessType" SG_ 1474 PDU_OD_ChipUID1 1;
BA_ "CANzero_SDO_AccessIfOperational" SG_ 1474 PDU_OD_ChipUID1 1;
BA_ "CANzero_SDO_AccessType" SG_ 1474 PDU_OD_SdcOut 1;
BA_ "CANzero_SDO_AccessIfOperational" SG_ 1474 PDU_OD_SdcOut 1;
BA_ "CANzero_SDO_AccessType" SG_ 1474 PDU_OD_SdcIn 1;
BA_ "CANzero_SDO_AccessIfOperational" SG_ 1474 PDU_OD_SdcIn 1;
BA_ "CANzero_SDO_AccessType" SG_ 1474 PDU_OD_runtime 1;
BA_ "CANzero_SDO_AccessIfOperational" SG_ 1474 PDU_OD_runtime 1;
BA_ "CANzero_SDO_AccessType" SG_ 1474 PDU_OD_InputVoltage 1;
BA_ "CANzero_SDO_AccessIfOperational" SG_ 1474 PDU_OD_InputVoltage 1;
BA_ "CANzero_SDO_AccessType" SG_ 1474 PDU_OD_BoardTemp 1;
BA_ "CANzero_SDO_AccessIfOperational" SG_ 1474 PDU_OD_BoardTemp 1;
BA_ "GenSigStartValue" SG_ 1474 PDU_OD_BoardTemp 3000.0;
BA_ "CANzero_SDO_AccessType" SG_ 1474 PDU_OD_MemFree 1;
BA_ "CANzero_SDO_AccessIfOperational" SG_ 1474 PDU_OD_MemFree 1;
BA_ "CANzero_SDO_AccessType" SG_ 1474 PDU_OD_CpuUsage 1;
BA_ "CANzero_SDO_AccessIfOperational" SG_ 1474 PDU_OD_CpuUsage 1;
BA_ "CANzero_SDO_AccessIfOperational" SG_ 1474 PDU_OD_OdEntrySendInterval 1;
BA_ "GenSigStartValue" SG_ 1474 PDU_OD_OdEntrySendInterval 50.0;
BA_ "CANzero_SDO_Default" SG_ 1474 PDU_OD_OdEntrySendInterval 50;
BA_ "CANzero_SDO_AccessIfOperational" SG_ 1474 PDU_OD_SendOdOnBootup 1;
BA_ "CANzero_SDO_AccessIfOperational" SG_ 1474 PDU_OD_HeartbeatInterval 1;
BA_ "GenSigStartValue" SG_ 1474 PDU_OD_HeartbeatInterval 250.0;
BA_ "CANzero_SDO_Default" SG_ 1474 PDU_OD_HeartbeatInterval 250;
BA_ "CANzero_SDO_AccessType" SG_ 1474 PDU_OD_DbcVersion 1;
BA_ "CANzero_SDO_AccessIfOperational" SG_ 1474 PDU_OD_DbcVersion 1;
BA_ "CANzero_SDO_AccessType" SG_ 1474 PDU_OD_StackVersion 1;
BA_ "CANzero_SDO_AccessIfOperational" SG_ 1474 PDU_OD_StackVersion 1;
BA_ "CANzero_SDO_AccessType" SG_ 1474 PDU_OD_ProtocolVersion 1;
BA_ "CANzero_SDO_AccessIfOperational" SG_ 1474 PDU_OD_ProtocolVersion 1;
BA_ "GenSigStartValue" SG_ 1474 PDU_OD_ProtocolVersion 1.0;
BA_ "CANzero_SDO_Default" SG_ 1474 PDU_OD_ProtocolVersion 1;
BA_ "CANzero_SDO_AccessType" SG_ 1474 PDU_OD_NodeStatus 1;
BA_ "CANzero_SDO_AccessIfOperational" SG_ 1474 PDU_OD_NodeStatus 1;
BA_ "CANzero_SDO_AccessType" SG_ 1474 PDU_OD_NodeID 1;
BA_ "CANzero_SDO_AccessIfOperational" SG_ 1474 PDU_OD_NodeID 1;
BA_ "CANzero_SDO_Group" SG_ 1411 CLU_OD_CAN2_DelayedTxMessages "CAN";
BA_ "CANzero_SDO_AccessType" SG_ 1411 CLU_OD_CAN2_DelayedTxMessages 1;
BA_ "CANzero_SDO_AccessIfOperational" SG_ 1411 CLU_OD_CAN2_DelayedTxMessages 1;
BA_ "CANzero_SDO_Group" SG_ 1411 CLU_OD_CAN2_ErrorStatus "CAN";
BA_ "CANzero_SDO_AccessType" SG_ 1411 CLU_OD_CAN2_ErrorStatus 1;
BA_ "CANzero_SDO_AccessIfOperational" SG_ 1411 CLU_OD_CAN2_ErrorStatus 1;
BA_ "CANzero_SDO_Group" SG_ 1411 CLU_OD_CAN2_DiscardedTxMessages "CAN";
BA_ "CANzero_SDO_AccessType" SG_ 1411 CLU_OD_CAN2_DiscardedTxMessages 1;
BA_ "CANzero_SDO_AccessIfOperational" SG_ 1411 CLU_OD_CAN2_DiscardedTxMessages 1;
BA_ "CANzero_SDO_Group" SG_ 1411 CLU_OD_CAN2_Status "CAN";
BA_ "CANzero_SDO_AccessType" SG_ 1411 CLU_OD_CAN2_Status 1;
BA_ "CANzero_SDO_AccessIfOperational" SG_ 1411 CLU_OD_CAN2_Status 1;
BA_ "CANzero_SDO_Group" SG_ 1411 CLU_OD_CAN2_Baudrate "CAN";
BA_ "CANzero_SDO_AccessIfOperational" SG_ 1411 CLU_OD_CAN2_Baudrate 1;
BA_ "GenSigStartValue" SG_ 1411 CLU_OD_CAN2_Baudrate 1000.0;
BA_ "CANzero_SDO_Default" SG_ 1411 CLU_OD_CAN2_Baudrate 1000;
BA_ "CANzero_SDO_Group" SG_ 1411 CLU_OD_CAN2_autoErrorReset "CAN";
BA_ "CANzero_SDO_AccessIfOperational" SG_ 1411 CLU_OD_CAN2_autoErrorReset 1;
BA_ "GenSigStartValue" SG_ 1411 CLU_OD_CAN2_autoErrorReset 1.0;
BA_ "CANzero_SDO_Default" SG_ 1411 CLU_OD_CAN2_autoErrorReset 1;
BA_ "CANzero_SDO_Group" SG_ 1411 CLU_OD_CAN2_lastErrorCode "CAN";
BA_ "CANzero_SDO_AccessType" SG_ 1411 CLU_OD_CAN2_lastErrorCode 1;
BA_ "CANzero_SDO_AccessIfOperational" SG_ 1411 CLU_OD_CAN2_lastErrorCode 1;
BA_ "CANzero_SDO_Group" SG_ 1411 CLU_OD_CAN2_RxErrCnt "CAN";
BA_ "CANzero_SDO_AccessType" SG_ 1411 CLU_OD_CAN2_RxErrCnt 1;
BA_ "CANzero_SDO_AccessIfOperational" SG_ 1411 CLU_OD_CAN2_RxErrCnt 1;
BA_ "CANzero_SDO_Group" SG_ 1411 CLU_OD_CAN2_TxErrCnt "CAN";
BA_ "CANzero_SDO_AccessType" SG_ 1411 CLU_OD_CAN2_TxErrCnt 1;
BA_ "CANzero_SDO_AccessIfOperational" SG_ 1411 CLU_OD_CAN2_TxErrCnt 1;
BA_ "CANzero_SDO_Group" SG_ 1411 CLU_OD_CAN1_DelayedTxMessages "CAN";
BA_ "CANzero_SDO_AccessType" SG_ 1411 CLU_OD_CAN1_DelayedTxMessages 1;
BA_ "CANzero_SDO_AccessIfOperational" SG_ 1411 CLU_OD_CAN1_DelayedTxMessages 1;
BA_ "CANzero_SDO_Group" SG_ 1411 CLU_OD_CAN1_ErrorStatus "CAN";
BA_ "CANzero_SDO_AccessType" SG_ 1411 CLU_OD_CAN1_ErrorStatus 1;
BA_ "CANzero_SDO_AccessIfOperational" SG_ 1411 CLU_OD_CAN1_ErrorStatus 1;
BA_ "CANzero_SDO_Group" SG_ 1411 CLU_OD_CAN1_DiscardedTxMessages "CAN";
BA_ "CANzero_SDO_AccessType" SG_ 1411 CLU_OD_CAN1_DiscardedTxMessages 1;
BA_ "CANzero_SDO_AccessIfOperational" SG_ 1411 CLU_OD_CAN1_DiscardedTxMessages 1;
BA_ "CANzero_SDO_Group" SG_ 1411 CLU_OD_CAN1_Status "CAN";
BA_ "CANzero_SDO_AccessType" SG_ 1411 CLU_OD_CAN1_Status 1;
BA_ "CANzero_SDO_AccessIfOperational" SG_ 1411 CLU_OD_CAN1_Status 1;
BA_ "CANzero_SDO_Group" SG_ 1411 CLU_OD_CAN1_Baudrate "CAN";
BA_ "CANzero_SDO_AccessIfOperational" SG_ 1411 CLU_OD_CAN1_Baudrate 1;
BA_ "GenSigStartValue" SG_ 1411 CLU_OD_CAN1_Baudrate 1000.0;
BA_ "CANzero_SDO_Default" SG_ 1411 CLU_OD_CAN1_Baudrate 1000;
BA_ "CANzero_SDO_Group" SG_ 1411 CLU_OD_CAN1_autoErrorReset "CAN";
BA_ "CANzero_SDO_AccessIfOperational" SG_ 1411 CLU_OD_CAN1_autoErrorReset 1;
BA_ "GenSigStartValue" SG_ 1411 CLU_OD_CAN1_autoErrorReset 1.0;
BA_ "CANzero_SDO_Default" SG_ 1411 CLU_OD_CAN1_autoErrorReset 1;
BA_ "CANzero_SDO_Group" SG_ 1411 CLU_OD_CAN1_lastErrorCode "CAN";
BA_ "CANzero_SDO_AccessType" SG_ 1411 CLU_OD_CAN1_lastErrorCode 1;
BA_ "CANzero_SDO_AccessIfOperational" SG_ 1411 CLU_OD_CAN1_lastErrorCode 1;
BA_ "CANzero_SDO_Group" SG_ 1411 CLU_OD_CAN1_RxErrCnt "CAN";
BA_ "CANzero_SDO_AccessType" SG_ 1411 CLU_OD_CAN1_RxErrCnt 1;
BA_ "CANzero_SDO_AccessIfOperational" SG_ 1411 CLU_OD_CAN1_RxErrCnt 1;
BA_ "CANzero_SDO_Group" SG_ 1411 CLU_OD_CAN1_TxErrCnt "CAN";
BA_ "CANzero_SDO_AccessType" SG_ 1411 CLU_OD_CAN1_TxErrCnt 1;
BA_ "CANzero_SDO_AccessIfOperational" SG_ 1411 CLU_OD_CAN1_TxErrCnt 1;
BA_ "CANzero_SDO_AccessType" SG_ 1411 CLU_OD_BuildTime 1;
BA_ "CANzero_SDO_AccessIfOperational" SG_ 1411 CLU_OD_BuildTime 1;
BA_ "CANzero_SDO_AccessType" SG_ 1411 CLU_OD_BuildDate 1;
BA_ "CANzero_SDO_AccessIfOperational" SG_ 1411 CLU_OD_BuildDate 1;
BA_ "CANzero_SDO_AccessType" SG_ 1411 CLU_OD_ChipUID2 1;
BA_ "CANzero_SDO_AccessIfOperational" SG_ 1411 CLU_OD_ChipUID2 1;
BA_ "CANzero_SDO_AccessType" SG_ 1411 CLU_OD_ChipUID1 1;
BA_ "CANzero_SDO_AccessIfOperational" SG_ 1411 CLU_OD_ChipUID1 1;
BA_ "CANzero_SDO_AccessType" SG_ 1411 CLU_OD_SdcOut 1;
BA_ "CANzero_SDO_AccessIfOperational" SG_ 1411 CLU_OD_SdcOut 1;
BA_ "CANzero_SDO_AccessType" SG_ 1411 CLU_OD_SdcIn 1;
BA_ "CANzero_SDO_AccessIfOperational" SG_ 1411 CLU_OD_SdcIn 1;
BA_ "CANzero_SDO_AccessType" SG_ 1411 CLU_OD_runtime 1;
BA_ "CANzero_SDO_AccessIfOperational" SG_ 1411 CLU_OD_runtime 1;
BA_ "CANzero_SDO_AccessType" SG_ 1411 CLU_OD_InputVoltage 1;
BA_ "CANzero_SDO_AccessIfOperational" SG_ 1411 CLU_OD_InputVoltage 1;
BA_ "CANzero_SDO_AccessType" SG_ 1411 CLU_OD_BoardTemp 1;
BA_ "CANzero_SDO_AccessIfOperational" SG_ 1411 CLU_OD_BoardTemp 1;
BA_ "GenSigStartValue" SG_ 1411 CLU_OD_BoardTemp 3000.0;
BA_ "CANzero_SDO_AccessType" SG_ 1411 CLU_OD_MemFree 1;
BA_ "CANzero_SDO_AccessIfOperational" SG_ 1411 CLU_OD_MemFree 1;
BA_ "CANzero_SDO_AccessType" SG_ 1411 CLU_OD_CpuUsage 1;
BA_ "CANzero_SDO_AccessIfOperational" SG_ 1411 CLU_OD_CpuUsage 1;
BA_ "CANzero_SDO_AccessIfOperational" SG_ 1411 CLU_OD_OdEntrySendInterval 1;
BA_ "GenSigStartValue" SG_ 1411 CLU_OD_OdEntrySendInterval 50.0;
BA_ "CANzero_SDO_Default" SG_ 1411 CLU_OD_OdEntrySendInterval 50;
BA_ "CANzero_SDO_AccessIfOperational" SG_ 1411 CLU_OD_SendOdOnBootup 1;
BA_ "CANzero_SDO_AccessIfOperational" SG_ 1411 CLU_OD_HeartbeatInterval 1;
BA_ "GenSigStartValue" SG_ 1411 CLU_OD_HeartbeatInterval 250.0;
BA_ "CANzero_SDO_Default" SG_ 1411 CLU_OD_HeartbeatInterval 250;
BA_ "CANzero_SDO_AccessType" SG_ 1411 CLU_OD_DbcVersion 1;
BA_ "CANzero_SDO_AccessIfOperational" SG_ 1411 CLU_OD_DbcVersion 1;
BA_ "CANzero_SDO_AccessType" SG_ 1411 CLU_OD_StackVersion 1;
BA_ "CANzero_SDO_AccessIfOperational" SG_ 1411 CLU_OD_StackVersion 1;
BA_ "CANzero_SDO_AccessType" SG_ 1411 CLU_OD_ProtocolVersion 1;
BA_ "CANzero_SDO_AccessIfOperational" SG_ 1411 CLU_OD_ProtocolVersion 1;
BA_ "GenSigStartValue" SG_ 1411 CLU_OD_ProtocolVersion 1.0;
BA_ "CANzero_SDO_Default" SG_ 1411 CLU_OD_ProtocolVersion 1;
BA_ "CANzero_SDO_AccessType" SG_ 1411 CLU_OD_NodeStatus 1;
BA_ "CANzero_SDO_AccessIfOperational" SG_ 1411 CLU_OD_NodeStatus 1;
BA_ "CANzero_SDO_AccessType" SG_ 1411 CLU_OD_NodeID 1;
BA_ "CANzero_SDO_AccessIfOperational" SG_ 1411 CLU_OD_NodeID 1;
BA_ "CANzero_SDO_Group" SG_ 1475 CLU_OD_CAN2_DelayedTxMessages "CAN";
BA_ "CANzero_SDO_AccessType" SG_ 1475 CLU_OD_CAN2_DelayedTxMessages 1;
BA_ "CANzero_SDO_AccessIfOperational" SG_ 1475 CLU_OD_CAN2_DelayedTxMessages 1;
BA_ "CANzero_SDO_Group" SG_ 1475 CLU_OD_CAN2_ErrorStatus "CAN";
BA_ "CANzero_SDO_AccessType" SG_ 1475 CLU_OD_CAN2_ErrorStatus 1;
BA_ "CANzero_SDO_AccessIfOperational" SG_ 1475 CLU_OD_CAN2_ErrorStatus 1;
BA_ "CANzero_SDO_Group" SG_ 1475 CLU_OD_CAN2_DiscardedTxMessages "CAN";
BA_ "CANzero_SDO_AccessType" SG_ 1475 CLU_OD_CAN2_DiscardedTxMessages 1;
BA_ "CANzero_SDO_AccessIfOperational" SG_ 1475 CLU_OD_CAN2_DiscardedTxMessages 1;
BA_ "CANzero_SDO_Group" SG_ 1475 CLU_OD_CAN2_Status "CAN";
BA_ "CANzero_SDO_AccessType" SG_ 1475 CLU_OD_CAN2_Status 1;
BA_ "CANzero_SDO_AccessIfOperational" SG_ 1475 CLU_OD_CAN2_Status 1;
BA_ "CANzero_SDO_Group" SG_ 1475 CLU_OD_CAN2_Baudrate "CAN";
BA_ "CANzero_SDO_AccessIfOperational" SG_ 1475 CLU_OD_CAN2_Baudrate 1;
BA_ "GenSigStartValue" SG_ 1475 CLU_OD_CAN2_Baudrate 1000.0;
BA_ "CANzero_SDO_Default" SG_ 1475 CLU_OD_CAN2_Baudrate 1000;
BA_ "CANzero_SDO_Group" SG_ 1475 CLU_OD_CAN2_autoErrorReset "CAN";
BA_ "CANzero_SDO_AccessIfOperational" SG_ 1475 CLU_OD_CAN2_autoErrorReset 1;
BA_ "GenSigStartValue" SG_ 1475 CLU_OD_CAN2_autoErrorReset 1.0;
BA_ "CANzero_SDO_Default" SG_ 1475 CLU_OD_CAN2_autoErrorReset 1;
BA_ "CANzero_SDO_Group" SG_ 1475 CLU_OD_CAN2_lastErrorCode "CAN";
BA_ "CANzero_SDO_AccessType" SG_ 1475 CLU_OD_CAN2_lastErrorCode 1;
BA_ "CANzero_SDO_AccessIfOperational" SG_ 1475 CLU_OD_CAN2_lastErrorCode 1;
BA_ "CANzero_SDO_Group" SG_ 1475 CLU_OD_CAN2_RxErrCnt "CAN";
BA_ "CANzero_SDO_AccessType" SG_ 1475 CLU_OD_CAN2_RxErrCnt 1;
BA_ "CANzero_SDO_AccessIfOperational" SG_ 1475 CLU_OD_CAN2_RxErrCnt 1;
BA_ "CANzero_SDO_Group" SG_ 1475 CLU_OD_CAN2_TxErrCnt "CAN";
BA_ "CANzero_SDO_AccessType" SG_ 1475 CLU_OD_CAN2_TxErrCnt 1;
BA_ "CANzero_SDO_AccessIfOperational" SG_ 1475 CLU_OD_CAN2_TxErrCnt 1;
BA_ "CANzero_SDO_Group" SG_ 1475 CLU_OD_CAN1_DelayedTxMessages "CAN";
BA_ "CANzero_SDO_AccessType" SG_ 1475 CLU_OD_CAN1_DelayedTxMessages 1;
BA_ "CANzero_SDO_AccessIfOperational" SG_ 1475 CLU_OD_CAN1_DelayedTxMessages 1;
BA_ "CANzero_SDO_Group" SG_ 1475 CLU_OD_CAN1_ErrorStatus "CAN";
BA_ "CANzero_SDO_AccessType" SG_ 1475 CLU_OD_CAN1_ErrorStatus 1;
BA_ "CANzero_SDO_AccessIfOperational" SG_ 1475 CLU_OD_CAN1_ErrorStatus 1;
BA_ "CANzero_SDO_Group" SG_ 1475 CLU_OD_CAN1_DiscardedTxMessages "CAN";
BA_ "CANzero_SDO_AccessType" SG_ 1475 CLU_OD_CAN1_DiscardedTxMessages 1;
BA_ "CANzero_SDO_AccessIfOperational" SG_ 1475 CLU_OD_CAN1_DiscardedTxMessages 1;
BA_ "CANzero_SDO_Group" SG_ 1475 CLU_OD_CAN1_Status "CAN";
BA_ "CANzero_SDO_AccessType" SG_ 1475 CLU_OD_CAN1_Status 1;
BA_ "CANzero_SDO_AccessIfOperational" SG_ 1475 CLU_OD_CAN1_Status 1;
BA_ "CANzero_SDO_Group" SG_ 1475 CLU_OD_CAN1_Baudrate "CAN";
BA_ "CANzero_SDO_AccessIfOperational" SG_ 1475 CLU_OD_CAN1_Baudrate 1;
BA_ "GenSigStartValue" SG_ 1475 CLU_OD_CAN1_Baudrate 1000.0;
BA_ "CANzero_SDO_Default" SG_ 1475 CLU_OD_CAN1_Baudrate 1000;
BA_ "CANzero_SDO_Group" SG_ 1475 CLU_OD_CAN1_autoErrorReset "CAN";
BA_ "CANzero_SDO_AccessIfOperational" SG_ 1475 CLU_OD_CAN1_autoErrorReset 1;
BA_ "GenSigStartValue" SG_ 1475 CLU_OD_CAN1_autoErrorReset 1.0;
BA_ "CANzero_SDO_Default" SG_ 1475 CLU_OD_CAN1_autoErrorReset 1;
BA_ "CANzero_SDO_Group" SG_ 1475 CLU_OD_CAN1_lastErrorCode "CAN";
BA_ "CANzero_SDO_AccessType" SG_ 1475 CLU_OD_CAN1_lastErrorCode 1;
BA_ "CANzero_SDO_AccessIfOperational" SG_ 1475 CLU_OD_CAN1_lastErrorCode 1;
BA_ "CANzero_SDO_Group" SG_ 1475 CLU_OD_CAN1_RxErrCnt "CAN";
BA_ "CANzero_SDO_AccessType" SG_ 1475 CLU_OD_CAN1_RxErrCnt 1;
BA_ "CANzero_SDO_AccessIfOperational" SG_ 1475 CLU_OD_CAN1_RxErrCnt 1;
BA_ "CANzero_SDO_Group" SG_ 1475 CLU_OD_CAN1_TxErrCnt "CAN";
BA_ "CANzero_SDO_AccessType" SG_ 1475 CLU_OD_CAN1_TxErrCnt 1;
BA_ "CANzero_SDO_AccessIfOperational" SG_ 1475 CLU_OD_CAN1_TxErrCnt 1;
BA_ "CANzero_SDO_AccessType" SG_ 1475 CLU_OD_BuildTime 1;
BA_ "CANzero_SDO_AccessIfOperational" SG_ 1475 CLU_OD_BuildTime 1;
BA_ "CANzero_SDO_AccessType" SG_ 1475 CLU_OD_BuildDate 1;
BA_ "CANzero_SDO_AccessIfOperational" SG_ 1475 CLU_OD_BuildDate 1;
BA_ "CANzero_SDO_AccessType" SG_ 1475 CLU_OD_ChipUID2 1;
BA_ "CANzero_SDO_AccessIfOperational" SG_ 1475 CLU_OD_ChipUID2 1;
BA_ "CANzero_SDO_AccessType" SG_ 1475 CLU_OD_ChipUID1 1;
BA_ "CANzero_SDO_AccessIfOperational" SG_ 1475 CLU_OD_ChipUID1 1;
BA_ "CANzero_SDO_AccessType" SG_ 1475 CLU_OD_SdcOut 1;
BA_ "CANzero_SDO_AccessIfOperational" SG_ 1475 CLU_OD_SdcOut 1;
BA_ "CANzero_SDO_AccessType" SG_ 1475 CLU_OD_SdcIn 1;
BA_ "CANzero_SDO_AccessIfOperational" SG_ 1475 CLU_OD_SdcIn 1;
BA_ "CANzero_SDO_AccessType" SG_ 1475 CLU_OD_runtime 1;
BA_ "CANzero_SDO_AccessIfOperational" SG_ 1475 CLU_OD_runtime 1;
BA_ "CANzero_SDO_AccessType" SG_ 1475 CLU_OD_InputVoltage 1;
BA_ "CANzero_SDO_AccessIfOperational" SG_ 1475 CLU_OD_InputVoltage 1;
BA_ "CANzero_SDO_AccessType" SG_ 1475 CLU_OD_BoardTemp 1;
BA_ "CANzero_SDO_AccessIfOperational" SG_ 1475 CLU_OD_BoardTemp 1;
BA_ "GenSigStartValue" SG_ 1475 CLU_OD_BoardTemp 3000.0;
BA_ "CANzero_SDO_AccessType" SG_ 1475 CLU_OD_MemFree 1;
BA_ "CANzero_SDO_AccessIfOperational" SG_ 1475 CLU_OD_MemFree 1;
BA_ "CANzero_SDO_AccessType" SG_ 1475 CLU_OD_CpuUsage 1;
BA_ "CANzero_SDO_AccessIfOperational" SG_ 1475 CLU_OD_CpuUsage 1;
BA_ "CANzero_SDO_AccessIfOperational" SG_ 1475 CLU_OD_OdEntrySendInterval 1;
BA_ "GenSigStartValue" SG_ 1475 CLU_OD_OdEntrySendInterval 50.0;
BA_ "CANzero_SDO_Default" SG_ 1475 CLU_OD_OdEntrySendInterval 50;
BA_ "CANzero_SDO_AccessIfOperational" SG_ 1475 CLU_OD_SendOdOnBootup 1;
BA_ "CANzero_SDO_AccessIfOperational" SG_ 1475 CLU_OD_HeartbeatInterval 1;
BA_ "GenSigStartValue" SG_ 1475 CLU_OD_HeartbeatInterval 250.0;
BA_ "CANzero_SDO_Default" SG_ 1475 CLU_OD_HeartbeatInterval 250;
BA_ "CANzero_SDO_AccessType" SG_ 1475 CLU_OD_DbcVersion 1;
BA_ "CANzero_SDO_AccessIfOperational" SG_ 1475 CLU_OD_DbcVersion 1;
BA_ "CANzero_SDO_AccessType" SG_ 1475 CLU_OD_StackVersion 1;
BA_ "CANzero_SDO_AccessIfOperational" SG_ 1475 CLU_OD_StackVersion 1;
BA_ "CANzero_SDO_AccessType" SG_ 1475 CLU_OD_ProtocolVersion 1;
BA_ "CANzero_SDO_AccessIfOperational" SG_ 1475 CLU_OD_ProtocolVersion 1;
BA_ "GenSigStartValue" SG_ 1475 CLU_OD_ProtocolVersion 1.0;
BA_ "CANzero_SDO_Default" SG_ 1475 CLU_OD_ProtocolVersion 1;
BA_ "CANzero_SDO_AccessType" SG_ 1475 CLU_OD_NodeStatus 1;
BA_ "CANzero_SDO_AccessIfOperational" SG_ 1475 CLU_OD_NodeStatus 1;
BA_ "CANzero_SDO_AccessType" SG_ 1475 CLU_OD_NodeID 1;
BA_ "CANzero_SDO_AccessIfOperational" SG_ 1475 CLU_OD_NodeID 1;
BA_ "CANzero_SDO_Group" SG_ 1412 BRAKE_OD_CAN2_DelayedTxMessages "CAN";
BA_ "CANzero_SDO_AccessType" SG_ 1412 BRAKE_OD_CAN2_DelayedTxMessages 1;
BA_ "CANzero_SDO_AccessIfOperational" SG_ 1412 BRAKE_OD_CAN2_DelayedTxMessages 1;
BA_ "CANzero_SDO_Group" SG_ 1412 BRAKE_OD_CAN2_ErrorStatus "CAN";
BA_ "CANzero_SDO_AccessType" SG_ 1412 BRAKE_OD_CAN2_ErrorStatus 1;
BA_ "CANzero_SDO_AccessIfOperational" SG_ 1412 BRAKE_OD_CAN2_ErrorStatus 1;
BA_ "CANzero_SDO_Group" SG_ 1412 BRAKE_OD_CAN2_DiscardedTxMessage "CAN";
BA_ "CANzero_SDO_AccessType" SG_ 1412 BRAKE_OD_CAN2_DiscardedTxMessage 1;
BA_ "CANzero_SDO_AccessIfOperational" SG_ 1412 BRAKE_OD_CAN2_DiscardedTxMessage 1;
BA_ "SystemSignalLongSymbol" SG_ 1412 BRAKE_OD_CAN2_DiscardedTxMessage "BRAKE_OD_CAN2_DiscardedTxMessages";
BA_ "CANzero_SDO_Group" SG_ 1412 BRAKE_OD_CAN2_Status "CAN";
BA_ "CANzero_SDO_AccessType" SG_ 1412 BRAKE_OD_CAN2_Status 1;
BA_ "CANzero_SDO_AccessIfOperational" SG_ 1412 BRAKE_OD_CAN2_Status 1;
BA_ "CANzero_SDO_Group" SG_ 1412 BRAKE_OD_CAN2_Baudrate "CAN";
BA_ "CANzero_SDO_AccessIfOperational" SG_ 1412 BRAKE_OD_CAN2_Baudrate 1;
BA_ "GenSigStartValue" SG_ 1412 BRAKE_OD_CAN2_Baudrate 1000.0;
BA_ "CANzero_SDO_Default" SG_ 1412 BRAKE_OD_CAN2_Baudrate 1000;
BA_ "CANzero_SDO_Group" SG_ 1412 BRAKE_OD_CAN2_autoErrorReset "CAN";
BA_ "CANzero_SDO_AccessIfOperational" SG_ 1412 BRAKE_OD_CAN2_autoErrorReset 1;
BA_ "GenSigStartValue" SG_ 1412 BRAKE_OD_CAN2_autoErrorReset 1.0;
BA_ "CANzero_SDO_Default" SG_ 1412 BRAKE_OD_CAN2_autoErrorReset 1;
BA_ "CANzero_SDO_Group" SG_ 1412 BRAKE_OD_CAN2_lastErrorCode "CAN";
BA_ "CANzero_SDO_AccessType" SG_ 1412 BRAKE_OD_CAN2_lastErrorCode 1;
BA_ "CANzero_SDO_AccessIfOperational" SG_ 1412 BRAKE_OD_CAN2_lastErrorCode 1;
BA_ "CANzero_SDO_Group" SG_ 1412 BRAKE_OD_CAN2_RxErrCnt "CAN";
BA_ "CANzero_SDO_AccessType" SG_ 1412 BRAKE_OD_CAN2_RxErrCnt 1;
BA_ "CANzero_SDO_AccessIfOperational" SG_ 1412 BRAKE_OD_CAN2_RxErrCnt 1;
BA_ "CANzero_SDO_Group" SG_ 1412 BRAKE_OD_CAN2_TxErrCnt "CAN";
BA_ "CANzero_SDO_AccessType" SG_ 1412 BRAKE_OD_CAN2_TxErrCnt 1;
BA_ "CANzero_SDO_AccessIfOperational" SG_ 1412 BRAKE_OD_CAN2_TxErrCnt 1;
BA_ "CANzero_SDO_Group" SG_ 1412 BRAKE_OD_CAN1_DelayedTxMessages "CAN";
BA_ "CANzero_SDO_AccessType" SG_ 1412 BRAKE_OD_CAN1_DelayedTxMessages 1;
BA_ "CANzero_SDO_AccessIfOperational" SG_ 1412 BRAKE_OD_CAN1_DelayedTxMessages 1;
BA_ "CANzero_SDO_Group" SG_ 1412 BRAKE_OD_CAN1_ErrorStatus "CAN";
BA_ "CANzero_SDO_AccessType" SG_ 1412 BRAKE_OD_CAN1_ErrorStatus 1;
BA_ "CANzero_SDO_AccessIfOperational" SG_ 1412 BRAKE_OD_CAN1_ErrorStatus 1;
BA_ "CANzero_SDO_Group" SG_ 1412 BRAKE_OD_CAN1_DiscardedTxMessage "CAN";
BA_ "CANzero_SDO_AccessType" SG_ 1412 BRAKE_OD_CAN1_DiscardedTxMessage 1;
BA_ "CANzero_SDO_AccessIfOperational" SG_ 1412 BRAKE_OD_CAN1_DiscardedTxMessage 1;
BA_ "SystemSignalLongSymbol" SG_ 1412 BRAKE_OD_CAN1_DiscardedTxMessage "BRAKE_OD_CAN1_DiscardedTxMessages";
BA_ "CANzero_SDO_Group" SG_ 1412 BRAKE_OD_CAN1_Status "CAN";
BA_ "CANzero_SDO_AccessType" SG_ 1412 BRAKE_OD_CAN1_Status 1;
BA_ "CANzero_SDO_AccessIfOperational" SG_ 1412 BRAKE_OD_CAN1_Status 1;
BA_ "CANzero_SDO_Group" SG_ 1412 BRAKE_OD_CAN1_Baudrate "CAN";
BA_ "CANzero_SDO_AccessIfOperational" SG_ 1412 BRAKE_OD_CAN1_Baudrate 1;
BA_ "GenSigStartValue" SG_ 1412 BRAKE_OD_CAN1_Baudrate 1000.0;
BA_ "CANzero_SDO_Default" SG_ 1412 BRAKE_OD_CAN1_Baudrate 1000;
BA_ "CANzero_SDO_Group" SG_ 1412 BRAKE_OD_CAN1_autoErrorReset "CAN";
BA_ "CANzero_SDO_AccessIfOperational" SG_ 1412 BRAKE_OD_CAN1_autoErrorReset 1;
BA_ "GenSigStartValue" SG_ 1412 BRAKE_OD_CAN1_autoErrorReset 1.0;
BA_ "CANzero_SDO_Default" SG_ 1412 BRAKE_OD_CAN1_autoErrorReset 1;
BA_ "CANzero_SDO_Group" SG_ 1412 BRAKE_OD_CAN1_lastErrorCode "CAN";
BA_ "CANzero_SDO_AccessType" SG_ 1412 BRAKE_OD_CAN1_lastErrorCode 1;
BA_ "CANzero_SDO_AccessIfOperational" SG_ 1412 BRAKE_OD_CAN1_lastErrorCode 1;
BA_ "CANzero_SDO_Group" SG_ 1412 BRAKE_OD_CAN1_RxErrCnt "CAN";
BA_ "CANzero_SDO_AccessType" SG_ 1412 BRAKE_OD_CAN1_RxErrCnt 1;
BA_ "CANzero_SDO_AccessIfOperational" SG_ 1412 BRAKE_OD_CAN1_RxErrCnt 1;
BA_ "CANzero_SDO_Group" SG_ 1412 BRAKE_OD_CAN1_TxErrCnt "CAN";
BA_ "CANzero_SDO_AccessType" SG_ 1412 BRAKE_OD_CAN1_TxErrCnt 1;
BA_ "CANzero_SDO_AccessIfOperational" SG_ 1412 BRAKE_OD_CAN1_TxErrCnt 1;
BA_ "CANzero_SDO_AccessType" SG_ 1412 BRAKE_OD_BuildTime 1;
BA_ "CANzero_SDO_AccessIfOperational" SG_ 1412 BRAKE_OD_BuildTime 1;
BA_ "CANzero_SDO_AccessType" SG_ 1412 BRAKE_OD_BuildDate 1;
BA_ "CANzero_SDO_AccessIfOperational" SG_ 1412 BRAKE_OD_BuildDate 1;
BA_ "CANzero_SDO_AccessType" SG_ 1412 BRAKE_OD_ChipUID2 1;
BA_ "CANzero_SDO_AccessIfOperational" SG_ 1412 BRAKE_OD_ChipUID2 1;
BA_ "CANzero_SDO_AccessType" SG_ 1412 BRAKE_OD_ChipUID1 1;
BA_ "CANzero_SDO_AccessIfOperational" SG_ 1412 BRAKE_OD_ChipUID1 1;
BA_ "CANzero_SDO_AccessType" SG_ 1412 BRAKE_OD_SdcOut 1;
BA_ "CANzero_SDO_AccessIfOperational" SG_ 1412 BRAKE_OD_SdcOut 1;
BA_ "CANzero_SDO_AccessType" SG_ 1412 BRAKE_OD_SdcIn 1;
BA_ "CANzero_SDO_AccessIfOperational" SG_ 1412 BRAKE_OD_SdcIn 1;
BA_ "CANzero_SDO_AccessType" SG_ 1412 BRAKE_OD_runtime 1;
BA_ "CANzero_SDO_AccessIfOperational" SG_ 1412 BRAKE_OD_runtime 1;
BA_ "CANzero_SDO_AccessType" SG_ 1412 BRAKE_OD_InputVoltage 1;
BA_ "CANzero_SDO_AccessIfOperational" SG_ 1412 BRAKE_OD_InputVoltage 1;
BA_ "CANzero_SDO_AccessType" SG_ 1412 BRAKE_OD_BoardTemp 1;
BA_ "CANzero_SDO_AccessIfOperational" SG_ 1412 BRAKE_OD_BoardTemp 1;
BA_ "GenSigStartValue" SG_ 1412 BRAKE_OD_BoardTemp 3000.0;
BA_ "CANzero_SDO_AccessType" SG_ 1412 BRAKE_OD_MemFree 1;
BA_ "CANzero_SDO_AccessIfOperational" SG_ 1412 BRAKE_OD_MemFree 1;
BA_ "CANzero_SDO_AccessType" SG_ 1412 BRAKE_OD_CpuUsage 1;
BA_ "CANzero_SDO_AccessIfOperational" SG_ 1412 BRAKE_OD_CpuUsage 1;
BA_ "CANzero_SDO_AccessIfOperational" SG_ 1412 BRAKE_OD_OdEntrySendInterval 1;
BA_ "GenSigStartValue" SG_ 1412 BRAKE_OD_OdEntrySendInterval 50.0;
BA_ "CANzero_SDO_Default" SG_ 1412 BRAKE_OD_OdEntrySendInterval 50;
BA_ "CANzero_SDO_AccessIfOperational" SG_ 1412 BRAKE_OD_SendOdOnBootup 1;
BA_ "CANzero_SDO_AccessIfOperational" SG_ 1412 BRAKE_OD_HeartbeatInterval 1;
BA_ "GenSigStartValue" SG_ 1412 BRAKE_OD_HeartbeatInterval 250.0;
BA_ "CANzero_SDO_Default" SG_ 1412 BRAKE_OD_HeartbeatInterval 250;
BA_ "CANzero_SDO_AccessType" SG_ 1412 BRAKE_OD_DbcVersion 1;
BA_ "CANzero_SDO_AccessIfOperational" SG_ 1412 BRAKE_OD_DbcVersion 1;
BA_ "CANzero_SDO_AccessType" SG_ 1412 BRAKE_OD_StackVersion 1;
BA_ "CANzero_SDO_AccessIfOperational" SG_ 1412 BRAKE_OD_StackVersion 1;
BA_ "CANzero_SDO_AccessType" SG_ 1412 BRAKE_OD_ProtocolVersion 1;
BA_ "CANzero_SDO_AccessIfOperational" SG_ 1412 BRAKE_OD_ProtocolVersion 1;
BA_ "GenSigStartValue" SG_ 1412 BRAKE_OD_ProtocolVersion 1.0;
BA_ "CANzero_SDO_Default" SG_ 1412 BRAKE_OD_ProtocolVersion 1;
BA_ "CANzero_SDO_AccessType" SG_ 1412 BRAKE_OD_NodeStatus 1;
BA_ "CANzero_SDO_AccessIfOperational" SG_ 1412 BRAKE_OD_NodeStatus 1;
BA_ "CANzero_SDO_AccessType" SG_ 1412 BRAKE_OD_NodeID 1;
BA_ "CANzero_SDO_AccessIfOperational" SG_ 1412 BRAKE_OD_NodeID 1;
BA_ "CANzero_SDO_Group" SG_ 1476 BRAKE_OD_CAN2_DelayedTxMessages "CAN";
BA_ "CANzero_SDO_AccessType" SG_ 1476 BRAKE_OD_CAN2_DelayedTxMessages 1;
BA_ "CANzero_SDO_AccessIfOperational" SG_ 1476 BRAKE_OD_CAN2_DelayedTxMessages 1;
BA_ "CANzero_SDO_Group" SG_ 1476 BRAKE_OD_CAN2_ErrorStatus "CAN";
BA_ "CANzero_SDO_AccessType" SG_ 1476 BRAKE_OD_CAN2_ErrorStatus 1;
BA_ "CANzero_SDO_AccessIfOperational" SG_ 1476 BRAKE_OD_CAN2_ErrorStatus 1;
BA_ "CANzero_SDO_Group" SG_ 1476 BRAKE_OD_CAN2_DiscardedTxMe_0000 "CAN";
BA_ "CANzero_SDO_AccessType" SG_ 1476 BRAKE_OD_CAN2_DiscardedTxMe_0000 1;
BA_ "CANzero_SDO_AccessIfOperational" SG_ 1476 BRAKE_OD_CAN2_DiscardedTxMe_0000 1;
BA_ "SystemSignalLongSymbol" SG_ 1476 BRAKE_OD_CAN2_DiscardedTxMe_0000 "BRAKE_OD_CAN2_DiscardedTxMessages";
BA_ "CANzero_SDO_Group" SG_ 1476 BRAKE_OD_CAN2_Status "CAN";
BA_ "CANzero_SDO_AccessType" SG_ 1476 BRAKE_OD_CAN2_Status 1;
BA_ "CANzero_SDO_AccessIfOperational" SG_ 1476 BRAKE_OD_CAN2_Status 1;
BA_ "CANzero_SDO_Group" SG_ 1476 BRAKE_OD_CAN2_Baudrate "CAN";
BA_ "CANzero_SDO_AccessIfOperational" SG_ 1476 BRAKE_OD_CAN2_Baudrate 1;
BA_ "GenSigStartValue" SG_ 1476 BRAKE_OD_CAN2_Baudrate 1000.0;
BA_ "CANzero_SDO_Default" SG_ 1476 BRAKE_OD_CAN2_Baudrate 1000;
BA_ "CANzero_SDO_Group" SG_ 1476 BRAKE_OD_CAN2_autoErrorReset "CAN";
BA_ "CANzero_SDO_AccessIfOperational" SG_ 1476 BRAKE_OD_CAN2_autoErrorReset 1;
BA_ "GenSigStartValue" SG_ 1476 BRAKE_OD_CAN2_autoErrorReset 1.0;
BA_ "CANzero_SDO_Default" SG_ 1476 BRAKE_OD_CAN2_autoErrorReset 1;
BA_ "CANzero_SDO_Group" SG_ 1476 BRAKE_OD_CAN2_lastErrorCode "CAN";
BA_ "CANzero_SDO_AccessType" SG_ 1476 BRAKE_OD_CAN2_lastErrorCode 1;
BA_ "CANzero_SDO_AccessIfOperational" SG_ 1476 BRAKE_OD_CAN2_lastErrorCode 1;
BA_ "CANzero_SDO_Group" SG_ 1476 BRAKE_OD_CAN2_RxErrCnt "CAN";
BA_ "CANzero_SDO_AccessType" SG_ 1476 BRAKE_OD_CAN2_RxErrCnt 1;
BA_ "CANzero_SDO_AccessIfOperational" SG_ 1476 BRAKE_OD_CAN2_RxErrCnt 1;
BA_ "CANzero_SDO_Group" SG_ 1476 BRAKE_OD_CAN2_TxErrCnt "CAN";
BA_ "CANzero_SDO_AccessType" SG_ 1476 BRAKE_OD_CAN2_TxErrCnt 1;
BA_ "CANzero_SDO_AccessIfOperational" SG_ 1476 BRAKE_OD_CAN2_TxErrCnt 1;
BA_ "CANzero_SDO_Group" SG_ 1476 BRAKE_OD_CAN1_DelayedTxMessages "CAN";
BA_ "CANzero_SDO_AccessType" SG_ 1476 BRAKE_OD_CAN1_DelayedTxMessages 1;
BA_ "CANzero_SDO_AccessIfOperational" SG_ 1476 BRAKE_OD_CAN1_DelayedTxMessages 1;
BA_ "CANzero_SDO_Group" SG_ 1476 BRAKE_OD_CAN1_ErrorStatus "CAN";
BA_ "CANzero_SDO_AccessType" SG_ 1476 BRAKE_OD_CAN1_ErrorStatus 1;
BA_ "CANzero_SDO_AccessIfOperational" SG_ 1476 BRAKE_OD_CAN1_ErrorStatus 1;
BA_ "CANzero_SDO_Group" SG_ 1476 BRAKE_OD_CAN1_DiscardedTxMe_0000 "CAN";
BA_ "CANzero_SDO_AccessType" SG_ 1476 BRAKE_OD_CAN1_DiscardedTxMe_0000 1;
BA_ "CANzero_SDO_AccessIfOperational" SG_ 1476 BRAKE_OD_CAN1_DiscardedTxMe_0000 1;
BA_ "SystemSignalLongSymbol" SG_ 1476 BRAKE_OD_CAN1_DiscardedTxMe_0000 "BRAKE_OD_CAN1_DiscardedTxMessages";
BA_ "CANzero_SDO_Group" SG_ 1476 BRAKE_OD_CAN1_Status "CAN";
BA_ "CANzero_SDO_AccessType" SG_ 1476 BRAKE_OD_CAN1_Status 1;
BA_ "CANzero_SDO_AccessIfOperational" SG_ 1476 BRAKE_OD_CAN1_Status 1;
BA_ "CANzero_SDO_Group" SG_ 1476 BRAKE_OD_CAN1_Baudrate "CAN";
BA_ "CANzero_SDO_AccessIfOperational" SG_ 1476 BRAKE_OD_CAN1_Baudrate 1;
BA_ "GenSigStartValue" SG_ 1476 BRAKE_OD_CAN1_Baudrate 1000.0;
BA_ "CANzero_SDO_Default" SG_ 1476 BRAKE_OD_CAN1_Baudrate 1000;
BA_ "CANzero_SDO_Group" SG_ 1476 BRAKE_OD_CAN1_autoErrorReset "CAN";
BA_ "CANzero_SDO_AccessIfOperational" SG_ 1476 BRAKE_OD_CAN1_autoErrorReset 1;
BA_ "GenSigStartValue" SG_ 1476 BRAKE_OD_CAN1_autoErrorReset 1.0;
BA_ "CANzero_SDO_Default" SG_ 1476 BRAKE_OD_CAN1_autoErrorReset 1;
BA_ "CANzero_SDO_Group" SG_ 1476 BRAKE_OD_CAN1_lastErrorCode "CAN";
BA_ "CANzero_SDO_AccessType" SG_ 1476 BRAKE_OD_CAN1_lastErrorCode 1;
BA_ "CANzero_SDO_AccessIfOperational" SG_ 1476 BRAKE_OD_CAN1_lastErrorCode 1;
BA_ "CANzero_SDO_Group" SG_ 1476 BRAKE_OD_CAN1_RxErrCnt "CAN";
BA_ "CANzero_SDO_AccessType" SG_ 1476 BRAKE_OD_CAN1_RxErrCnt 1;
BA_ "CANzero_SDO_AccessIfOperational" SG_ 1476 BRAKE_OD_CAN1_RxErrCnt 1;
BA_ "CANzero_SDO_Group" SG_ 1476 BRAKE_OD_CAN1_TxErrCnt "CAN";
BA_ "CANzero_SDO_AccessType" SG_ 1476 BRAKE_OD_CAN1_TxErrCnt 1;
BA_ "CANzero_SDO_AccessIfOperational" SG_ 1476 BRAKE_OD_CAN1_TxErrCnt 1;
BA_ "CANzero_SDO_AccessType" SG_ 1476 BRAKE_OD_BuildTime 1;
BA_ "CANzero_SDO_AccessIfOperational" SG_ 1476 BRAKE_OD_BuildTime 1;
BA_ "CANzero_SDO_AccessType" SG_ 1476 BRAKE_OD_BuildDate 1;
BA_ "CANzero_SDO_AccessIfOperational" SG_ 1476 BRAKE_OD_BuildDate 1;
BA_ "CANzero_SDO_AccessType" SG_ 1476 BRAKE_OD_ChipUID2 1;
BA_ "CANzero_SDO_AccessIfOperational" SG_ 1476 BRAKE_OD_ChipUID2 1;
BA_ "CANzero_SDO_AccessType" SG_ 1476 BRAKE_OD_ChipUID1 1;
BA_ "CANzero_SDO_AccessIfOperational" SG_ 1476 BRAKE_OD_ChipUID1 1;
BA_ "CANzero_SDO_AccessType" SG_ 1476 BRAKE_OD_SdcOut 1;
BA_ "CANzero_SDO_AccessIfOperational" SG_ 1476 BRAKE_OD_SdcOut 1;
BA_ "CANzero_SDO_AccessType" SG_ 1476 BRAKE_OD_SdcIn 1;
BA_ "CANzero_SDO_AccessIfOperational" SG_ 1476 BRAKE_OD_SdcIn 1;
BA_ "CANzero_SDO_AccessType" SG_ 1476 BRAKE_OD_runtime 1;
BA_ "CANzero_SDO_AccessIfOperational" SG_ 1476 BRAKE_OD_runtime 1;
BA_ "CANzero_SDO_AccessType" SG_ 1476 BRAKE_OD_InputVoltage 1;
BA_ "CANzero_SDO_AccessIfOperational" SG_ 1476 BRAKE_OD_InputVoltage 1;
BA_ "CANzero_SDO_AccessType" SG_ 1476 BRAKE_OD_BoardTemp 1;
BA_ "CANzero_SDO_AccessIfOperational" SG_ 1476 BRAKE_OD_BoardTemp 1;
BA_ "GenSigStartValue" SG_ 1476 BRAKE_OD_BoardTemp 3000.0;
BA_ "CANzero_SDO_AccessType" SG_ 1476 BRAKE_OD_MemFree 1;
BA_ "CANzero_SDO_AccessIfOperational" SG_ 1476 BRAKE_OD_MemFree 1;
BA_ "CANzero_SDO_AccessType" SG_ 1476 BRAKE_OD_CpuUsage 1;
BA_ "CANzero_SDO_AccessIfOperational" SG_ 1476 BRAKE_OD_CpuUsage 1;
BA_ "CANzero_SDO_AccessIfOperational" SG_ 1476 BRAKE_OD_OdEntrySendInterval 1;
BA_ "GenSigStartValue" SG_ 1476 BRAKE_OD_OdEntrySendInterval 50.0;
BA_ "CANzero_SDO_Default" SG_ 1476 BRAKE_OD_OdEntrySendInterval 50;
BA_ "CANzero_SDO_AccessIfOperational" SG_ 1476 BRAKE_OD_SendOdOnBootup 1;
BA_ "CANzero_SDO_AccessIfOperational" SG_ 1476 BRAKE_OD_HeartbeatInterval 1;
BA_ "GenSigStartValue" SG_ 1476 BRAKE_OD_HeartbeatInterval 250.0;
BA_ "CANzero_SDO_Default" SG_ 1476 BRAKE_OD_HeartbeatInterval 250;
BA_ "CANzero_SDO_AccessType" SG_ 1476 BRAKE_OD_DbcVersion 1;
BA_ "CANzero_SDO_AccessIfOperational" SG_ 1476 BRAKE_OD_DbcVersion 1;
BA_ "CANzero_SDO_AccessType" SG_ 1476 BRAKE_OD_StackVersion 1;
BA_ "CANzero_SDO_AccessIfOperational" SG_ 1476 BRAKE_OD_StackVersion 1;
BA_ "CANzero_SDO_AccessType" SG_ 1476 BRAKE_OD_ProtocolVersion 1;
BA_ "CANzero_SDO_AccessIfOperational" SG_ 1476 BRAKE_OD_ProtocolVersion 1;
BA_ "GenSigStartValue" SG_ 1476 BRAKE_OD_ProtocolVersion 1.0;
BA_ "CANzero_SDO_Default" SG_ 1476 BRAKE_OD_ProtocolVersion 1;
BA_ "CANzero_SDO_AccessType" SG_ 1476 BRAKE_OD_NodeStatus 1;
BA_ "CANzero_SDO_AccessIfOperational" SG_ 1476 BRAKE_OD_NodeStatus 1;
BA_ "CANzero_SDO_AccessType" SG_ 1476 BRAKE_OD_NodeID 1;
BA_ "CANzero_SDO_AccessIfOperational" SG_ 1476 BRAKE_OD_NodeID 1;
BA_ "CANzero_SDO_Group" SG_ 1413 MLU_1_OD_CAN2_DelayedTxMessages "CAN";
BA_ "CANzero_SDO_AccessType" SG_ 1413 MLU_1_OD_CAN2_DelayedTxMessages 1;
BA_ "CANzero_SDO_AccessIfOperational" SG_ 1413 MLU_1_OD_CAN2_DelayedTxMessages 1;
BA_ "CANzero_SDO_Group" SG_ 1413 MLU_1_OD_CAN2_ErrorStatus "CAN";
BA_ "CANzero_SDO_AccessType" SG_ 1413 MLU_1_OD_CAN2_ErrorStatus 1;
BA_ "CANzero_SDO_AccessIfOperational" SG_ 1413 MLU_1_OD_CAN2_ErrorStatus 1;
BA_ "CANzero_SDO_Group" SG_ 1413 MLU_1_OD_CAN2_DiscardedTxMessage "CAN";
BA_ "CANzero_SDO_AccessType" SG_ 1413 MLU_1_OD_CAN2_DiscardedTxMessage 1;
BA_ "CANzero_SDO_AccessIfOperational" SG_ 1413 MLU_1_OD_CAN2_DiscardedTxMessage 1;
BA_ "SystemSignalLongSymbol" SG_ 1413 MLU_1_OD_CAN2_DiscardedTxMessage "MLU_1_OD_CAN2_DiscardedTxMessages";
BA_ "CANzero_SDO_Group" SG_ 1413 MLU_1_OD_CAN2_Status "CAN";
BA_ "CANzero_SDO_AccessType" SG_ 1413 MLU_1_OD_CAN2_Status 1;
BA_ "CANzero_SDO_AccessIfOperational" SG_ 1413 MLU_1_OD_CAN2_Status 1;
BA_ "CANzero_SDO_Group" SG_ 1413 MLU_1_OD_CAN2_Baudrate "CAN";
BA_ "CANzero_SDO_AccessIfOperational" SG_ 1413 MLU_1_OD_CAN2_Baudrate 1;
BA_ "GenSigStartValue" SG_ 1413 MLU_1_OD_CAN2_Baudrate 1000.0;
BA_ "CANzero_SDO_Default" SG_ 1413 MLU_1_OD_CAN2_Baudrate 1000;
BA_ "CANzero_SDO_Group" SG_ 1413 MLU_1_OD_CAN2_autoErrorReset "CAN";
BA_ "CANzero_SDO_AccessIfOperational" SG_ 1413 MLU_1_OD_CAN2_autoErrorReset 1;
BA_ "GenSigStartValue" SG_ 1413 MLU_1_OD_CAN2_autoErrorReset 1.0;
BA_ "CANzero_SDO_Default" SG_ 1413 MLU_1_OD_CAN2_autoErrorReset 1;
BA_ "CANzero_SDO_Group" SG_ 1413 MLU_1_OD_CAN2_lastErrorCode "CAN";
BA_ "CANzero_SDO_AccessType" SG_ 1413 MLU_1_OD_CAN2_lastErrorCode 1;
BA_ "CANzero_SDO_AccessIfOperational" SG_ 1413 MLU_1_OD_CAN2_lastErrorCode 1;
BA_ "CANzero_SDO_Group" SG_ 1413 MLU_1_OD_CAN2_RxErrCnt "CAN";
BA_ "CANzero_SDO_AccessType" SG_ 1413 MLU_1_OD_CAN2_RxErrCnt 1;
BA_ "CANzero_SDO_AccessIfOperational" SG_ 1413 MLU_1_OD_CAN2_RxErrCnt 1;
BA_ "CANzero_SDO_Group" SG_ 1413 MLU_1_OD_CAN2_TxErrCnt "CAN";
BA_ "CANzero_SDO_AccessType" SG_ 1413 MLU_1_OD_CAN2_TxErrCnt 1;
BA_ "CANzero_SDO_AccessIfOperational" SG_ 1413 MLU_1_OD_CAN2_TxErrCnt 1;
BA_ "CANzero_SDO_Group" SG_ 1413 MLU_1_OD_CAN1_DelayedTxMessages "CAN";
BA_ "CANzero_SDO_AccessType" SG_ 1413 MLU_1_OD_CAN1_DelayedTxMessages 1;
BA_ "CANzero_SDO_AccessIfOperational" SG_ 1413 MLU_1_OD_CAN1_DelayedTxMessages 1;
BA_ "CANzero_SDO_Group" SG_ 1413 MLU_1_OD_CAN1_ErrorStatus "CAN";
BA_ "CANzero_SDO_AccessType" SG_ 1413 MLU_1_OD_CAN1_ErrorStatus 1;
BA_ "CANzero_SDO_AccessIfOperational" SG_ 1413 MLU_1_OD_CAN1_ErrorStatus 1;
BA_ "CANzero_SDO_Group" SG_ 1413 MLU_1_OD_CAN1_DiscardedTxMessage "CAN";
BA_ "CANzero_SDO_AccessType" SG_ 1413 MLU_1_OD_CAN1_DiscardedTxMessage 1;
BA_ "CANzero_SDO_AccessIfOperational" SG_ 1413 MLU_1_OD_CAN1_DiscardedTxMessage 1;
BA_ "SystemSignalLongSymbol" SG_ 1413 MLU_1_OD_CAN1_DiscardedTxMessage "MLU_1_OD_CAN1_DiscardedTxMessages";
BA_ "CANzero_SDO_Group" SG_ 1413 MLU_1_OD_CAN1_Status "CAN";
BA_ "CANzero_SDO_AccessType" SG_ 1413 MLU_1_OD_CAN1_Status 1;
BA_ "CANzero_SDO_AccessIfOperational" SG_ 1413 MLU_1_OD_CAN1_Status 1;
BA_ "CANzero_SDO_Group" SG_ 1413 MLU_1_OD_CAN1_Baudrate "CAN";
BA_ "CANzero_SDO_AccessIfOperational" SG_ 1413 MLU_1_OD_CAN1_Baudrate 1;
BA_ "GenSigStartValue" SG_ 1413 MLU_1_OD_CAN1_Baudrate 1000.0;
BA_ "CANzero_SDO_Default" SG_ 1413 MLU_1_OD_CAN1_Baudrate 1000;
BA_ "CANzero_SDO_Group" SG_ 1413 MLU_1_OD_CAN1_autoErrorReset "CAN";
BA_ "CANzero_SDO_AccessIfOperational" SG_ 1413 MLU_1_OD_CAN1_autoErrorReset 1;
BA_ "GenSigStartValue" SG_ 1413 MLU_1_OD_CAN1_autoErrorReset 1.0;
BA_ "CANzero_SDO_Default" SG_ 1413 MLU_1_OD_CAN1_autoErrorReset 1;
BA_ "CANzero_SDO_Group" SG_ 1413 MLU_1_OD_CAN1_lastErrorCode "CAN";
BA_ "CANzero_SDO_AccessType" SG_ 1413 MLU_1_OD_CAN1_lastErrorCode 1;
BA_ "CANzero_SDO_AccessIfOperational" SG_ 1413 MLU_1_OD_CAN1_lastErrorCode 1;
BA_ "CANzero_SDO_Group" SG_ 1413 MLU_1_OD_CAN1_RxErrCnt "CAN";
BA_ "CANzero_SDO_AccessType" SG_ 1413 MLU_1_OD_CAN1_RxErrCnt 1;
BA_ "CANzero_SDO_AccessIfOperational" SG_ 1413 MLU_1_OD_CAN1_RxErrCnt 1;
BA_ "CANzero_SDO_Group" SG_ 1413 MLU_1_OD_CAN1_TxErrCnt "CAN";
BA_ "CANzero_SDO_AccessType" SG_ 1413 MLU_1_OD_CAN1_TxErrCnt 1;
BA_ "CANzero_SDO_AccessIfOperational" SG_ 1413 MLU_1_OD_CAN1_TxErrCnt 1;
BA_ "CANzero_SDO_AccessType" SG_ 1413 MLU_1_OD_BuildTime 1;
BA_ "CANzero_SDO_AccessIfOperational" SG_ 1413 MLU_1_OD_BuildTime 1;
BA_ "CANzero_SDO_AccessType" SG_ 1413 MLU_1_OD_BuildDate 1;
BA_ "CANzero_SDO_AccessIfOperational" SG_ 1413 MLU_1_OD_BuildDate 1;
BA_ "CANzero_SDO_AccessType" SG_ 1413 MLU_1_OD_ChipUID2 1;
BA_ "CANzero_SDO_AccessIfOperational" SG_ 1413 MLU_1_OD_ChipUID2 1;
BA_ "CANzero_SDO_AccessType" SG_ 1413 MLU_1_OD_ChipUID1 1;
BA_ "CANzero_SDO_AccessIfOperational" SG_ 1413 MLU_1_OD_ChipUID1 1;
BA_ "CANzero_SDO_AccessType" SG_ 1413 MLU_1_OD_SdcOut 1;
BA_ "CANzero_SDO_AccessIfOperational" SG_ 1413 MLU_1_OD_SdcOut 1;
BA_ "CANzero_SDO_AccessType" SG_ 1413 MLU_1_OD_SdcIn 1;
BA_ "CANzero_SDO_AccessIfOperational" SG_ 1413 MLU_1_OD_SdcIn 1;
BA_ "CANzero_SDO_AccessType" SG_ 1413 MLU_1_OD_runtime 1;
BA_ "CANzero_SDO_AccessIfOperational" SG_ 1413 MLU_1_OD_runtime 1;
BA_ "CANzero_SDO_AccessType" SG_ 1413 MLU_1_OD_InputVoltage 1;
BA_ "CANzero_SDO_AccessIfOperational" SG_ 1413 MLU_1_OD_InputVoltage 1;
BA_ "CANzero_SDO_AccessType" SG_ 1413 MLU_1_OD_BoardTemp 1;
BA_ "CANzero_SDO_AccessIfOperational" SG_ 1413 MLU_1_OD_BoardTemp 1;
BA_ "GenSigStartValue" SG_ 1413 MLU_1_OD_BoardTemp 3000.0;
BA_ "CANzero_SDO_AccessType" SG_ 1413 MLU_1_OD_MemFree 1;
BA_ "CANzero_SDO_AccessIfOperational" SG_ 1413 MLU_1_OD_MemFree 1;
BA_ "CANzero_SDO_AccessType" SG_ 1413 MLU_1_OD_CpuUsage 1;
BA_ "CANzero_SDO_AccessIfOperational" SG_ 1413 MLU_1_OD_CpuUsage 1;
BA_ "CANzero_SDO_AccessIfOperational" SG_ 1413 MLU_1_OD_OdEntrySendInterval 1;
BA_ "GenSigStartValue" SG_ 1413 MLU_1_OD_OdEntrySendInterval 50.0;
BA_ "CANzero_SDO_Default" SG_ 1413 MLU_1_OD_OdEntrySendInterval 50;
BA_ "CANzero_SDO_AccessIfOperational" SG_ 1413 MLU_1_OD_SendOdOnBootup 1;
BA_ "CANzero_SDO_AccessIfOperational" SG_ 1413 MLU_1_OD_HeartbeatInterval 1;
BA_ "GenSigStartValue" SG_ 1413 MLU_1_OD_HeartbeatInterval 250.0;
BA_ "CANzero_SDO_Default" SG_ 1413 MLU_1_OD_HeartbeatInterval 250;
BA_ "CANzero_SDO_AccessType" SG_ 1413 MLU_1_OD_DbcVersion 1;
BA_ "CANzero_SDO_AccessIfOperational" SG_ 1413 MLU_1_OD_DbcVersion 1;
BA_ "CANzero_SDO_AccessType" SG_ 1413 MLU_1_OD_StackVersion 1;
BA_ "CANzero_SDO_AccessIfOperational" SG_ 1413 MLU_1_OD_StackVersion 1;
BA_ "CANzero_SDO_AccessType" SG_ 1413 MLU_1_OD_ProtocolVersion 1;
BA_ "CANzero_SDO_AccessIfOperational" SG_ 1413 MLU_1_OD_ProtocolVersion 1;
BA_ "GenSigStartValue" SG_ 1413 MLU_1_OD_ProtocolVersion 1.0;
BA_ "CANzero_SDO_Default" SG_ 1413 MLU_1_OD_ProtocolVersion 1;
BA_ "CANzero_SDO_AccessType" SG_ 1413 MLU_1_OD_NodeStatus 1;
BA_ "CANzero_SDO_AccessIfOperational" SG_ 1413 MLU_1_OD_NodeStatus 1;
BA_ "CANzero_SDO_AccessType" SG_ 1413 MLU_1_OD_NodeID 1;
BA_ "CANzero_SDO_AccessIfOperational" SG_ 1413 MLU_1_OD_NodeID 1;
BA_ "CANzero_SDO_Group" SG_ 1477 MLU_1_OD_CAN2_DelayedTxMessages "CAN";
BA_ "CANzero_SDO_AccessType" SG_ 1477 MLU_1_OD_CAN2_DelayedTxMessages 1;
BA_ "CANzero_SDO_AccessIfOperational" SG_ 1477 MLU_1_OD_CAN2_DelayedTxMessages 1;
BA_ "CANzero_SDO_Group" SG_ 1477 MLU_1_OD_CAN2_ErrorStatus "CAN";
BA_ "CANzero_SDO_AccessType" SG_ 1477 MLU_1_OD_CAN2_ErrorStatus 1;
BA_ "CANzero_SDO_AccessIfOperational" SG_ 1477 MLU_1_OD_CAN2_ErrorStatus 1;
BA_ "CANzero_SDO_Group" SG_ 1477 MLU_1_OD_CAN2_DiscardedTxMe_0000 "CAN";
BA_ "CANzero_SDO_AccessType" SG_ 1477 MLU_1_OD_CAN2_DiscardedTxMe_0000 1;
BA_ "CANzero_SDO_AccessIfOperational" SG_ 1477 MLU_1_OD_CAN2_DiscardedTxMe_0000 1;
BA_ "SystemSignalLongSymbol" SG_ 1477 MLU_1_OD_CAN2_DiscardedTxMe_0000 "MLU_1_OD_CAN2_DiscardedTxMessages";
BA_ "CANzero_SDO_Group" SG_ 1477 MLU_1_OD_CAN2_Status "CAN";
BA_ "CANzero_SDO_AccessType" SG_ 1477 MLU_1_OD_CAN2_Status 1;
BA_ "CANzero_SDO_AccessIfOperational" SG_ 1477 MLU_1_OD_CAN2_Status 1;
BA_ "CANzero_SDO_Group" SG_ 1477 MLU_1_OD_CAN2_Baudrate "CAN";
BA_ "CANzero_SDO_AccessIfOperational" SG_ 1477 MLU_1_OD_CAN2_Baudrate 1;
BA_ "GenSigStartValue" SG_ 1477 MLU_1_OD_CAN2_Baudrate 1000.0;
BA_ "CANzero_SDO_Default" SG_ 1477 MLU_1_OD_CAN2_Baudrate 1000;
BA_ "CANzero_SDO_Group" SG_ 1477 MLU_1_OD_CAN2_autoErrorReset "CAN";
BA_ "CANzero_SDO_AccessIfOperational" SG_ 1477 MLU_1_OD_CAN2_autoErrorReset 1;
BA_ "GenSigStartValue" SG_ 1477 MLU_1_OD_CAN2_autoErrorReset 1.0;
BA_ "CANzero_SDO_Default" SG_ 1477 MLU_1_OD_CAN2_autoErrorReset 1;
BA_ "CANzero_SDO_Group" SG_ 1477 MLU_1_OD_CAN2_lastErrorCode "CAN";
BA_ "CANzero_SDO_AccessType" SG_ 1477 MLU_1_OD_CAN2_lastErrorCode 1;
BA_ "CANzero_SDO_AccessIfOperational" SG_ 1477 MLU_1_OD_CAN2_lastErrorCode 1;
BA_ "CANzero_SDO_Group" SG_ 1477 MLU_1_OD_CAN2_RxErrCnt "CAN";
BA_ "CANzero_SDO_AccessType" SG_ 1477 MLU_1_OD_CAN2_RxErrCnt 1;
BA_ "CANzero_SDO_AccessIfOperational" SG_ 1477 MLU_1_OD_CAN2_RxErrCnt 1;
BA_ "CANzero_SDO_Group" SG_ 1477 MLU_1_OD_CAN2_TxErrCnt "CAN";
BA_ "CANzero_SDO_AccessType" SG_ 1477 MLU_1_OD_CAN2_TxErrCnt 1;
BA_ "CANzero_SDO_AccessIfOperational" SG_ 1477 MLU_1_OD_CAN2_TxErrCnt 1;
BA_ "CANzero_SDO_Group" SG_ 1477 MLU_1_OD_CAN1_DelayedTxMessages "CAN";
BA_ "CANzero_SDO_AccessType" SG_ 1477 MLU_1_OD_CAN1_DelayedTxMessages 1;
BA_ "CANzero_SDO_AccessIfOperational" SG_ 1477 MLU_1_OD_CAN1_DelayedTxMessages 1;
BA_ "CANzero_SDO_Group" SG_ 1477 MLU_1_OD_CAN1_ErrorStatus "CAN";
BA_ "CANzero_SDO_AccessType" SG_ 1477 MLU_1_OD_CAN1_ErrorStatus 1;
BA_ "CANzero_SDO_AccessIfOperational" SG_ 1477 MLU_1_OD_CAN1_ErrorStatus 1;
BA_ "CANzero_SDO_Group" SG_ 1477 MLU_1_OD_CAN1_DiscardedTxMe_0000 "CAN";
BA_ "CANzero_SDO_AccessType" SG_ 1477 MLU_1_OD_CAN1_DiscardedTxMe_0000 1;
BA_ "CANzero_SDO_AccessIfOperational" SG_ 1477 MLU_1_OD_CAN1_DiscardedTxMe_0000 1;
BA_ "SystemSignalLongSymbol" SG_ 1477 MLU_1_OD_CAN1_DiscardedTxMe_0000 "MLU_1_OD_CAN1_DiscardedTxMessages";
BA_ "CANzero_SDO_Group" SG_ 1477 MLU_1_OD_CAN1_Status "CAN";
BA_ "CANzero_SDO_AccessType" SG_ 1477 MLU_1_OD_CAN1_Status 1;
BA_ "CANzero_SDO_AccessIfOperational" SG_ 1477 MLU_1_OD_CAN1_Status 1;
BA_ "CANzero_SDO_Group" SG_ 1477 MLU_1_OD_CAN1_Baudrate "CAN";
BA_ "CANzero_SDO_AccessIfOperational" SG_ 1477 MLU_1_OD_CAN1_Baudrate 1;
BA_ "GenSigStartValue" SG_ 1477 MLU_1_OD_CAN1_Baudrate 1000.0;
BA_ "CANzero_SDO_Default" SG_ 1477 MLU_1_OD_CAN1_Baudrate 1000;
BA_ "CANzero_SDO_Group" SG_ 1477 MLU_1_OD_CAN1_autoErrorReset "CAN";
BA_ "CANzero_SDO_AccessIfOperational" SG_ 1477 MLU_1_OD_CAN1_autoErrorReset 1;
BA_ "GenSigStartValue" SG_ 1477 MLU_1_OD_CAN1_autoErrorReset 1.0;
BA_ "CANzero_SDO_Default" SG_ 1477 MLU_1_OD_CAN1_autoErrorReset 1;
BA_ "CANzero_SDO_Group" SG_ 1477 MLU_1_OD_CAN1_lastErrorCode "CAN";
BA_ "CANzero_SDO_AccessType" SG_ 1477 MLU_1_OD_CAN1_lastErrorCode 1;
BA_ "CANzero_SDO_AccessIfOperational" SG_ 1477 MLU_1_OD_CAN1_lastErrorCode 1;
BA_ "CANzero_SDO_Group" SG_ 1477 MLU_1_OD_CAN1_RxErrCnt "CAN";
BA_ "CANzero_SDO_AccessType" SG_ 1477 MLU_1_OD_CAN1_RxErrCnt 1;
BA_ "CANzero_SDO_AccessIfOperational" SG_ 1477 MLU_1_OD_CAN1_RxErrCnt 1;
BA_ "CANzero_SDO_Group" SG_ 1477 MLU_1_OD_CAN1_TxErrCnt "CAN";
BA_ "CANzero_SDO_AccessType" SG_ 1477 MLU_1_OD_CAN1_TxErrCnt 1;
BA_ "CANzero_SDO_AccessIfOperational" SG_ 1477 MLU_1_OD_CAN1_TxErrCnt 1;
BA_ "CANzero_SDO_AccessType" SG_ 1477 MLU_1_OD_BuildTime 1;
BA_ "CANzero_SDO_AccessIfOperational" SG_ 1477 MLU_1_OD_BuildTime 1;
BA_ "CANzero_SDO_AccessType" SG_ 1477 MLU_1_OD_BuildDate 1;
BA_ "CANzero_SDO_AccessIfOperational" SG_ 1477 MLU_1_OD_BuildDate 1;
BA_ "CANzero_SDO_AccessType" SG_ 1477 MLU_1_OD_ChipUID2 1;
BA_ "CANzero_SDO_AccessIfOperational" SG_ 1477 MLU_1_OD_ChipUID2 1;
BA_ "CANzero_SDO_AccessType" SG_ 1477 MLU_1_OD_ChipUID1 1;
BA_ "CANzero_SDO_AccessIfOperational" SG_ 1477 MLU_1_OD_ChipUID1 1;
BA_ "CANzero_SDO_AccessType" SG_ 1477 MLU_1_OD_SdcOut 1;
BA_ "CANzero_SDO_AccessIfOperational" SG_ 1477 MLU_1_OD_SdcOut 1;
BA_ "CANzero_SDO_AccessType" SG_ 1477 MLU_1_OD_SdcIn 1;
BA_ "CANzero_SDO_AccessIfOperational" SG_ 1477 MLU_1_OD_SdcIn 1;
BA_ "CANzero_SDO_AccessType" SG_ 1477 MLU_1_OD_runtime 1;
BA_ "CANzero_SDO_AccessIfOperational" SG_ 1477 MLU_1_OD_runtime 1;
BA_ "CANzero_SDO_AccessType" SG_ 1477 MLU_1_OD_InputVoltage 1;
BA_ "CANzero_SDO_AccessIfOperational" SG_ 1477 MLU_1_OD_InputVoltage 1;
BA_ "CANzero_SDO_AccessType" SG_ 1477 MLU_1_OD_BoardTemp 1;
BA_ "CANzero_SDO_AccessIfOperational" SG_ 1477 MLU_1_OD_BoardTemp 1;
BA_ "GenSigStartValue" SG_ 1477 MLU_1_OD_BoardTemp 3000.0;
BA_ "CANzero_SDO_AccessType" SG_ 1477 MLU_1_OD_MemFree 1;
BA_ "CANzero_SDO_AccessIfOperational" SG_ 1477 MLU_1_OD_MemFree 1;
BA_ "CANzero_SDO_AccessType" SG_ 1477 MLU_1_OD_CpuUsage 1;
BA_ "CANzero_SDO_AccessIfOperational" SG_ 1477 MLU_1_OD_CpuUsage 1;
BA_ "CANzero_SDO_AccessIfOperational" SG_ 1477 MLU_1_OD_OdEntrySendInterval 1;
BA_ "GenSigStartValue" SG_ 1477 MLU_1_OD_OdEntrySendInterval 50.0;
BA_ "CANzero_SDO_Default" SG_ 1477 MLU_1_OD_OdEntrySendInterval 50;
BA_ "CANzero_SDO_AccessIfOperational" SG_ 1477 MLU_1_OD_SendOdOnBootup 1;
BA_ "CANzero_SDO_AccessIfOperational" SG_ 1477 MLU_1_OD_HeartbeatInterval 1;
BA_ "GenSigStartValue" SG_ 1477 MLU_1_OD_HeartbeatInterval 250.0;
BA_ "CANzero_SDO_Default" SG_ 1477 MLU_1_OD_HeartbeatInterval 250;
BA_ "CANzero_SDO_AccessType" SG_ 1477 MLU_1_OD_DbcVersion 1;
BA_ "CANzero_SDO_AccessIfOperational" SG_ 1477 MLU_1_OD_DbcVersion 1;
BA_ "CANzero_SDO_AccessType" SG_ 1477 MLU_1_OD_StackVersion 1;
BA_ "CANzero_SDO_AccessIfOperational" SG_ 1477 MLU_1_OD_StackVersion 1;
BA_ "CANzero_SDO_AccessType" SG_ 1477 MLU_1_OD_ProtocolVersion 1;
BA_ "CANzero_SDO_AccessIfOperational" SG_ 1477 MLU_1_OD_ProtocolVersion 1;
BA_ "GenSigStartValue" SG_ 1477 MLU_1_OD_ProtocolVersion 1.0;
BA_ "CANzero_SDO_Default" SG_ 1477 MLU_1_OD_ProtocolVersion 1;
BA_ "CANzero_SDO_AccessType" SG_ 1477 MLU_1_OD_NodeStatus 1;
BA_ "CANzero_SDO_AccessIfOperational" SG_ 1477 MLU_1_OD_NodeStatus 1;
BA_ "CANzero_SDO_AccessType" SG_ 1477 MLU_1_OD_NodeID 1;
BA_ "CANzero_SDO_AccessIfOperational" SG_ 1477 MLU_1_OD_NodeID 1;
VAL_ 2 CANzero_NMT_Node 0 "All" 1 "SENSOR" 2 "PDU" 3 "CLU" 4 "BRAKE" 5 "MLU_1" 6 "MLU_2" 7 "MLU_3" 8 "MLU_4" 9 "MLU_5" 16 "MLU_6" ;
VAL_ 2 CANzero_NMT_State 1 "Start Remote Node" 2 "Stop Remote Node" 128 "Enter Pre-Operational" 129 "Reset" ;
VAL_ 129 SENSOR_E11_ANY_MLU_Timeout 0 "Ok" 1 "ERR" ;
VAL_ 129 SENSOR_E10_MLU6_Timeout 0 "Ok" 1 "ERR" ;
VAL_ 129 SENSOR_E9_MLU5_Timeout 0 "Ok" 1 "ERR" ;
VAL_ 129 SENSOR_E8_MLU4_Timeout 0 "Ok" 1 "ERR" ;
VAL_ 129 SENSOR_E7_MLU3_Timeout 0 "Ok" 1 "ERR" ;
VAL_ 129 SENSOR_E6_MLU2_Timeout 0 "Ok" 1 "ERR" ;
VAL_ 129 SENSOR_E5_MLU1_Timeout 0 "Ok" 1 "ERR" ;
VAL_ 129 SENSOR_E4_CLU_Timeout 0 "Ok" 1 "ERR" ;
VAL_ 129 SENSOR_E3_PDU_Timeout 0 "Ok" 1 "ERR" ;
VAL_ 129 SENSOR_E2_BRAKE_Timeout 0 "Ok" 1 "ERR" ;
VAL_ 129 SENSOR_E1_StateTransitionError 0 "Ok" 1 "ERR" ;
VAL_ 129 SENSOR_E0_OtherError 0 "Ok" 1 "ERR" ;
VAL_ 129 SENSOR_W4_PressureSensorPlausibi 0 "Ok" 1 "WARN" ;
VAL_ 129 SENSOR_W3_TemperaturSensorPlausi 0 "Ok" 1 "WARN" ;
VAL_ 129 SENSOR_W2_OnBoardOvervoltage 0 "Ok" 1 "WARN" ;
VAL_ 129 SENSOR_W1_OnBoardOverheat 0 "Ok" 1 "WARN" ;
VAL_ 129 SENSOR_W0_OtherWarning 0 "Ok" 1 "WARN" ;
VAL_ 1409 SENSOR_OD_CAN2_ErrorStatus 0 "Ok" 1 "Warn" 2 "Error Passive" 3 "Bus Off" ;
VAL_ 1409 SENSOR_OD_CAN2_Status 0 "Reset" 1 "Ready" 2 "Listening" 3 "Sleep_Pending" 4 "Sleep_Active" 5 "ERROR" ;
VAL_ 1409 SENSOR_OD_CAN2_autoErrorReset 0 "Disabled" 1 "Enabled" ;
VAL_ 1409 SENSOR_OD_CAN2_lastErrorCode 0 "No Error" 1 "Stuff Error" 2 "Form Error" 3 "Ack Error" 4 "Bit recessive Error" 5 "Bit dominant Error" 6 "CRC Error" ;
VAL_ 1409 SENSOR_OD_CAN1_ErrorStatus 0 "Ok" 1 "Warn" 2 "Error Passive" 3 "Bus Off" ;
VAL_ 1409 SENSOR_OD_CAN1_Status 0 "Reset" 1 "Ready" 2 "Listening" 3 "Sleep_Pending" 4 "Sleep_Active" 5 "ERROR" ;
VAL_ 1409 SENSOR_OD_CAN1_autoErrorReset 0 "Disabled" 1 "Enabled" ;
VAL_ 1409 SENSOR_OD_CAN1_lastErrorCode 0 "No Error" 1 "Stuff Error" 2 "Form Error" 3 "Ack Error" 4 "Bit recessive Error" 5 "Bit dominant Error" 6 "CRC Error" ;
VAL_ 1409 SENSOR_OD_SendOdOnBootup 0 "Disabled" 1 "Enabled" ;
VAL_ 1409 SENSOR_OD_NodeStatus 0 "Bootup" 4 "Stopped" 5 "Operational" 127 "Pre-Operational" 128 "Reset" ;
VAL_ 1409 SENSOR_SDO_RespCode 5 "ERR: Out of range" 4 "ERR: No access in this state" 3 "ERR: Read only object" 2 "ERR: Write only object" 1 "ERR: Non existing object" 0 "OK" ;
VAL_ 1409 SENSOR_SDO_ID 0 "Reserved" 1 "NodeID" 2 "NodeStatus" 3 "ProtocolVersion" 4 "StackVersion" 5 "DbcVersion" 16 "HeartbeatInterval" 32 "SendOdOnBootup" 33 "OdEntrySendInterval" 1040 "CpuUsage" 1041 "MemFree" 1042 "BoardTemp" 1043 "InputVoltage" 1044 "runtime" 1045 "SdcIn" 1046 "SdcOut" 1056 "ChipUID1" 1057 "ChipUID2" 1072 "BuildDate" 1073 "BuildTime" 1104 "CAN1_TxErrCnt" 1105 "CAN1_RxErrCnt" 1106 "CAN1_lastErrorCode" 1107 "CAN1_autoErrorReset" 1108 "CAN1_Baudrate" 1110 "CAN1_Status" 1111 "CAN1_DiscardedTxMessages" 1112 "CAN1_ErrorStatus" 1113 "CAN1_DelayedTxMessages" 1120 "CAN2_TxErrCnt" 1121 "CAN2_RxErrCnt" 1122 "CAN2_lastErrorCode" 1123 "CAN2_autoErrorReset" 1124 "CAN2_Baudrate" 1126 "CAN2_Status" 1127 "CAN2_DiscardedTxMessages" 1128 "CAN2_ErrorStatus" 1129 "CAN2_DelayedTxMessages" 2592 "IMU_number" 2597 "IMU1_Temperature" 2598 "IMU2_Temperature" 2599 "IMU3_Temperature" ;
VAL_ 1473 SENSOR_OD_CAN2_ErrorStatus 0 "Ok" 1 "Warn" 2 "Error Passive" 3 "Bus Off" ;
VAL_ 1473 SENSOR_OD_CAN2_Status 0 "Reset" 1 "Ready" 2 "Listening" 3 "Sleep_Pending" 4 "Sleep_Active" 5 "ERROR" ;
VAL_ 1473 SENSOR_OD_CAN2_autoErrorReset 0 "Disabled" 1 "Enabled" ;
VAL_ 1473 SENSOR_OD_CAN2_lastErrorCode 0 "No Error" 1 "Stuff Error" 2 "Form Error" 3 "Ack Error" 4 "Bit recessive Error" 5 "Bit dominant Error" 6 "CRC Error" ;
VAL_ 1473 SENSOR_OD_CAN1_ErrorStatus 0 "Ok" 1 "Warn" 2 "Error Passive" 3 "Bus Off" ;
VAL_ 1473 SENSOR_OD_CAN1_Status 0 "Reset" 1 "Ready" 2 "Listening" 3 "Sleep_Pending" 4 "Sleep_Active" 5 "ERROR" ;
VAL_ 1473 SENSOR_OD_CAN1_autoErrorReset 0 "Disabled" 1 "Enabled" ;
VAL_ 1473 SENSOR_OD_CAN1_lastErrorCode 0 "No Error" 1 "Stuff Error" 2 "Form Error" 3 "Ack Error" 4 "Bit recessive Error" 5 "Bit dominant Error" 6 "CRC Error" ;
VAL_ 1473 SENSOR_OD_SendOdOnBootup 0 "Disabled" 1 "Enabled" ;
VAL_ 1473 SENSOR_OD_NodeStatus 0 "Bootup" 4 "Stopped" 5 "Operational" 127 "Pre-Operational" 128 "Reset" ;
VAL_ 1473 SENSOR_SDO_ID 0 "Reserved" 1 "NodeID" 2 "NodeStatus" 3 "ProtocolVersion" 4 "StackVersion" 5 "DbcVersion" 16 "HeartbeatInterval" 32 "SendOdOnBootup" 33 "OdEntrySendInterval" 1040 "CpuUsage" 1041 "MemFree" 1042 "BoardTemp" 1043 "InputVoltage" 1044 "runtime" 1045 "SdcIn" 1046 "SdcOut" 1056 "ChipUID1" 1057 "ChipUID2" 1072 "BuildDate" 1073 "BuildTime" 1104 "CAN1_TxErrCnt" 1105 "CAN1_RxErrCnt" 1106 "CAN1_lastErrorCode" 1107 "CAN1_autoErrorReset" 1108 "CAN1_Baudrate" 1110 "CAN1_Status" 1111 "CAN1_DiscardedTxMessages" 1112 "CAN1_ErrorStatus" 1113 "CAN1_DelayedTxMessages" 1120 "CAN2_TxErrCnt" 1121 "CAN2_RxErrCnt" 1122 "CAN2_lastErrorCode" 1123 "CAN2_autoErrorReset" 1124 "CAN2_Baudrate" 1126 "CAN2_Status" 1127 "CAN2_DiscardedTxMessages" 1128 "CAN2_ErrorStatus" 1129 "CAN2_DelayedTxMessages" 2592 "IMU_number" 2597 "IMU1_Temperature" 2598 "IMU2_Temperature" 2599 "IMU3_Temperature" ;
VAL_ 1537 SENSOR_SDO_ID 0 "Reserved" 1 "NodeID" 2 "NodeStatus" 3 "ProtocolVersion" 4 "StackVersion" 5 "DbcVersion" 16 "HeartbeatInterval" 32 "SendOdOnBootup" 33 "OdEntrySendInterval" 1040 "CpuUsage" 1041 "MemFree" 1042 "BoardTemp" 1043 "InputVoltage" 1044 "runtime" 1045 "SdcIn" 1046 "SdcOut" 1056 "ChipUID1" 1057 "ChipUID2" 1072 "BuildDate" 1073 "BuildTime" 1104 "CAN1_TxErrCnt" 1105 "CAN1_RxErrCnt" 1106 "CAN1_lastErrorCode" 1107 "CAN1_autoErrorReset" 1108 "CAN1_Baudrate" 1110 "CAN1_Status" 1111 "CAN1_DiscardedTxMessages" 1112 "CAN1_ErrorStatus" 1113 "CAN1_DelayedTxMessages" 1120 "CAN2_TxErrCnt" 1121 "CAN2_RxErrCnt" 1122 "CAN2_lastErrorCode" 1123 "CAN2_autoErrorReset" 1124 "CAN2_Baudrate" 1126 "CAN2_Status" 1127 "CAN2_DiscardedTxMessages" 1128 "CAN2_ErrorStatus" 1129 "CAN2_DelayedTxMessages" 2592 "IMU_number" 2597 "IMU1_Temperature" 2598 "IMU2_Temperature" 2599 "IMU3_Temperature" ;
VAL_ 1793 SENSOR_NodeState 0 "Bootup" 4 "Stopped" 5 "Operational" 127 "Pre-Operational" ;
VAL_ 130 PDU_E4_watchdogStateMachine 0 "Ok" 1 "ERR" ;
VAL_ 130 PDU_E3_batterTempCritical 0 "Ok" 1 "ERR" ;
VAL_ 130 PDU_E2_batteryOvercurrent 0 "Ok" 1 "ERR" ;
VAL_ 130 PDU_E1_batterVoltageCritical 0 "Ok" 1 "ERR" ;
VAL_ 130 PDU_E0_OtherError 0 "Ok" 1 "ERR" ;
VAL_ 130 PDU_W2_batterTempHigh 0 "Ok" 1 "WARN" ;
VAL_ 130 PDU_W1_batterVoltageLow 0 "Ok" 1 "WARN" ;
VAL_ 130 PDU_W0_OtherWarning 0 "Ok" 1 "WARN" ;
VAL_ 1410 PDU_OD_CoolingPumpEnabled 0 "Disable" 1 "Enable" ;
VAL_ 1410 PDU_OD_LedCommands 0 "None" 1 "whipeanimation" 2 "mugreenanimation" 3 "rainbowanimation" 4 "flashlights" 5 "snakeanimation" 6 "blinkpink" 7 "multiwhipe" 8 "Emergency" ;
VAL_ 1410 PDU_OD_projectXXEnabled 0 "Disable" 1 "Enable" ;
VAL_ 1410 PDU_OD_CAN2_ErrorStatus 0 "Ok" 1 "Warn" 2 "Error Passive" 3 "Bus Off" ;
VAL_ 1410 PDU_OD_CAN2_Status 0 "Reset" 1 "Ready" 2 "Listening" 3 "Sleep_Pending" 4 "Sleep_Active" 5 "ERROR" ;
VAL_ 1410 PDU_OD_CAN2_autoErrorReset 0 "Disabled" 1 "Enabled" ;
VAL_ 1410 PDU_OD_CAN2_lastErrorCode 0 "No Error" 1 "Stuff Error" 2 "Form Error" 3 "Ack Error" 4 "Bit recessive Error" 5 "Bit dominant Error" 6 "CRC Error" ;
VAL_ 1410 PDU_OD_CAN1_ErrorStatus 0 "Ok" 1 "Warn" 2 "Error Passive" 3 "Bus Off" ;
VAL_ 1410 PDU_OD_CAN1_Status 0 "Reset" 1 "Ready" 2 "Listening" 3 "Sleep_Pending" 4 "Sleep_Active" 5 "ERROR" ;
VAL_ 1410 PDU_OD_CAN1_autoErrorReset 0 "Disabled" 1 "Enabled" ;
VAL_ 1410 PDU_OD_CAN1_lastErrorCode 0 "No Error" 1 "Stuff Error" 2 "Form Error" 3 "Ack Error" 4 "Bit recessive Error" 5 "Bit dominant Error" 6 "CRC Error" ;
VAL_ 1410 PDU_OD_SendOdOnBootup 0 "Disabled" 1 "Enabled" ;
VAL_ 1410 PDU_OD_NodeStatus 0 "Bootup" 4 "Stopped" 5 "Operational" 127 "Pre-Operational" 128 "Reset" ;
VAL_ 1410 PDU_SDO_RespCode 5 "ERR: Out of range" 4 "ERR: No access in this state" 3 "ERR: Read only object" 2 "ERR: Write only object" 1 "ERR: Non existing object" 0 "OK" ;
VAL_ 1410 PDU_SDO_ID 0 "Reserved" 1 "NodeID" 2 "NodeStatus" 3 "ProtocolVersion" 4 "StackVersion" 5 "DbcVersion" 16 "HeartbeatInterval" 32 "SendOdOnBootup" 33 "OdEntrySendInterval" 1040 "CpuUsage" 1041 "MemFree" 1042 "BoardTemp" 1043 "InputVoltage" 1044 "runtime" 1045 "SdcIn" 1046 "SdcOut" 1056 "ChipUID1" 1057 "ChipUID2" 1072 "BuildDate" 1073 "BuildTime" 1104 "CAN1_TxErrCnt" 1105 "CAN1_RxErrCnt" 1106 "CAN1_lastErrorCode" 1107 "CAN1_autoErrorReset" 1108 "CAN1_Baudrate" 1110 "CAN1_Status" 1111 "CAN1_DiscardedTxMessages" 1112 "CAN1_ErrorStatus" 1113 "CAN1_DelayedTxMessages" 1120 "CAN2_TxErrCnt" 1121 "CAN2_RxErrCnt" 1122 "CAN2_lastErrorCode" 1123 "CAN2_autoErrorReset" 1124 "CAN2_Baudrate" 1126 "CAN2_Status" 1127 "CAN2_DiscardedTxMessages" 1128 "CAN2_ErrorStatus" 1129 "CAN2_DelayedTxMessages" 2048 "batterVoltageLow" 2049 "batterVoltageCritical" 2050 "overTempWarn" 2051 "overTempCritical" 2128 "batteryOvercurrent" 2304 "currentReadInterval" 2305 "statusSendInterval" 2306 "watchdogTimeout" 2560 "projectXXEnabled" 2562 "LedCommands" 2816 "CoolingPumpEnabled" ;
VAL_ 1474 PDU_OD_CoolingPumpEnabled 0 "Disable" 1 "Enable" ;
VAL_ 1474 PDU_OD_LedCommands 0 "None" 1 "whipeanimation" 2 "mugreenanimation" 3 "rainbowanimation" 4 "flashlights" 5 "snakeanimation" 6 "blinkpink" 7 "multiwhipe" 8 "Emergency" ;
VAL_ 1474 PDU_OD_projectXXEnabled 0 "Disable" 1 "Enable" ;
VAL_ 1474 PDU_OD_CAN2_ErrorStatus 0 "Ok" 1 "Warn" 2 "Error Passive" 3 "Bus Off" ;
VAL_ 1474 PDU_OD_CAN2_Status 0 "Reset" 1 "Ready" 2 "Listening" 3 "Sleep_Pending" 4 "Sleep_Active" 5 "ERROR" ;
VAL_ 1474 PDU_OD_CAN2_autoErrorReset 0 "Disabled" 1 "Enabled" ;
VAL_ 1474 PDU_OD_CAN2_lastErrorCode 0 "No Error" 1 "Stuff Error" 2 "Form Error" 3 "Ack Error" 4 "Bit recessive Error" 5 "Bit dominant Error" 6 "CRC Error" ;
VAL_ 1474 PDU_OD_CAN1_ErrorStatus 0 "Ok" 1 "Warn" 2 "Error Passive" 3 "Bus Off" ;
VAL_ 1474 PDU_OD_CAN1_Status 0 "Reset" 1 "Ready" 2 "Listening" 3 "Sleep_Pending" 4 "Sleep_Active" 5 "ERROR" ;
VAL_ 1474 PDU_OD_CAN1_autoErrorReset 0 "Disabled" 1 "Enabled" ;
VAL_ 1474 PDU_OD_CAN1_lastErrorCode 0 "No Error" 1 "Stuff Error" 2 "Form Error" 3 "Ack Error" 4 "Bit recessive Error" 5 "Bit dominant Error" 6 "CRC Error" ;
VAL_ 1474 PDU_OD_SendOdOnBootup 0 "Disabled" 1 "Enabled" ;
VAL_ 1474 PDU_OD_NodeStatus 0 "Bootup" 4 "Stopped" 5 "Operational" 127 "Pre-Operational" 128 "Reset" ;
VAL_ 1474 PDU_SDO_ID 0 "Reserved" 1 "NodeID" 2 "NodeStatus" 3 "ProtocolVersion" 4 "StackVersion" 5 "DbcVersion" 16 "HeartbeatInterval" 32 "SendOdOnBootup" 33 "OdEntrySendInterval" 1040 "CpuUsage" 1041 "MemFree" 1042 "BoardTemp" 1043 "InputVoltage" 1044 "runtime" 1045 "SdcIn" 1046 "SdcOut" 1056 "ChipUID1" 1057 "ChipUID2" 1072 "BuildDate" 1073 "BuildTime" 1104 "CAN1_TxErrCnt" 1105 "CAN1_RxErrCnt" 1106 "CAN1_lastErrorCode" 1107 "CAN1_autoErrorReset" 1108 "CAN1_Baudrate" 1110 "CAN1_Status" 1111 "CAN1_DiscardedTxMessages" 1112 "CAN1_ErrorStatus" 1113 "CAN1_DelayedTxMessages" 1120 "CAN2_TxErrCnt" 1121 "CAN2_RxErrCnt" 1122 "CAN2_lastErrorCode" 1123 "CAN2_autoErrorReset" 1124 "CAN2_Baudrate" 1126 "CAN2_Status" 1127 "CAN2_DiscardedTxMessages" 1128 "CAN2_ErrorStatus" 1129 "CAN2_DelayedTxMessages" 2048 "batterVoltageLow" 2049 "batterVoltageCritical" 2050 "overTempWarn" 2051 "overTempCritical" 2128 "batteryOvercurrent" 2304 "currentReadInterval" 2305 "statusSendInterval" 2306 "watchdogTimeout" 2560 "projectXXEnabled" 2562 "LedCommands" 2816 "CoolingPumpEnabled" ;
VAL_ 1538 PDU_SDO_ID 0 "Reserved" 1 "NodeID" 2 "NodeStatus" 3 "ProtocolVersion" 4 "StackVersion" 5 "DbcVersion" 16 "HeartbeatInterval" 32 "SendOdOnBootup" 33 "OdEntrySendInterval" 1040 "CpuUsage" 1041 "MemFree" 1042 "BoardTemp" 1043 "InputVoltage" 1044 "runtime" 1045 "SdcIn" 1046 "SdcOut" 1056 "ChipUID1" 1057 "ChipUID2" 1072 "BuildDate" 1073 "BuildTime" 1104 "CAN1_TxErrCnt" 1105 "CAN1_RxErrCnt" 1106 "CAN1_lastErrorCode" 1107 "CAN1_autoErrorReset" 1108 "CAN1_Baudrate" 1110 "CAN1_Status" 1111 "CAN1_DiscardedTxMessages" 1112 "CAN1_ErrorStatus" 1113 "CAN1_DelayedTxMessages" 1120 "CAN2_TxErrCnt" 1121 "CAN2_RxErrCnt" 1122 "CAN2_lastErrorCode" 1123 "CAN2_autoErrorReset" 1124 "CAN2_Baudrate" 1126 "CAN2_Status" 1127 "CAN2_DiscardedTxMessages" 1128 "CAN2_ErrorStatus" 1129 "CAN2_DelayedTxMessages" 2048 "batterVoltageLow" 2049 "batterVoltageCritical" 2050 "overTempWarn" 2051 "overTempCritical" 2128 "batteryOvercurrent" 2304 "currentReadInterval" 2305 "statusSendInterval" 2306 "watchdogTimeout" 2560 "projectXXEnabled" 2562 "LedCommands" 2816 "CoolingPumpEnabled" ;
VAL_ 1794 PDU_NodeState 0 "Bootup" 4 "Stopped" 5 "Operational" 127 "Pre-Operational" ;
VAL_ 131 CLU_E0_OtherError 0 "Ok" 1 "ERR" ;
VAL_ 131 CLU_W0_OtherWarning 0 "Ok" 1 "WARN" ;
VAL_ 1411 CLU_OD_CAN2_ErrorStatus 0 "Ok" 1 "Warn" 2 "Error Passive" 3 "Bus Off" ;
VAL_ 1411 CLU_OD_CAN2_Status 0 "Reset" 1 "Ready" 2 "Listening" 3 "Sleep_Pending" 4 "Sleep_Active" 5 "ERROR" ;
VAL_ 1411 CLU_OD_CAN2_autoErrorReset 0 "Disabled" 1 "Enabled" ;
VAL_ 1411 CLU_OD_CAN2_lastErrorCode 0 "No Error" 1 "Stuff Error" 2 "Form Error" 3 "Ack Error" 4 "Bit recessive Error" 5 "Bit dominant Error" 6 "CRC Error" ;
VAL_ 1411 CLU_OD_CAN1_ErrorStatus 0 "Ok" 1 "Warn" 2 "Error Passive" 3 "Bus Off" ;
VAL_ 1411 CLU_OD_CAN1_Status 0 "Reset" 1 "Ready" 2 "Listening" 3 "Sleep_Pending" 4 "Sleep_Active" 5 "ERROR" ;
VAL_ 1411 CLU_OD_CAN1_autoErrorReset 0 "Disabled" 1 "Enabled" ;
VAL_ 1411 CLU_OD_CAN1_lastErrorCode 0 "No Error" 1 "Stuff Error" 2 "Form Error" 3 "Ack Error" 4 "Bit recessive Error" 5 "Bit dominant Error" 6 "CRC Error" ;
VAL_ 1411 CLU_OD_SendOdOnBootup 0 "Disabled" 1 "Enabled" ;
VAL_ 1411 CLU_OD_NodeStatus 0 "Bootup" 4 "Stopped" 5 "Operational" 127 "Pre-Operational" 128 "Reset" ;
VAL_ 1411 CLU_SDO_RespCode 5 "ERR: Out of range" 4 "ERR: No access in this state" 3 "ERR: Read only object" 2 "ERR: Write only object" 1 "ERR: Non existing object" 0 "OK" ;
VAL_ 1411 CLU_SDO_ID 0 "Reserved" 1 "NodeID" 2 "NodeStatus" 3 "ProtocolVersion" 4 "StackVersion" 5 "DbcVersion" 16 "HeartbeatInterval" 32 "SendOdOnBootup" 33 "OdEntrySendInterval" 1040 "CpuUsage" 1041 "MemFree" 1042 "BoardTemp" 1043 "InputVoltage" 1044 "runtime" 1045 "SdcIn" 1046 "SdcOut" 1056 "ChipUID1" 1057 "ChipUID2" 1072 "BuildDate" 1073 "BuildTime" 1104 "CAN1_TxErrCnt" 1105 "CAN1_RxErrCnt" 1106 "CAN1_lastErrorCode" 1107 "CAN1_autoErrorReset" 1108 "CAN1_Baudrate" 1110 "CAN1_Status" 1111 "CAN1_DiscardedTxMessages" 1112 "CAN1_ErrorStatus" 1113 "CAN1_DelayedTxMessages" 1120 "CAN2_TxErrCnt" 1121 "CAN2_RxErrCnt" 1122 "CAN2_lastErrorCode" 1123 "CAN2_autoErrorReset" 1124 "CAN2_Baudrate" 1126 "CAN2_Status" 1127 "CAN2_DiscardedTxMessages" 1128 "CAN2_ErrorStatus" 1129 "CAN2_DelayedTxMessages" ;
VAL_ 1475 CLU_OD_CAN2_ErrorStatus 0 "Ok" 1 "Warn" 2 "Error Passive" 3 "Bus Off" ;
VAL_ 1475 CLU_OD_CAN2_Status 0 "Reset" 1 "Ready" 2 "Listening" 3 "Sleep_Pending" 4 "Sleep_Active" 5 "ERROR" ;
VAL_ 1475 CLU_OD_CAN2_autoErrorReset 0 "Disabled" 1 "Enabled" ;
VAL_ 1475 CLU_OD_CAN2_lastErrorCode 0 "No Error" 1 "Stuff Error" 2 "Form Error" 3 "Ack Error" 4 "Bit recessive Error" 5 "Bit dominant Error" 6 "CRC Error" ;
VAL_ 1475 CLU_OD_CAN1_ErrorStatus 0 "Ok" 1 "Warn" 2 "Error Passive" 3 "Bus Off" ;
VAL_ 1475 CLU_OD_CAN1_Status 0 "Reset" 1 "Ready" 2 "Listening" 3 "Sleep_Pending" 4 "Sleep_Active" 5 "ERROR" ;
VAL_ 1475 CLU_OD_CAN1_autoErrorReset 0 "Disabled" 1 "Enabled" ;
VAL_ 1475 CLU_OD_CAN1_lastErrorCode 0 "No Error" 1 "Stuff Error" 2 "Form Error" 3 "Ack Error" 4 "Bit recessive Error" 5 "Bit dominant Error" 6 "CRC Error" ;
VAL_ 1475 CLU_OD_SendOdOnBootup 0 "Disabled" 1 "Enabled" ;
VAL_ 1475 CLU_OD_NodeStatus 0 "Bootup" 4 "Stopped" 5 "Operational" 127 "Pre-Operational" 128 "Reset" ;
VAL_ 1475 CLU_SDO_ID 0 "Reserved" 1 "NodeID" 2 "NodeStatus" 3 "ProtocolVersion" 4 "StackVersion" 5 "DbcVersion" 16 "HeartbeatInterval" 32 "SendOdOnBootup" 33 "OdEntrySendInterval" 1040 "CpuUsage" 1041 "MemFree" 1042 "BoardTemp" 1043 "InputVoltage" 1044 "runtime" 1045 "SdcIn" 1046 "SdcOut" 1056 "ChipUID1" 1057 "ChipUID2" 1072 "BuildDate" 1073 "BuildTime" 1104 "CAN1_TxErrCnt" 1105 "CAN1_RxErrCnt" 1106 "CAN1_lastErrorCode" 1107 "CAN1_autoErrorReset" 1108 "CAN1_Baudrate" 1110 "CAN1_Status" 1111 "CAN1_DiscardedTxMessages" 1112 "CAN1_ErrorStatus" 1113 "CAN1_DelayedTxMessages" 1120 "CAN2_TxErrCnt" 1121 "CAN2_RxErrCnt" 1122 "CAN2_lastErrorCode" 1123 "CAN2_autoErrorReset" 1124 "CAN2_Baudrate" 1126 "CAN2_Status" 1127 "CAN2_DiscardedTxMessages" 1128 "CAN2_ErrorStatus" 1129 "CAN2_DelayedTxMessages" ;
VAL_ 1539 CLU_SDO_ID 0 "Reserved" 1 "NodeID" 2 "NodeStatus" 3 "ProtocolVersion" 4 "StackVersion" 5 "DbcVersion" 16 "HeartbeatInterval" 32 "SendOdOnBootup" 33 "OdEntrySendInterval" 1040 "CpuUsage" 1041 "MemFree" 1042 "BoardTemp" 1043 "InputVoltage" 1044 "runtime" 1045 "SdcIn" 1046 "SdcOut" 1056 "ChipUID1" 1057 "ChipUID2" 1072 "BuildDate" 1073 "BuildTime" 1104 "CAN1_TxErrCnt" 1105 "CAN1_RxErrCnt" 1106 "CAN1_lastErrorCode" 1107 "CAN1_autoErrorReset" 1108 "CAN1_Baudrate" 1110 "CAN1_Status" 1111 "CAN1_DiscardedTxMessages" 1112 "CAN1_ErrorStatus" 1113 "CAN1_DelayedTxMessages" 1120 "CAN2_TxErrCnt" 1121 "CAN2_RxErrCnt" 1122 "CAN2_lastErrorCode" 1123 "CAN2_autoErrorReset" 1124 "CAN2_Baudrate" 1126 "CAN2_Status" 1127 "CAN2_DiscardedTxMessages" 1128 "CAN2_ErrorStatus" 1129 "CAN2_DelayedTxMessages" ;
VAL_ 1795 CLU_NodeState 0 "Bootup" 4 "Stopped" 5 "Operational" 127 "Pre-Operational" ;
VAL_ 132 BRAKE_E0_OtherError 0 "Ok" 1 "ERR" ;
VAL_ 132 BRAKE_W0_OtherWarning 0 "Ok" 1 "WARN" ;
VAL_ 1412 BRAKE_OD_CAN2_ErrorStatus 0 "Ok" 1 "Warn" 2 "Error Passive" 3 "Bus Off" ;
VAL_ 1412 BRAKE_OD_CAN2_Status 0 "Reset" 1 "Ready" 2 "Listening" 3 "Sleep_Pending" 4 "Sleep_Active" 5 "ERROR" ;
VAL_ 1412 BRAKE_OD_CAN2_autoErrorReset 0 "Disabled" 1 "Enabled" ;
VAL_ 1412 BRAKE_OD_CAN2_lastErrorCode 0 "No Error" 1 "Stuff Error" 2 "Form Error" 3 "Ack Error" 4 "Bit recessive Error" 5 "Bit dominant Error" 6 "CRC Error" ;
VAL_ 1412 BRAKE_OD_CAN1_ErrorStatus 0 "Ok" 1 "Warn" 2 "Error Passive" 3 "Bus Off" ;
VAL_ 1412 BRAKE_OD_CAN1_Status 0 "Reset" 1 "Ready" 2 "Listening" 3 "Sleep_Pending" 4 "Sleep_Active" 5 "ERROR" ;
VAL_ 1412 BRAKE_OD_CAN1_autoErrorReset 0 "Disabled" 1 "Enabled" ;
VAL_ 1412 BRAKE_OD_CAN1_lastErrorCode 0 "No Error" 1 "Stuff Error" 2 "Form Error" 3 "Ack Error" 4 "Bit recessive Error" 5 "Bit dominant Error" 6 "CRC Error" ;
VAL_ 1412 BRAKE_OD_SendOdOnBootup 0 "Disabled" 1 "Enabled" ;
VAL_ 1412 BRAKE_OD_NodeStatus 0 "Bootup" 4 "Stopped" 5 "Operational" 127 "Pre-Operational" 128 "Reset" ;
VAL_ 1412 BRAKE_SDO_RespCode 5 "ERR: Out of range" 4 "ERR: No access in this state" 3 "ERR: Read only object" 2 "ERR: Write only object" 1 "ERR: Non existing object" 0 "OK" ;
VAL_ 1412 BRAKE_SDO_ID 0 "Reserved" 1 "NodeID" 2 "NodeStatus" 3 "ProtocolVersion" 4 "StackVersion" 5 "DbcVersion" 16 "HeartbeatInterval" 32 "SendOdOnBootup" 33 "OdEntrySendInterval" 1040 "CpuUsage" 1041 "MemFree" 1042 "BoardTemp" 1043 "InputVoltage" 1044 "runtime" 1045 "SdcIn" 1046 "SdcOut" 1056 "ChipUID1" 1057 "ChipUID2" 1072 "BuildDate" 1073 "BuildTime" 1104 "CAN1_TxErrCnt" 1105 "CAN1_RxErrCnt" 1106 "CAN1_lastErrorCode" 1107 "CAN1_autoErrorReset" 1108 "CAN1_Baudrate" 1110 "CAN1_Status" 1111 "CAN1_DiscardedTxMessages" 1112 "CAN1_ErrorStatus" 1113 "CAN1_DelayedTxMessages" 1120 "CAN2_TxErrCnt" 1121 "CAN2_RxErrCnt" 1122 "CAN2_lastErrorCode" 1123 "CAN2_autoErrorReset" 1124 "CAN2_Baudrate" 1126 "CAN2_Status" 1127 "CAN2_DiscardedTxMessages" 1128 "CAN2_ErrorStatus" 1129 "CAN2_DelayedTxMessages" ;
VAL_ 1476 BRAKE_OD_CAN2_ErrorStatus 0 "Ok" 1 "Warn" 2 "Error Passive" 3 "Bus Off" ;
VAL_ 1476 BRAKE_OD_CAN2_Status 0 "Reset" 1 "Ready" 2 "Listening" 3 "Sleep_Pending" 4 "Sleep_Active" 5 "ERROR" ;
VAL_ 1476 BRAKE_OD_CAN2_autoErrorReset 0 "Disabled" 1 "Enabled" ;
VAL_ 1476 BRAKE_OD_CAN2_lastErrorCode 0 "No Error" 1 "Stuff Error" 2 "Form Error" 3 "Ack Error" 4 "Bit recessive Error" 5 "Bit dominant Error" 6 "CRC Error" ;
VAL_ 1476 BRAKE_OD_CAN1_ErrorStatus 0 "Ok" 1 "Warn" 2 "Error Passive" 3 "Bus Off" ;
VAL_ 1476 BRAKE_OD_CAN1_Status 0 "Reset" 1 "Ready" 2 "Listening" 3 "Sleep_Pending" 4 "Sleep_Active" 5 "ERROR" ;
VAL_ 1476 BRAKE_OD_CAN1_autoErrorReset 0 "Disabled" 1 "Enabled" ;
VAL_ 1476 BRAKE_OD_CAN1_lastErrorCode 0 "No Error" 1 "Stuff Error" 2 "Form Error" 3 "Ack Error" 4 "Bit recessive Error" 5 "Bit dominant Error" 6 "CRC Error" ;
VAL_ 1476 BRAKE_OD_SendOdOnBootup 0 "Disabled" 1 "Enabled" ;
VAL_ 1476 BRAKE_OD_NodeStatus 0 "Bootup" 4 "Stopped" 5 "Operational" 127 "Pre-Operational" 128 "Reset" ;
VAL_ 1476 BRAKE_SDO_ID 0 "Reserved" 1 "NodeID" 2 "NodeStatus" 3 "ProtocolVersion" 4 "StackVersion" 5 "DbcVersion" 16 "HeartbeatInterval" 32 "SendOdOnBootup" 33 "OdEntrySendInterval" 1040 "CpuUsage" 1041 "MemFree" 1042 "BoardTemp" 1043 "InputVoltage" 1044 "runtime" 1045 "SdcIn" 1046 "SdcOut" 1056 "ChipUID1" 1057 "ChipUID2" 1072 "BuildDate" 1073 "BuildTime" 1104 "CAN1_TxErrCnt" 1105 "CAN1_RxErrCnt" 1106 "CAN1_lastErrorCode" 1107 "CAN1_autoErrorReset" 1108 "CAN1_Baudrate" 1110 "CAN1_Status" 1111 "CAN1_DiscardedTxMessages" 1112 "CAN1_ErrorStatus" 1113 "CAN1_DelayedTxMessages" 1120 "CAN2_TxErrCnt" 1121 "CAN2_RxErrCnt" 1122 "CAN2_lastErrorCode" 1123 "CAN2_autoErrorReset" 1124 "CAN2_Baudrate" 1126 "CAN2_Status" 1127 "CAN2_DiscardedTxMessages" 1128 "CAN2_ErrorStatus" 1129 "CAN2_DelayedTxMessages" ;
VAL_ 1540 BRAKE_SDO_ID 0 "Reserved" 1 "NodeID" 2 "NodeStatus" 3 "ProtocolVersion" 4 "StackVersion" 5 "DbcVersion" 16 "HeartbeatInterval" 32 "SendOdOnBootup" 33 "OdEntrySendInterval" 1040 "CpuUsage" 1041 "MemFree" 1042 "BoardTemp" 1043 "InputVoltage" 1044 "runtime" 1045 "SdcIn" 1046 "SdcOut" 1056 "ChipUID1" 1057 "ChipUID2" 1072 "BuildDate" 1073 "BuildTime" 1104 "CAN1_TxErrCnt" 1105 "CAN1_RxErrCnt" 1106 "CAN1_lastErrorCode" 1107 "CAN1_autoErrorReset" 1108 "CAN1_Baudrate" 1110 "CAN1_Status" 1111 "CAN1_DiscardedTxMessages" 1112 "CAN1_ErrorStatus" 1113 "CAN1_DelayedTxMessages" 1120 "CAN2_TxErrCnt" 1121 "CAN2_RxErrCnt" 1122 "CAN2_lastErrorCode" 1123 "CAN2_autoErrorReset" 1124 "CAN2_Baudrate" 1126 "CAN2_Status" 1127 "CAN2_DiscardedTxMessages" 1128 "CAN2_ErrorStatus" 1129 "CAN2_DelayedTxMessages" ;
VAL_ 1796 BRAKE_NodeState 0 "Bootup" 4 "Stopped" 5 "Operational" 127 "Pre-Operational" ;
VAL_ 133 MLU_1_E0_OtherError 0 "Ok" 1 "ERR" ;
VAL_ 133 MLU_1_W0_OtherWarning 0 "Ok" 1 "WARN" ;
VAL_ 1413 MLU_1_OD_CAN2_ErrorStatus 0 "Ok" 1 "Warn" 2 "Error Passive" 3 "Bus Off" ;
VAL_ 1413 MLU_1_OD_CAN2_Status 0 "Reset" 1 "Ready" 2 "Listening" 3 "Sleep_Pending" 4 "Sleep_Active" 5 "ERROR" ;
VAL_ 1413 MLU_1_OD_CAN2_autoErrorReset 0 "Disabled" 1 "Enabled" ;
VAL_ 1413 MLU_1_OD_CAN2_lastErrorCode 0 "No Error" 1 "Stuff Error" 2 "Form Error" 3 "Ack Error" 4 "Bit recessive Error" 5 "Bit dominant Error" 6 "CRC Error" ;
VAL_ 1413 MLU_1_OD_CAN1_ErrorStatus 0 "Ok" 1 "Warn" 2 "Error Passive" 3 "Bus Off" ;
VAL_ 1413 MLU_1_OD_CAN1_Status 0 "Reset" 1 "Ready" 2 "Listening" 3 "Sleep_Pending" 4 "Sleep_Active" 5 "ERROR" ;
VAL_ 1413 MLU_1_OD_CAN1_autoErrorReset 0 "Disabled" 1 "Enabled" ;
VAL_ 1413 MLU_1_OD_CAN1_lastErrorCode 0 "No Error" 1 "Stuff Error" 2 "Form Error" 3 "Ack Error" 4 "Bit recessive Error" 5 "Bit dominant Error" 6 "CRC Error" ;
VAL_ 1413 MLU_1_OD_SendOdOnBootup 0 "Disabled" 1 "Enabled" ;
VAL_ 1413 MLU_1_OD_NodeStatus 0 "Bootup" 4 "Stopped" 5 "Operational" 127 "Pre-Operational" 128 "Reset" ;
VAL_ 1413 MLU_1_SDO_RespCode 5 "ERR: Out of range" 4 "ERR: No access in this state" 3 "ERR: Read only object" 2 "ERR: Write only object" 1 "ERR: Non existing object" 0 "OK" ;
VAL_ 1413 MLU_1_SDO_ID 0 "Reserved" 1 "NodeID" 2 "NodeStatus" 3 "ProtocolVersion" 4 "StackVersion" 5 "DbcVersion" 16 "HeartbeatInterval" 32 "SendOdOnBootup" 33 "OdEntrySendInterval" 1040 "CpuUsage" 1041 "MemFree" 1042 "BoardTemp" 1043 "InputVoltage" 1044 "runtime" 1045 "SdcIn" 1046 "SdcOut" 1056 "ChipUID1" 1057 "ChipUID2" 1072 "BuildDate" 1073 "BuildTime" 1104 "CAN1_TxErrCnt" 1105 "CAN1_RxErrCnt" 1106 "CAN1_lastErrorCode" 1107 "CAN1_autoErrorReset" 1108 "CAN1_Baudrate" 1110 "CAN1_Status" 1111 "CAN1_DiscardedTxMessages" 1112 "CAN1_ErrorStatus" 1113 "CAN1_DelayedTxMessages" 1120 "CAN2_TxErrCnt" 1121 "CAN2_RxErrCnt" 1122 "CAN2_lastErrorCode" 1123 "CAN2_autoErrorReset" 1124 "CAN2_Baudrate" 1126 "CAN2_Status" 1127 "CAN2_DiscardedTxMessages" 1128 "CAN2_ErrorStatus" 1129 "CAN2_DelayedTxMessages" ;
VAL_ 1477 MLU_1_OD_CAN2_ErrorStatus 0 "Ok" 1 "Warn" 2 "Error Passive" 3 "Bus Off" ;
VAL_ 1477 MLU_1_OD_CAN2_Status 0 "Reset" 1 "Ready" 2 "Listening" 3 "Sleep_Pending" 4 "Sleep_Active" 5 "ERROR" ;
VAL_ 1477 MLU_1_OD_CAN2_autoErrorReset 0 "Disabled" 1 "Enabled" ;
VAL_ 1477 MLU_1_OD_CAN2_lastErrorCode 0 "No Error" 1 "Stuff Error" 2 "Form Error" 3 "Ack Error" 4 "Bit recessive Error" 5 "Bit dominant Error" 6 "CRC Error" ;
VAL_ 1477 MLU_1_OD_CAN1_ErrorStatus 0 "Ok" 1 "Warn" 2 "Error Passive" 3 "Bus Off" ;
VAL_ 1477 MLU_1_OD_CAN1_Status 0 "Reset" 1 "Ready" 2 "Listening" 3 "Sleep_Pending" 4 "Sleep_Active" 5 "ERROR" ;
VAL_ 1477 MLU_1_OD_CAN1_autoErrorReset 0 "Disabled" 1 "Enabled" ;
VAL_ 1477 MLU_1_OD_CAN1_lastErrorCode 0 "No Error" 1 "Stuff Error" 2 "Form Error" 3 "Ack Error" 4 "Bit recessive Error" 5 "Bit dominant Error" 6 "CRC Error" ;
VAL_ 1477 MLU_1_OD_SendOdOnBootup 0 "Disabled" 1 "Enabled" ;
VAL_ 1477 MLU_1_OD_NodeStatus 0 "Bootup" 4 "Stopped" 5 "Operational" 127 "Pre-Operational" 128 "Reset" ;
VAL_ 1477 MLU_1_SDO_ID 0 "Reserved" 1 "NodeID" 2 "NodeStatus" 3 "ProtocolVersion" 4 "StackVersion" 5 "DbcVersion" 16 "HeartbeatInterval" 32 "SendOdOnBootup" 33 "OdEntrySendInterval" 1040 "CpuUsage" 1041 "MemFree" 1042 "BoardTemp" 1043 "InputVoltage" 1044 "runtime" 1045 "SdcIn" 1046 "SdcOut" 1056 "ChipUID1" 1057 "ChipUID2" 1072 "BuildDate" 1073 "BuildTime" 1104 "CAN1_TxErrCnt" 1105 "CAN1_RxErrCnt" 1106 "CAN1_lastErrorCode" 1107 "CAN1_autoErrorReset" 1108 "CAN1_Baudrate" 1110 "CAN1_Status" 1111 "CAN1_DiscardedTxMessages" 1112 "CAN1_ErrorStatus" 1113 "CAN1_DelayedTxMessages" 1120 "CAN2_TxErrCnt" 1121 "CAN2_RxErrCnt" 1122 "CAN2_lastErrorCode" 1123 "CAN2_autoErrorReset" 1124 "CAN2_Baudrate" 1126 "CAN2_Status" 1127 "CAN2_DiscardedTxMessages" 1128 "CAN2_ErrorStatus" 1129 "CAN2_DelayedTxMessages" ;
VAL_ 1541 MLU_1_SDO_ID 0 "Reserved" 1 "NodeID" 2 "NodeStatus" 3 "ProtocolVersion" 4 "StackVersion" 5 "DbcVersion" 16 "HeartbeatInterval" 32 "SendOdOnBootup" 33 "OdEntrySendInterval" 1040 "CpuUsage" 1041 "MemFree" 1042 "BoardTemp" 1043 "InputVoltage" 1044 "runtime" 1045 "SdcIn" 1046 "SdcOut" 1056 "ChipUID1" 1057 "ChipUID2" 1072 "BuildDate" 1073 "BuildTime" 1104 "CAN1_TxErrCnt" 1105 "CAN1_RxErrCnt" 1106 "CAN1_lastErrorCode" 1107 "CAN1_autoErrorReset" 1108 "CAN1_Baudrate" 1110 "CAN1_Status" 1111 "CAN1_DiscardedTxMessages" 1112 "CAN1_ErrorStatus" 1113 "CAN1_DelayedTxMessages" 1120 "CAN2_TxErrCnt" 1121 "CAN2_RxErrCnt" 1122 "CAN2_lastErrorCode" 1123 "CAN2_autoErrorReset" 1124 "CAN2_Baudrate" 1126 "CAN2_Status" 1127 "CAN2_DiscardedTxMessages" 1128 "CAN2_ErrorStatus" 1129 "CAN2_DelayedTxMessages" ;
VAL_ 1797 MLU_1_NodeState 0 "Bootup" 4 "Stopped" 5 "Operational" 127 "Pre-Operational" ;
